VERSION ""

NS_ :

BS_:

BU_: DSAU vHS_M SHVU_RR DPSS AMP ICC RLPSM APSM RWPC RRHV RRPSM CGW_CCU APSS ATS RLHV FPM RDC PSM ASAU

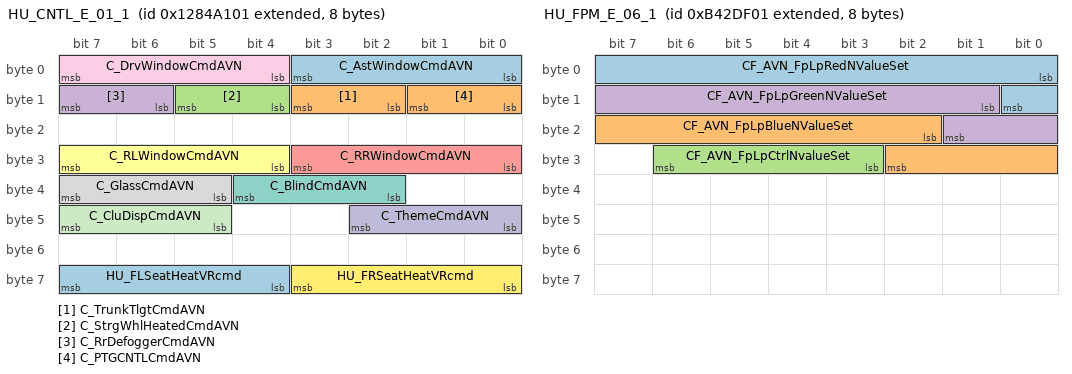
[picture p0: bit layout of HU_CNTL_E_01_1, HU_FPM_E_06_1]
BO_ 2458165505 HU_CNTL_E_01_1: 8 CGW_CCU
 SG_ C_AstWindowCmdAVN : 0|4@1+ (1,0) [0|0] ""  Vector__XXX
 SG_ C_TrunkTlgtCmdAVN : 10|2@1+ (1,0) [0|0] ""  Vector__XXX
 SG_ C_StrgWhlHeatedCmdAVN : 12|2@1+ (1,0) [0|0] ""  Vector__XXX
 SG_ C_RrDefoggerCmdAVN : 14|2@1+ (1,0) [0|0] ""  Vector__XXX
 SG_ C_RRWindowCmdAVN : 24|4@1+ (1,0) [0|0] ""  RDC
 SG_ C_RLWindowCmdAVN : 28|4@1+ (1,0) [0|0] ""  RDC
 SG_ C_BlindCmdAVN : 34|3@1+ (1,0) [0|0] ""  Vector__XXX
 SG_ C_GlassCmdAVN : 37|3@1+ (1,0) [0|0] ""  Vector__XXX
 SG_ C_DrvWindowCmdAVN : 4|4@1+ (1,0) [0|0] ""  Vector__XXX
 SG_ C_ThemeCmdAVN : 40|3@1+ (1,0) [0|0] ""  Vector__XXX
 SG_ C_CluDispCmdAVN : 45|3@1+ (1,0) [0|0] ""  Vector__XXX
 SG_ HU_FRSeatHeatVRcmd : 56|4@1+ (1,0) [0|0] ""  SHVU_RR,DPSS,ATS
 SG_ HU_FLSeatHeatVRcmd : 60|4@1+ (1,0) [0|0] ""  DPSS,ATS
 SG_ C_PTGCNTLCmdAVN : 8|2@1+ (1,0) [0|0] ""  Vector__XXX

BO_ 2336415489 HU_FPM_E_06_1: 8 CGW_CCU
 SG_ CF_AVN_FpLpRedNValueSet : 0|9@1+ (1,0) [0|0] ""  FPM
 SG_ CF_AVN_FpLpBlueNValueSet : 18|9@1+ (1,0) [0|0] ""  FPM
 SG_ CF_AVN_FpLpCtrlNvalueSet : 27|4@1+ (1,0) [0|0] ""  FPM
 SG_ CF_AVN_FpLpGreenNValueSet : 9|9@1+ (1,0) [0|0] ""  FPM

BO_ 2315420417 HU_FPM_E_03_1: 8 CGW_CCU
 SG_ AVN_Encrypted_Result3 : 0|64@1+ (1,0) [0|0] ""  FPM

BO_ 858 SBCM_AST_02_200ms: 8 CGW_CCU
 SG_ SBCM_AST_Crc2Val : 0|8@1+ (1,0) [0|0] ""  Vector__XXX
 SG_ AST_CrashUnlockCmd : 10|1@1+ (1,0) [0|0] ""  Vector__XXX
 SG_ SBCM_AST_AlvCnt2Val : 12|4@1+ (1,0) [0|0] ""  Vector__XXX
 SG_ DoorLock_CtrlDrLkSwSta_SBCM : 16|2@1+ (1,0) [0|0] ""  Vector__XXX
 SG_ DoorLock_CtrlDrUnLkSwSta_SBCM : 18|2@1+ (1,0) [0|0] ""  Vector__XXX
 SG_ Warn_AsstDrSwSta_SBCM : 20|2@1+ (1,0) [0|0] ""  RWPC,APSM,AMP,ATS
 SG_ DoorLock_AsstDrUnLkSta_SBCM : 22|2@1+ (1,0) [0|0] ""  ATS
 SG_ AST_SEAWarn_RH : 24|2@1+ (1,0) [0|0] ""  AMP
 SG_ AST_SEAWarn_LH : 26|2@1+ (1,0) [0|0] ""  AMP
 SG_ AST_SEWWarn_LH : 28|2@1+ (1,0) [0|0] ""  AMP
 SG_ AST_SEWWarn_RH : 30|2@1+ (1,0) [0|0] ""  AMP
 SG_ AST_MRActivationAlarm : 32|2@1+ (1,0) [0|0] ""  Vector__XXX
 SG_ AST_ReleaseWarn : 34|2@1+ (1,0) [0|0] ""  Vector__XXX
 SG_ USM_AstGhostDoorSta : 36|2@1+ (1,0) [0|0] ""  Vector__XXX
 SG_ AST_SWFailAlarm : 38|2@1+ (1,0) [0|0] ""  Vector__XXX
 SG_ DoorLock_PDSLkSwSta_AST : 40|2@1+ (1,0) [0|0] ""  AMP
 SG_ PDS_TypeOption_AST : 42|2@1+ (1,0) [0|0] ""  Vector__XXX
 SG_ ASTDoorPushAlarm : 8|2@1+ (1,0) [0|0] ""  Vector__XXX

BO_ 383 FPM_05_00ms: 8 FPM
 SG_ FPM_Encrypted_Result4 : 0|64@1+ (1,0) [0|0] ""  CGW_CCU

BO_ 862 SBCM_RL_01_200ms: 8 CGW_CCU
 SG_ SBCM_RL_Crc1Val : 0|8@1+ (1,0) [0|0] ""  Vector__XXX
 SG_ RL_CrashUnlockCmd : 10|1@1+ (1,0) [0|0] ""  Vector__XXX
 SG_ SBCM_RL_AlvCnt1Val : 12|4@1+ (1,0) [0|0] ""  Vector__XXX
 SG_ Warn_RrLftDrSwSta_SBCM : 16|2@1+ (1,0) [0|0] ""  RWPC,RLPSM,AMP,ATS
 SG_ DoorLock_RrLftDrUnLkSta_SBCM : 18|2@1+ (1,0) [0|0] ""  ATS
 SG_ RL_SEAActivated : 20|2@1+ (1,0) [0|0] ""  Vector__XXX
 SG_ RL_SEAWarn : 22|2@1+ (1,0) [0|0] ""  AMP
 SG_ RL_SEWWarn : 24|2@1+ (1,0) [0|0] ""  AMP
 SG_ RL_ReleaseWarn : 26|2@1+ (1,0) [0|0] ""  Vector__XXX
 SG_ RL_SWFailAlarm : 28|2@1+ (1,0) [0|0] ""  Vector__XXX
 SG_ RL_ChildLock_ActnFlSta : 30|2@1+ (1,0) [0|0] ""  Vector__XXX
 SG_ RL_MRActivationAlarm : 32|2@1+ (1,0) [0|0] ""  Vector__XXX
 SG_ RL_ChildLock_Status : 34|2@1+ (1,0) [0|0] ""  Vector__XXX
 SG_ USM_RLGhostDoorSta : 36|2@1+ (1,0) [0|0] ""  Vector__XXX
 SG_ DoorLock_PDSLkSwSta_RL : 40|2@1+ (1,0) [0|0] ""  AMP
 SG_ PDS_TypeOption_RL : 42|2@1+ (1,0) [0|0] ""  Vector__XXX
 SG_ SBCM_RrLtClsSwSta : 44|2@1+ (1,0) [0|0] ""  Vector__XXX
 SG_ RLDoorPushAlarm : 8|2@1+ (1,0) [0|0] ""  Vector__XXX

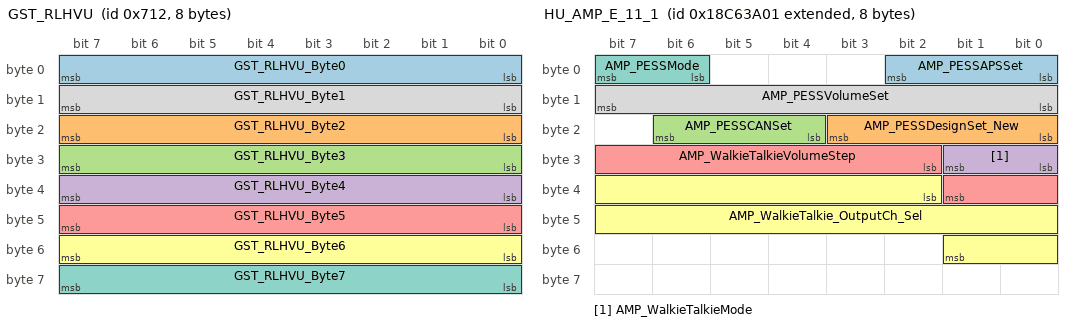
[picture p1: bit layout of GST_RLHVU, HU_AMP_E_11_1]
BO_ 1810 GST_RLHVU: 8 CGW_CCU
 SG_ GST_RLHVU_Byte0 : 0|8@1+ (1,0) [0|0] ""  RLHV,vHS_M
 SG_ GST_RLHVU_Byte2 : 16|8@1+ (1,0) [0|0] ""  RLHV,vHS_M
 SG_ GST_RLHVU_Byte3 : 24|8@1+ (1,0) [0|0] ""  RLHV,vHS_M
 SG_ GST_RLHVU_Byte4 : 32|8@1+ (1,0) [0|0] ""  RLHV,vHS_M
 SG_ GST_RLHVU_Byte5 : 40|8@1+ (1,0) [0|0] ""  RLHV,vHS_M
 SG_ GST_RLHVU_Byte6 : 48|8@1+ (1,0) [0|0] ""  RLHV,vHS_M
 SG_ GST_RLHVU_Byte7 : 56|8@1+ (1,0) [0|0] ""  RLHV,vHS_M
 SG_ GST_RLHVU_Byte1 : 8|8@1+ (1,0) [0|0] ""  RLHV,vHS_M

BO_ 2563127809 HU_AMP_E_11_1: 8 CGW_CCU
 SG_ AMP_PESSAPSSet : 0|3@1+ (1,0) [0|0] ""  Vector__XXX
 SG_ AMP_PESSDesignSet_New : 16|4@1+ (1,0) [0|0] ""  Vector__XXX
 SG_ AMP_PESSCANSet : 20|3@1+ (1,0) [0|0] ""  Vector__XXX
 SG_ AMP_WalkieTalkieMode : 24|2@1+ (1,0) [0|0] ""  AMP
 SG_ AMP_WalkieTalkieVolumeStep : 26|8@1+ (1,0) [0|0] ""  AMP
 SG_ AMP_WalkieTalkie_OutputCh_Sel : 34|16@1+ (1,0) [0|0] ""  AMP
 SG_ AMP_PESSMode : 6|2@1+ (1,0) [0|0] ""  Vector__XXX
 SG_ AMP_PESSVolumeSet : 8|8@1+ (1,0) [0|0] ""  Vector__XXX

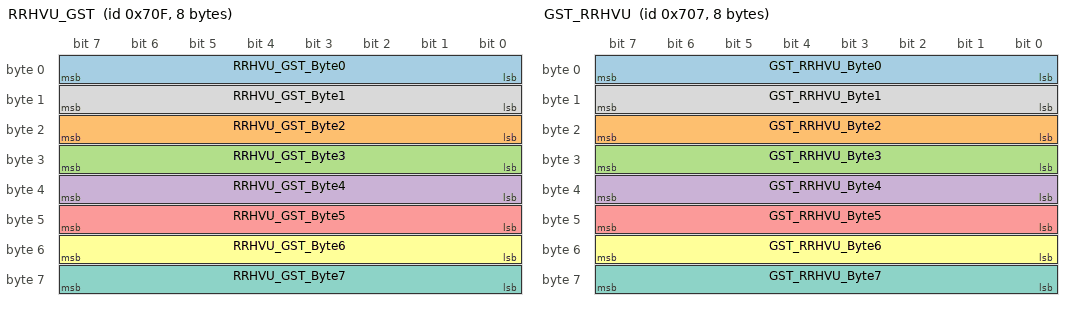
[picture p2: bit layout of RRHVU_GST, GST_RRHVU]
BO_ 1807 RRHVU_GST: 8 vHS_M
 SG_ RRHVU_GST_Byte0 : 0|8@1+ (1,0) [0|0] ""  CGW_CCU
 SG_ RRHVU_GST_Byte2 : 16|8@1+ (1,0) [0|0] ""  CGW_CCU
 SG_ RRHVU_GST_Byte3 : 24|8@1+ (1,0) [0|0] ""  CGW_CCU
 SG_ RRHVU_GST_Byte4 : 32|8@1+ (1,0) [0|0] ""  CGW_CCU
 SG_ RRHVU_GST_Byte5 : 40|8@1+ (1,0) [0|0] ""  CGW_CCU
 SG_ RRHVU_GST_Byte6 : 48|8@1+ (1,0) [0|0] ""  CGW_CCU
 SG_ RRHVU_GST_Byte7 : 56|8@1+ (1,0) [0|0] ""  CGW_CCU
 SG_ RRHVU_GST_Byte1 : 8|8@1+ (1,0) [0|0] ""  CGW_CCU

BO_ 1799 GST_RRHVU: 8 CGW_CCU
 SG_ GST_RRHVU_Byte0 : 0|8@1+ (1,0) [0|0] ""  RRHV,SHVU_RR,vHS_M
 SG_ GST_RRHVU_Byte2 : 16|8@1+ (1,0) [0|0] ""  RRHV,SHVU_RR,vHS_M
 SG_ GST_RRHVU_Byte3 : 24|8@1+ (1,0) [0|0] ""  RRHV,SHVU_RR,vHS_M
 SG_ GST_RRHVU_Byte4 : 32|8@1+ (1,0) [0|0] ""  RRHV,SHVU_RR,vHS_M
 SG_ GST_RRHVU_Byte5 : 40|8@1+ (1,0) [0|0] ""  RRHV,SHVU_RR,vHS_M
 SG_ GST_RRHVU_Byte6 : 48|8@1+ (1,0) [0|0] ""  RRHV,SHVU_RR,vHS_M
 SG_ GST_RRHVU_Byte7 : 56|8@1+ (1,0) [0|0] ""  RRHV,SHVU_RR,vHS_M
 SG_ GST_RRHVU_Byte1 : 8|8@1+ (1,0) [0|0] ""  RRHV,SHVU_RR,vHS_M

BO_ 367 FPM_04_00ms: 8 FPM
 SG_ FPM2IAU_ISKLearnFdbck : 0|4@1+ (1,0) [0|0] ""  CGW_CCU

BO_ 415 FPM_07_200ms: 8 FPM
 SG_ FPM_FPFuntionEnableRValue : 0|2@1+ (1,0) [0|0] ""  CGW_CCU
 SG_ FPM_User2_SecondFPRValue : 10|2@1+ (1,0) [0|0] ""  CGW_CCU
 SG_ FPM_User2_ThirdFPRValue : 12|2@1+ (1,0) [0|0] ""  CGW_CCU
 SG_ FPM_FPEnrollState : 16|4@1+ (1,0) [0|0] ""  CGW_CCU
 SG_ FPM_User1_FirstFPRValue : 2|2@1+ (1,0) [0|0] ""  CGW_CCU
 SG_ FPM_FPDeleteState : 20|2@1+ (1,0) [0|0] ""  CGW_CCU
 SG_ FPM_EnrollProgress : 24|8@1+ (1,0) [0|0] ""  CGW_CCU
 SG_ FPM_ISKLearnState : 33|3@1+ (1,0) [0|0] ""  CGW_CCU
 SG_ FPM_ReadyToSendData : 36|2@1+ (1,0) [0|0] ""  CGW_CCU
 SG_ FPM_Option : 38|2@1+ (1,0) [0|0] ""  CGW_CCU
 SG_ FPM_User1_SecondFPRValue : 4|2@1+ (1,0) [0|0] ""  CGW_CCU
 SG_ FPMwIAULearnState : 40|3@1+ (1,0) [0|0] ""  CGW_CCU
 SG_ FPM_DISPWrng : 43|5@1+ (1,0) [0|0] ""  CGW_CCU
 SG_ FPM2IAU_RdyToSendAuthData : 48|2@1+ (1,0) [0|0] ""  CGW_CCU
 SG_ FPM_FPStartUseRvalue : 50|2@1+ (1,0) [0|0] ""  CGW_CCU
 SG_ FPM_FPStartUseState : 52|2@1+ (1,0) [0|0] ""  CGW_CCU
 SG_ FPM_User1_ThirdFPRValue : 6|2@1+ (1,0) [0|0] ""  CGW_CCU
 SG_ FPM_User2_FirstFPRValue : 8|2@1+ (1,0) [0|0] ""  CGW_CCU

BO_ 2319620609 HUD_01_100ms_1: 8 CGW_CCU
 SG_ HUD_PbackSta : 29|3@1+ (1,0) [0|0] ""  PSM

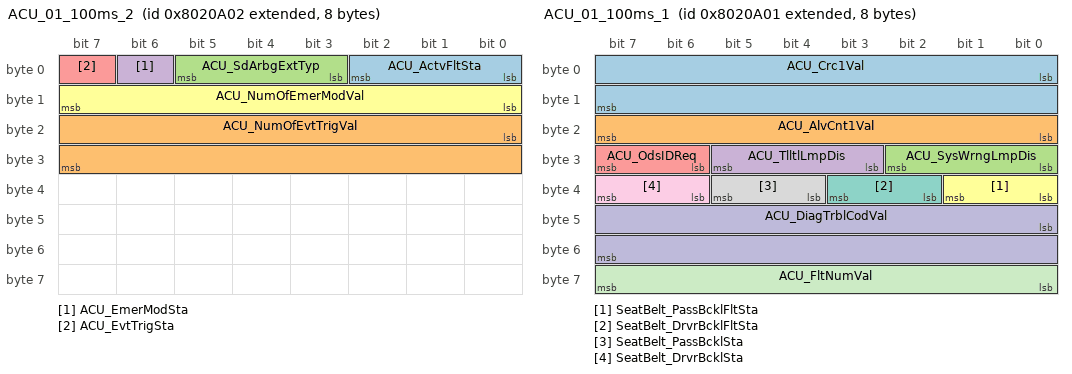
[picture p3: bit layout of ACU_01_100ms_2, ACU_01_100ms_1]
BO_ 2281835010 ACU_01_100ms_2: 8 CGW_CCU
 SG_ ACU_ActvFltSta : 0|3@1+ (1,0) [0|0] ""  Vector__XXX
 SG_ ACU_NumOfEvtTrigVal : 16|16@1+ (1,0) [0|0] ""  Vector__XXX
 SG_ ACU_SdArbgExtTyp : 3|3@1+ (1,0) [0|0] ""  Vector__XXX
 SG_ ACU_EmerModSta : 6|1@1+ (1,0) [0|0] ""  Vector__XXX
 SG_ ACU_EvtTrigSta : 7|1@1+ (1,0) [0|0] ""  Vector__XXX
 SG_ ACU_NumOfEmerModVal : 8|8@1+ (1,0) [0|0] ""  Vector__XXX

BO_ 2281835009 ACU_01_100ms_1: 8 CGW_CCU
 SG_ ACU_Crc1Val : 0|16@1+ (1,0) [0|0] ""  Vector__XXX
 SG_ ACU_AlvCnt1Val : 16|8@1+ (1,0) [0|0] ""  Vector__XXX
 SG_ ACU_SysWrngLmpDis : 24|3@1+ (1,0) [0|0] ""  Vector__XXX
 SG_ ACU_TlltlLmpDis : 27|3@1+ (1,0) [0|0] ""  Vector__XXX
 SG_ ACU_OdsIDReq : 30|2@1+ (1,0) [0|0] ""  Vector__XXX
 SG_ SeatBelt_PassBcklFltSta : 32|2@1+ (1,0) [0|0] ""  Vector__XXX
 SG_ SeatBelt_DrvrBcklFltSta : 34|2@1+ (1,0) [0|0] ""  Vector__XXX
 SG_ SeatBelt_PassBcklSta : 36|2@1+ (1,0) [0|0] ""  APSM,ATS
 SG_ SeatBelt_DrvrBcklSta : 38|2@1+ (1,0) [0|0] ""  PSM
 SG_ ACU_DiagTrblCodVal : 40|16@1+ (1,0) [0|0] ""  Vector__XXX
 SG_ ACU_FltNumVal : 56|8@1+ (1,0) [0|0] ""  Vector__XXX

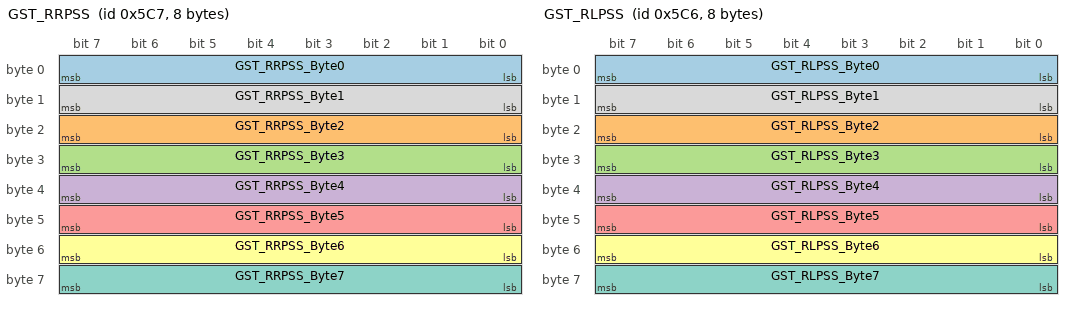
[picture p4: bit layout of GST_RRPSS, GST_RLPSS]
BO_ 1479 GST_RRPSS: 8 CGW_CCU
 SG_ GST_RRPSS_Byte0 : 0|8@1+ (1,0) [0|0] ""  RLPSM,vHS_M
 SG_ GST_RRPSS_Byte2 : 16|8@1+ (1,0) [0|0] ""  RLPSM,vHS_M
 SG_ GST_RRPSS_Byte3 : 24|8@1+ (1,0) [0|0] ""  RLPSM,vHS_M
 SG_ GST_RRPSS_Byte4 : 32|8@1+ (1,0) [0|0] ""  RLPSM,vHS_M
 SG_ GST_RRPSS_Byte5 : 40|8@1+ (1,0) [0|0] ""  RLPSM,vHS_M
 SG_ GST_RRPSS_Byte6 : 48|8@1+ (1,0) [0|0] ""  RLPSM,vHS_M
 SG_ GST_RRPSS_Byte7 : 56|8@1+ (1,0) [0|0] ""  RLPSM,vHS_M
 SG_ GST_RRPSS_Byte1 : 8|8@1+ (1,0) [0|0] ""  RLPSM,vHS_M

BO_ 1478 GST_RLPSS: 8 CGW_CCU
 SG_ GST_RLPSS_Byte0 : 0|8@1+ (1,0) [0|0] ""  RLPSM,vHS_M
 SG_ GST_RLPSS_Byte2 : 16|8@1+ (1,0) [0|0] ""  RLPSM,vHS_M
 SG_ GST_RLPSS_Byte3 : 24|8@1+ (1,0) [0|0] ""  RLPSM,vHS_M
 SG_ GST_RLPSS_Byte4 : 32|8@1+ (1,0) [0|0] ""  RLPSM,vHS_M
 SG_ GST_RLPSS_Byte5 : 40|8@1+ (1,0) [0|0] ""  RLPSM,vHS_M
 SG_ GST_RLPSS_Byte6 : 48|8@1+ (1,0) [0|0] ""  RLPSM,vHS_M
 SG_ GST_RLPSS_Byte7 : 56|8@1+ (1,0) [0|0] ""  RLPSM,vHS_M
 SG_ GST_RLPSS_Byte1 : 8|8@1+ (1,0) [0|0] ""  RLPSM,vHS_M

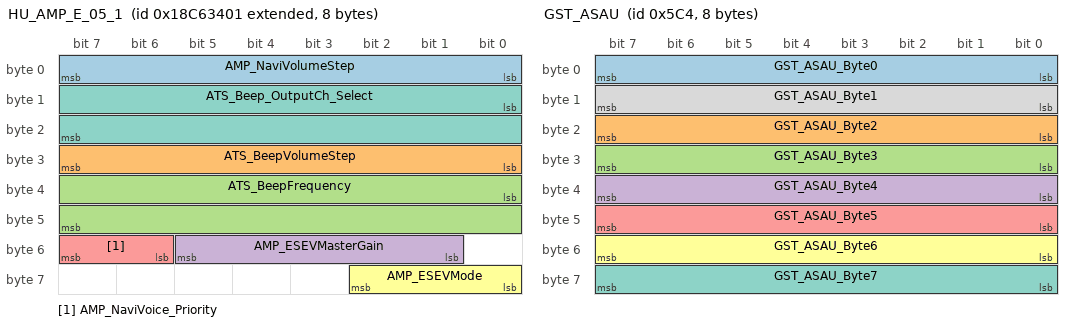
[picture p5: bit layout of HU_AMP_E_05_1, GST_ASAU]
BO_ 2563126273 HU_AMP_E_05_1: 8 CGW_CCU
 SG_ AMP_NaviVolumeStep : 0|8@1+ (1,0) [0|0] ""  AMP
 SG_ ATS_BeepVolumeStep : 24|8@1+ (1,0) [0|0] ""  AMP
 SG_ ATS_BeepFrequency : 32|16@1+ (1,0) [0|0] "Hz"  AMP
 SG_ AMP_ESEVMasterGain : 49|5@1+ (0.5,-8) [0|0] ""  AMP
 SG_ AMP_NaviVoice_Priority : 54|2@1+ (1,0) [0|0] ""  AMP
 SG_ AMP_ESEVMode : 56|3@1+ (1,0) [0|0] ""  AMP
 SG_ ATS_Beep_OutputCh_Select : 8|16@1+ (1,0) [0|0] ""  AMP

BO_ 1476 GST_ASAU: 8 CGW_CCU
 SG_ GST_ASAU_Byte0 : 0|8@1+ (1,0) [0|0] ""  vHS_M,ASAU
 SG_ GST_ASAU_Byte2 : 16|8@1+ (1,0) [0|0] ""  vHS_M,ASAU
 SG_ GST_ASAU_Byte3 : 24|8@1+ (1,0) [0|0] ""  vHS_M,ASAU
 SG_ GST_ASAU_Byte4 : 32|8@1+ (1,0) [0|0] ""  vHS_M,ASAU
 SG_ GST_ASAU_Byte5 : 40|8@1+ (1,0) [0|0] ""  vHS_M,ASAU
 SG_ GST_ASAU_Byte6 : 48|8@1+ (1,0) [0|0] ""  vHS_M,ASAU
 SG_ GST_ASAU_Byte7 : 56|8@1+ (1,0) [0|0] ""  vHS_M,ASAU
 SG_ GST_ASAU_Byte1 : 8|8@1+ (1,0) [0|0] ""  vHS_M,ASAU

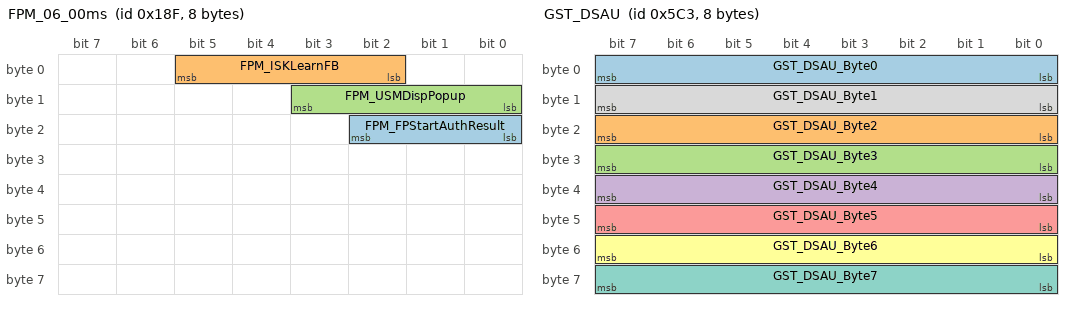
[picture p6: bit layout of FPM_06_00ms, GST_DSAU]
BO_ 399 FPM_06_00ms: 8 FPM
 SG_ FPM_FPStartAuthResult : 16|3@1+ (1,0) [0|0] ""  CGW_CCU
 SG_ FPM_ISKLearnFB : 2|4@1+ (1,0) [0|0] ""  CGW_CCU
 SG_ FPM_USMDispPopup : 8|4@1+ (1,0) [0|0] ""  CGW_CCU

BO_ 1475 GST_DSAU: 8 CGW_CCU
 SG_ GST_DSAU_Byte0 : 0|8@1+ (1,0) [0|0] ""  vHS_M,DSAU
 SG_ GST_DSAU_Byte2 : 16|8@1+ (1,0) [0|0] ""  vHS_M,DSAU
 SG_ GST_DSAU_Byte3 : 24|8@1+ (1,0) [0|0] ""  vHS_M,DSAU
 SG_ GST_DSAU_Byte4 : 32|8@1+ (1,0) [0|0] ""  vHS_M,DSAU
 SG_ GST_DSAU_Byte5 : 40|8@1+ (1,0) [0|0] ""  vHS_M,DSAU
 SG_ GST_DSAU_Byte6 : 48|8@1+ (1,0) [0|0] ""  vHS_M,DSAU
 SG_ GST_DSAU_Byte7 : 56|8@1+ (1,0) [0|0] ""  vHS_M,DSAU
 SG_ GST_DSAU_Byte1 : 8|8@1+ (1,0) [0|0] ""  vHS_M,DSAU

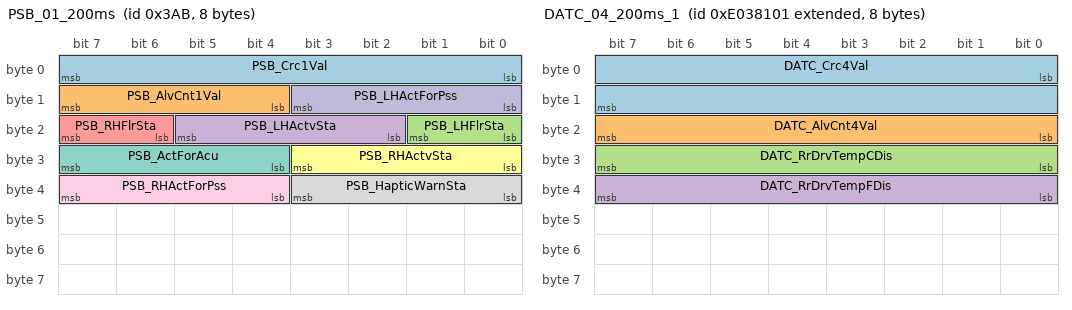
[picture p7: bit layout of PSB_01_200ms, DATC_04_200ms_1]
BO_ 939 PSB_01_200ms: 8 CGW_CCU
 SG_ PSB_Crc1Val : 0|8@1+ (1,0) [0|0] ""  Vector__XXX
 SG_ PSB_AlvCnt1Val : 12|4@1+ (1,0) [0|0] ""  Vector__XXX
 SG_ PSB_LHFlrSta : 16|2@1+ (1,0) [0|0] ""  Vector__XXX
 SG_ PSB_LHActvSta : 18|4@1+ (1,0) [0|0] ""  Vector__XXX
 SG_ PSB_RHFlrSta : 22|2@1+ (1,0) [0|0] ""  Vector__XXX
 SG_ PSB_RHActvSta : 24|4@1+ (1,0) [0|0] ""  Vector__XXX
 SG_ PSB_ActForAcu : 28|4@1+ (1,0) [0|0] ""  Vector__XXX
 SG_ PSB_HapticWarnSta : 32|4@1+ (1,0) [0|0] ""  Vector__XXX
 SG_ PSB_RHActForPss : 36|4@1+ (1,0) [0|0] ""  APSM,RLPSM,RRPSM
 SG_ PSB_LHActForPss : 8|4@1+ (1,0) [0|0] ""  RLPSM,RRPSM

BO_ 2382594305 DATC_04_200ms_1: 8 CGW_CCU
 SG_ DATC_Crc4Val : 0|16@1+ (1,0) [0|0] ""  Vector__XXX
 SG_ DATC_AlvCnt4Val : 16|8@1+ (1,0) [0|0] ""  Vector__XXX
 SG_ DATC_RrDrvTempCDis : 24|8@1+ (0.5,14) [0|0] "℃"  ATS
 SG_ DATC_RrDrvTempFDis : 32|8@1+ (1,56) [0|0] "℉"  ATS

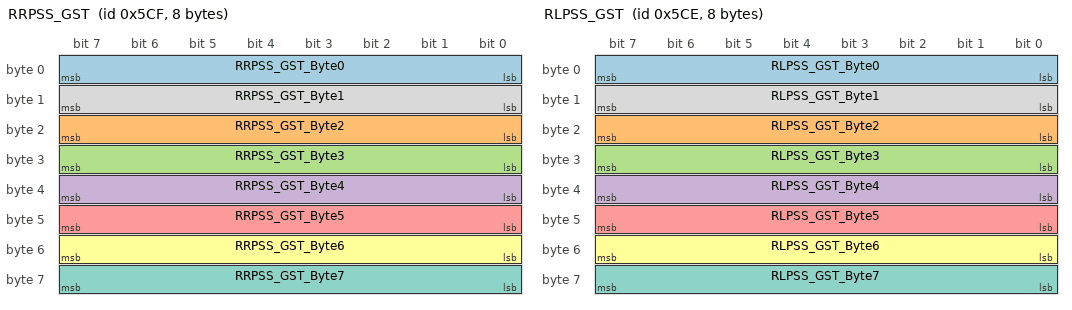
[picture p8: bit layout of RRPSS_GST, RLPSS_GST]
BO_ 1487 RRPSS_GST: 8 vHS_M
 SG_ RRPSS_GST_Byte0 : 0|8@1+ (1,0) [0|0] ""  CGW_CCU
 SG_ RRPSS_GST_Byte2 : 16|8@1+ (1,0) [0|0] ""  CGW_CCU
 SG_ RRPSS_GST_Byte3 : 24|8@1+ (1,0) [0|0] ""  CGW_CCU
 SG_ RRPSS_GST_Byte4 : 32|8@1+ (1,0) [0|0] ""  CGW_CCU
 SG_ RRPSS_GST_Byte5 : 40|8@1+ (1,0) [0|0] ""  CGW_CCU
 SG_ RRPSS_GST_Byte6 : 48|8@1+ (1,0) [0|0] ""  CGW_CCU
 SG_ RRPSS_GST_Byte7 : 56|8@1+ (1,0) [0|0] ""  CGW_CCU
 SG_ RRPSS_GST_Byte1 : 8|8@1+ (1,0) [0|0] ""  CGW_CCU

BO_ 1486 RLPSS_GST: 8 RLPSM
 SG_ RLPSS_GST_Byte0 : 0|8@1+ (1,0) [0|0] ""  CGW_CCU
 SG_ RLPSS_GST_Byte2 : 16|8@1+ (1,0) [0|0] ""  CGW_CCU
 SG_ RLPSS_GST_Byte3 : 24|8@1+ (1,0) [0|0] ""  CGW_CCU
 SG_ RLPSS_GST_Byte4 : 32|8@1+ (1,0) [0|0] ""  CGW_CCU
 SG_ RLPSS_GST_Byte5 : 40|8@1+ (1,0) [0|0] ""  CGW_CCU
 SG_ RLPSS_GST_Byte6 : 48|8@1+ (1,0) [0|0] ""  CGW_CCU
 SG_ RLPSS_GST_Byte7 : 56|8@1+ (1,0) [0|0] ""  CGW_CCU
 SG_ RLPSS_GST_Byte1 : 8|8@1+ (1,0) [0|0] ""  CGW_CCU

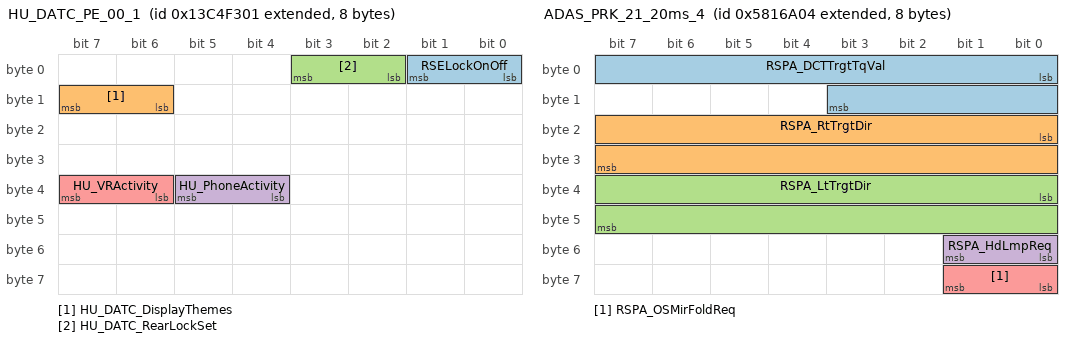
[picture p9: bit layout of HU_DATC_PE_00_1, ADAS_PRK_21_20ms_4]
BO_ 2479158017 HU_DATC_PE_00_1: 8 CGW_CCU
 SG_ RSELockOnOff : 0|2@1+ (1,0) [0|0] ""  ATS
 SG_ HU_DATC_DisplayThemes : 14|2@1+ (1,0) [0|0] ""  Vector__XXX
 SG_ HU_DATC_RearLockSet : 2|2@1+ (1,0) [0|0] ""  Vector__XXX
 SG_ HU_PhoneActivity : 36|2@1+ (1,0) [0|0] ""  Vector__XXX
 SG_ HU_VRActivity : 38|2@1+ (1,0) [0|0] ""  Vector__XXX

BO_ 2239851012 ADAS_PRK_21_20ms_4: 8 CGW_CCU
 SG_ RSPA_DCTTrgtTqVal : 0|12@1- (1,0) [0|0] "Nm"  Vector__XXX
 SG_ RSPA_RtTrgtDir : 16|16@1- (0.001,0) [0|0] "rad"  Vector__XXX
 SG_ RSPA_LtTrgtDir : 32|16@1- (0.001,0) [0|0] "rad"  Vector__XXX
 SG_ RSPA_HdLmpReq : 48|2@1+ (1,0) [0|0] ""  Vector__XXX
 SG_ RSPA_OSMirFoldReq : 56|2@1+ (1,0) [0|0] ""  Vector__XXX

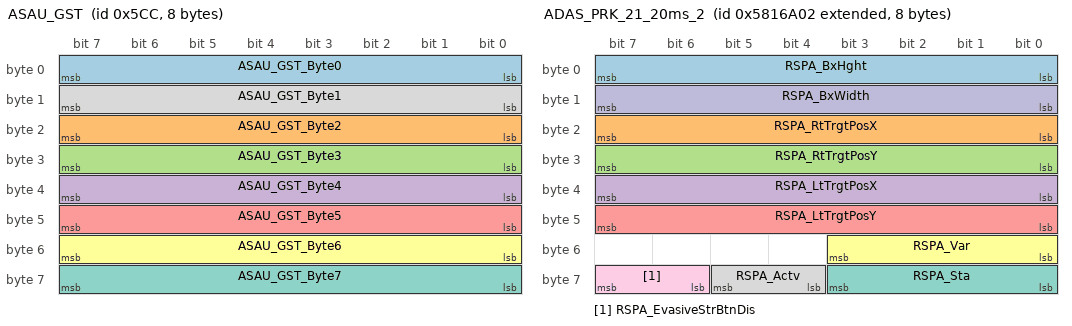
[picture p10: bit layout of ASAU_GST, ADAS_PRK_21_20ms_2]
BO_ 1484 ASAU_GST: 8 ASAU
 SG_ ASAU_GST_Byte0 : 0|8@1+ (1,0) [0|0] ""  CGW_CCU
 SG_ ASAU_GST_Byte2 : 16|8@1+ (1,0) [0|0] ""  CGW_CCU
 SG_ ASAU_GST_Byte3 : 24|8@1+ (1,0) [0|0] ""  CGW_CCU
 SG_ ASAU_GST_Byte4 : 32|8@1+ (1,0) [0|0] ""  CGW_CCU
 SG_ ASAU_GST_Byte5 : 40|8@1+ (1,0) [0|0] ""  CGW_CCU
 SG_ ASAU_GST_Byte6 : 48|8@1+ (1,0) [0|0] ""  CGW_CCU
 SG_ ASAU_GST_Byte7 : 56|8@1+ (1,0) [0|0] ""  CGW_CCU
 SG_ ASAU_GST_Byte1 : 8|8@1+ (1,0) [0|0] ""  CGW_CCU

BO_ 2239851010 ADAS_PRK_21_20ms_2: 8 CGW_CCU
 SG_ RSPA_BxHght : 0|8@1+ (10,3500) [0|0] ""  Vector__XXX
 SG_ RSPA_RtTrgtPosX : 16|8@1- (0.05,0) [0|0] "m"  Vector__XXX
 SG_ RSPA_RtTrgtPosY : 24|8@1- (0.05,0) [0|0] "m"  Vector__XXX
 SG_ RSPA_LtTrgtPosX : 32|8@1- (0.05,0) [0|0] "m"  Vector__XXX
 SG_ RSPA_LtTrgtPosY : 40|8@1- (0.05,0) [0|0] "m"  Vector__XXX
 SG_ RSPA_Var : 48|4@1+ (1,0) [0|0] ""  Vector__XXX
 SG_ RSPA_Sta : 56|4@1+ (1,0) [0|0] ""  Vector__XXX
 SG_ RSPA_Actv : 60|2@1+ (1,0) [0|0] ""  Vector__XXX
 SG_ RSPA_EvasiveStrBtnDis : 62|2@1+ (1,0) [0|0] ""  Vector__XXX
 SG_ RSPA_BxWidth : 8|8@1+ (5,1000) [0|0] ""  Vector__XXX

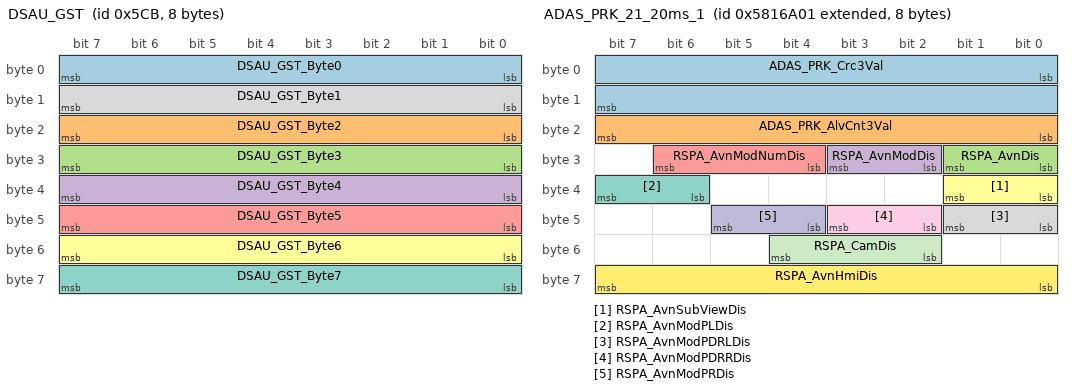
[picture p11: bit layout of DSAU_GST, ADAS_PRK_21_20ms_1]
BO_ 1483 DSAU_GST: 8 vHS_M
 SG_ DSAU_GST_Byte0 : 0|8@1+ (1,0) [0|0] ""  CGW_CCU
 SG_ DSAU_GST_Byte2 : 16|8@1+ (1,0) [0|0] ""  CGW_CCU
 SG_ DSAU_GST_Byte3 : 24|8@1+ (1,0) [0|0] ""  CGW_CCU
 SG_ DSAU_GST_Byte4 : 32|8@1+ (1,0) [0|0] ""  CGW_CCU
 SG_ DSAU_GST_Byte5 : 40|8@1+ (1,0) [0|0] ""  CGW_CCU
 SG_ DSAU_GST_Byte6 : 48|8@1+ (1,0) [0|0] ""  CGW_CCU
 SG_ DSAU_GST_Byte7 : 56|8@1+ (1,0) [0|0] ""  CGW_CCU
 SG_ DSAU_GST_Byte1 : 8|8@1+ (1,0) [0|0] ""  CGW_CCU

BO_ 2298626305 HU_APSU_PE_02_1: 8 CGW_CCU
 SG_ C_AstBolsterInfSw_HU : 0|2@1+ (1,0) [0|0] ""  APSS,ASAU
 SG_ C_RLHrestUpSw_HU : 14|2@1+ (1,0) [0|0] ""  RLPSM
 SG_ C_RLHrestDnSw_HU : 16|2@1+ (1,0) [0|0] ""  RLPSM
 SG_ C_RLHrestFwdSw_HU : 18|2@1+ (1,0) [0|0] ""  RLPSM
 SG_ C_AstBolsterDefSw_HU : 2|2@1+ (1,0) [0|0] ""  APSS,ASAU
 SG_ C_RLHrestBwdSw_HU : 20|2@1+ (1,0) [0|0] ""  RLPSM
 SG_ C_RLLumbarUpSw_HU : 22|2@1+ (1,0) [0|0] ""  RLPSM
 SG_ C_RLLumbarMidSw_HU : 24|2@1+ (1,0) [0|0] ""  RLPSM
 SG_ C_RLLumbarLowSw_HU : 26|2@1+ (1,0) [0|0] ""  RLPSM
 SG_ C_RLLumbarDefSw_HU : 28|2@1+ (1,0) [0|0] ""  RLPSM
 SG_ C_RLBolsterInfSw_HU : 30|2@1+ (1,0) [0|0] ""  RLPSM
 SG_ C_RLBolsterDefSw_HU : 32|2@1+ (1,0) [0|0] ""  RLPSM
 SG_ C_AstHrestUpSw_HU : 36|2@1+ (1,0) [0|0] ""  APSM,APSS
 SG_ C_AstHrestDnSw_HU : 38|2@1+ (1,0) [0|0] ""  APSM,APSS
 SG_ C_AstFootrestFldSw_HU : 4|2@1+ (1,0) [0|0] ""  APSM,APSS
 SG_ C_AstHrestFwdSw_HU : 46|2@1+ (1,0) [0|0] ""  APSM,APSS
 SG_ C_AstHrestBwdSw_HU : 54|2@1+ (1,0) [0|0] ""  APSM,APSS
 SG_ C_AstFootrestUnFldSw_HU : 6|2@1+ (1,0) [0|0] ""  APSM,APSS

BO_ 2239851011 ADAS_PRK_21_20ms_3: 8 CGW_CCU
 SG_ RSPA_TrgtGearSta : 0|3@1+ (1,0) [0|0] ""  Vector__XXX
 SG_ RSPA_IdOutWarnReq : 10|2@1+ (1,0) [0|0] ""  PSM
 SG_ RSPA_IndBlnkReq : 12|3@1+ (1,0) [0|0] ""  Vector__XXX
 SG_ RSPA_SysOff : 15|1@1+ (1,0) [0|0] ""  Vector__XXX
 SG_ RSPA_DccCmd : 16|2@1+ (1,0) [0|0] ""  Vector__XXX
 SG_ RSPA_StopReq : 18|2@1+ (1,0) [0|0] ""  Vector__XXX
 SG_ RSPA_SelDevInfo : 20|2@1+ (1,0) [0|0] ""  Vector__XXX
 SG_ RSPA_SelFuncInfo : 22|2@1+ (1,0) [0|0] ""  Vector__XXX
 SG_ RSPA_TrgtVehSpdVal : 24|10@1+ (0.01,0) [0|0] "km/h"  Vector__XXX
 SG_ RSPA_EpbReq : 3|2@1+ (1,0) [0|0] ""  Vector__XXX
 SG_ RSPA_AddtnlAccelActv : 34|2@1+ (1,0) [0|0] ""  Vector__XXX
 SG_ RSPA_Opt : 36|2@1+ (1,0) [0|0] ""  Vector__XXX
 SG_ RSPA_RmtPrlExitDis : 38|2@1+ (1,0) [0|0] ""  Vector__XXX
 SG_ RSPA_TrgtTqVal : 40|12@1- (1,0) [0|0] "Nm"  Vector__XXX
 SG_ RSPA_ExtLampReq : 5|3@1+ (1,0) [0|0] ""  Vector__XXX
 SG_ RSPA_UppLtTypDis : 52|3@1+ (1,0) [0|0] ""  Vector__XXX
 SG_ RSPA_LwrLtTypDis : 55|3@1+ (1,0) [0|0] ""  Vector__XXX
 SG_ RSPA_UppRtTypDis : 58|3@1+ (1,0) [0|0] ""  Vector__XXX
 SG_ RSPA_LwrRtTypDis : 61|3@1+ (1,0) [0|0] ""  Vector__XXX
 SG_ RSPA_CrankingReq : 8|2@1+ (1,0) [0|0] ""  Vector__XXX

BO_ 2239851009 ADAS_PRK_21_20ms_1: 8 CGW_CCU
 SG_ ADAS_PRK_Crc3Val : 0|16@1+ (1,0) [0|0] ""  Vector__XXX
 SG_ ADAS_PRK_AlvCnt3Val : 16|8@1+ (1,0) [0|0] ""  Vector__XXX
 SG_ RSPA_AvnDis : 24|2@1+ (1,0) [0|0] ""  Vector__XXX
 SG_ RSPA_AvnModDis : 26|2@1+ (1,0) [0|0] ""  Vector__XXX
 SG_ RSPA_AvnModNumDis : 28|3@1+ (1,0) [0|0] ""  Vector__XXX
 SG_ RSPA_AvnSubViewDis : 32|2@1+ (1,0) [0|0] ""  Vector__XXX
 SG_ RSPA_AvnModPLDis : 38|2@1+ (1,0) [0|0] ""  Vector__XXX
 SG_ RSPA_AvnModPDRLDis : 40|2@1+ (1,0) [0|0] ""  Vector__XXX
 SG_ RSPA_AvnModPDRRDis : 42|2@1+ (1,0) [0|0] ""  Vector__XXX
 SG_ RSPA_AvnModPRDis : 44|2@1+ (1,0) [0|0] ""  Vector__XXX
 SG_ RSPA_CamDis : 50|3@1+ (1,0) [0|0] ""  Vector__XXX
 SG_ RSPA_AvnHmiDis : 56|8@1+ (1,0) [0|0] ""  Vector__XXX

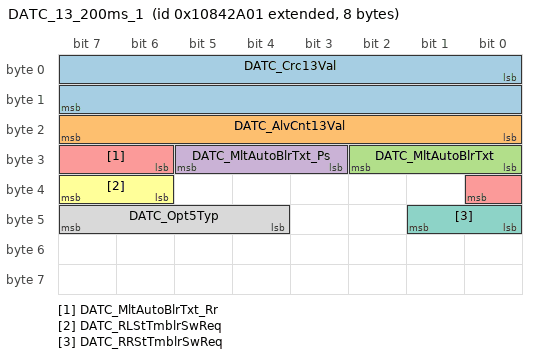
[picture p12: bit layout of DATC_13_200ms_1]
BO_ 2424580609 DATC_13_200ms_1: 8 CGW_CCU
 SG_ DATC_Crc13Val : 0|16@1+ (1,0) [0|0] ""  Vector__XXX
 SG_ DATC_AlvCnt13Val : 16|8@1+ (1,0) [0|0] ""  Vector__XXX
 SG_ DATC_MltAutoBlrTxt : 24|3@1+ (1,0) [0|0] ""  ATS
 SG_ DATC_MltAutoBlrTxt_Ps : 27|3@1+ (1,0) [0|0] ""  ATS
 SG_ DATC_MltAutoBlrTxt_Rr : 30|3@1+ (1,0) [0|0] ""  ATS
 SG_ DATC_RLStTmblrSwReq : 38|2@1+ (1,0) [0|0] ""  RLPSM,RRPSM,RLHV,RRHV
 SG_ DATC_RRStTmblrSwReq : 40|2@1+ (1,0) [0|0] ""  RLPSM,RRPSM,RLHV,RRHV
 SG_ DATC_Opt5Typ : 44|4@1+ (1,0) [0|0] ""  ATS

BO_TX_BU_ 1487 : vHS_M,RLPSM;
BO_TX_BU_ 1486 : RLPSM,vHS_M;
BO_TX_BU_ 1484 : ASAU,vHS_M;
BO_TX_BU_ 1483 : vHS_M,DSAU;
BO_TX_BU_ 1807 : vHS_M,RRHV,SHVU_RR;
CM_ BO_ 2281835009 "[P] Periodic";
CM_ SG_ 2281835009 ACU_Crc1Val "ACU_CyclicRedundancyCheck1Value";
CM_ SG_ 2281835009 ACU_AlvCnt1Val "ACU_AliveCounter1Value";
CM_ SG_ 2281835009 ACU_SysWrngLmpDis "ACU_SystemWarningLampDisplay ##2G##ACU - ACU14 - CF_SWL_Ind";
CM_ SG_ 2281835009 ACU_TlltlLmpDis "PAB ON OFF Lamp indication bit. 00X : PAB OFF LAMP, 0YO : PAB ON LAMP";
CM_ SG_ 2281835009 ACU_OdsIDReq "ACU_OdsIDRequest ##2G##ACU - ACU11 - CF_Ods_IDRcv";
CM_ SG_ 2281835009 SeatBelt_PassBcklFltSta "SeatBelt_PassengerBuckleFaultStatus ##2G##ACU - ACU11 - CF_PasBkl_FltStat";
CM_ SG_ 2281835009 SeatBelt_DrvrBcklFltSta "SeatBelt_DriverBuckleFaultStatus ##2G##ACU - ACU11 - CF_DriBkl_FltStat";
CM_ SG_ 2281835009 SeatBelt_PassBcklSta "SeatBelt_PassengerBuckleStatus ##2G##ACU - ACU11 - CF_PasBkl_Stat";
CM_ SG_ 2281835009 SeatBelt_DrvrBcklSta "SeatBelt_DriverBuckleStatus ##2G##ACU - ACU11 - CF_DriBkl_Stat";
CM_ SG_ 2281835009 ACU_DiagTrblCodVal "ACU_DiagnosticTroubleCodeValue ##2G##ACU - ACU11 - CF_Acu_Dtc";
CM_ SG_ 2281835009 ACU_FltNumVal "ACU_FaultNumberValue ##2G##ACU - ACU11 - CF_Acu_NumOfFlt";
CM_ BO_ 2281835010 "[P] Periodic";
CM_ SG_ 2281835010 ACU_ActvFltSta "ACU_ActiveFaultStatus ##2G##ACU - ACU11 - CF_Acu_FltStat";
CM_ SG_ 2281835010 ACU_NumOfEvtTrigVal "EDR trigger counter";
CM_ SG_ 2281835010 ACU_SdArbgExtTyp "ACU_SideAirbagExistanceType ##2G##ACU - ACU11 - CF_Acu_ExtOfSab";
CM_ SG_ 2281835010 ACU_EvtTrigSta "EDR triggered information bit";
CM_ SG_ 2281835010 ACU_NumOfEmerModVal "Emergency mode counter";
CM_ BO_ 2239851009 "[P] Periodic";
CM_ SG_ 2239851009 ADAS_PRK_Crc3Val "ADAS_PRK_CyclicRedundancyCheck3Value";
CM_ SG_ 2239851009 ADAS_PRK_AlvCnt3Val "ADAS_PRK_AliveCounter3Value";
CM_ SG_ 2239851009 RSPA_AvnDis "RSPA_AvnDisplay";
CM_ SG_ 2239851009 RSPA_AvnModDis "RSPA_AvnModeDisplay";
CM_ SG_ 2239851009 RSPA_AvnModNumDis "RSPA_AvnModeNumberDisplay";
CM_ SG_ 2239851009 RSPA_AvnSubViewDis "RSPA_AvnSubViewDisplay";
CM_ SG_ 2239851009 RSPA_AvnModPLDis "RSPA_AvnModeParallelLeftDisplay";
CM_ SG_ 2239851009 RSPA_AvnModPDRLDis "RSPA_AvnModPerpenDicularRearLeftDisplay";
CM_ SG_ 2239851009 RSPA_AvnModPDRRDis "RSPA_AvnModePerpenDicularRearRightDisplay";
CM_ SG_ 2239851009 RSPA_AvnModPRDis "RSPA_AvnModeParallelRightDisplay";
CM_ SG_ 2239851009 RSPA_CamDis "RSPA_CameraDisplay";
CM_ SG_ 2239851009 RSPA_AvnHmiDis "RSPA_AvnHmiDisplay";
CM_ BO_ 2239851010 "[P] Periodic";
CM_ SG_ 2239851010 RSPA_BxHght "RSPA_BoxHeight";
CM_ SG_ 2239851010 RSPA_RtTrgtPosX "RSPA_RightTargetPosX";
CM_ SG_ 2239851010 RSPA_RtTrgtPosY "RSPA_RightTargetPosY";
CM_ SG_ 2239851010 RSPA_LtTrgtPosX "RSPA_LeftTargetPosX";
CM_ SG_ 2239851010 RSPA_LtTrgtPosY "RSPA_LeftTargetPosY";
CM_ SG_ 2239851010 RSPA_Var "RSPA_Variation";
CM_ SG_ 2239851010 RSPA_Sta "RSPA_Status";
CM_ SG_ 2239851010 RSPA_Actv "RSPA_Actvation";
CM_ SG_ 2239851010 RSPA_EvasiveStrBtnDis "RSPA_EvasiveSteeringButtonDisplay";
CM_ SG_ 2239851010 RSPA_BxWidth "RSPA_BoxWidth";
CM_ BO_ 2239851011 "[P] Periodic";
CM_ SG_ 2239851011 RSPA_TrgtGearSta "RSPA_TargetGearStatus";
CM_ SG_ 2239851011 RSPA_IdOutWarnReq "RSPA_IdOutWarningRequest";
CM_ SG_ 2239851011 RSPA_IndBlnkReq "RSPA_IndicatorBlinkingRequest";
CM_ SG_ 2239851011 RSPA_SysOff "RSPA System status flag";
CM_ SG_ 2239851011 RSPA_DccCmd "RSPA_DccelerationCommand";
CM_ SG_ 2239851011 RSPA_StopReq "RSPA_StopRequest";
CM_ SG_ 2239851011 RSPA_SelDevInfo "Selected Remote Device Information";
CM_ SG_ 2239851011 RSPA_SelFuncInfo "Selected RSPA Function Information";
CM_ SG_ 2239851011 RSPA_TrgtVehSpdVal "RSPA_TargetVehicleSpeedValue";
CM_ SG_ 2239851011 RSPA_EpbReq "RSPA_EPBRequest";
CM_ SG_ 2239851011 RSPA_AddtnlAccelActv "RSPA_AdditionalAccelarationActivation";
CM_ SG_ 2239851011 RSPA_Opt "RSPA_Option";
CM_ SG_ 2239851011 RSPA_RmtPrlExitDis "RSPA_RemoteParallelExitDisplay";
CM_ SG_ 2239851011 RSPA_TrgtTqVal "RSPA_TargetTorqueValue";
CM_ SG_ 2239851011 RSPA_ExtLampReq "RSPA_ExternalLampRequest";
CM_ SG_ 2239851011 RSPA_UppLtTypDis "RSPA_UpperLeftTypeDisplay";
CM_ SG_ 2239851011 RSPA_LwrLtTypDis "RSPA_LowerLeftTypeDisplay";
CM_ SG_ 2239851011 RSPA_UppRtTypDis "RSPA_UpperRightTypeDisplay";
CM_ SG_ 2239851011 RSPA_LwrRtTypDis "RSPA_LowerRightTypeDisplay";
CM_ SG_ 2239851011 RSPA_CrankingReq "RSPA_CrankingRequest";
CM_ BO_ 2239851012 "[P] Periodic";
CM_ SG_ 2239851012 RSPA_DCTTrgtTqVal "RSPA_DCTTargetTorqueValue";
CM_ SG_ 2239851012 RSPA_RtTrgtDir "RSPA_RightTargetDirection";
CM_ SG_ 2239851012 RSPA_LtTrgtDir "RSPA_LeftTargetDirection";
CM_ SG_ 2239851012 RSPA_HdLmpReq "RSPA Head Lamp Request";
CM_ SG_ 2239851012 RSPA_OSMirFoldReq "RSPA_OSMirrorFoldRequest";
CM_ BO_ 1484 "[TP] Transport Protocol";
CM_ SG_ 1484 ASAU_GST_Byte0 "Diag Response from ASAU";
CM_ SG_ 1484 ASAU_GST_Byte2 "Diag Response from ASAU";
CM_ SG_ 1484 ASAU_GST_Byte3 "Diag Response from ASAU";
CM_ SG_ 1484 ASAU_GST_Byte4 "Diag Response from ASAU";
CM_ SG_ 1484 ASAU_GST_Byte5 "Diag Response from ASAU";
CM_ SG_ 1484 ASAU_GST_Byte6 "Diag Response from ASAU";
CM_ SG_ 1484 ASAU_GST_Byte7 "Diag Response from ASAU";
CM_ SG_ 1484 ASAU_GST_Byte1 "Diag Response from ASAU";
CM_ BO_ 2382594305 "[PE] Periodic and On Event";
CM_ SG_ 2382594305 DATC_Crc4Val "DATC_CyclicRedundancyCheck4Value";
CM_ SG_ 2382594305 DATC_AlvCnt4Val "DATC_AliveCounter4Value";
CM_ SG_ 2382594305 DATC_RrDrvTempCDis "DATC_RearDriverTemperatureCelciusDisplay";
CM_ SG_ 2382594305 DATC_RrDrvTempFDis "DATC_RearDriverTemperatureFahrenheitDisplay";
CM_ BO_ 2424580609 "[PE] Periodic and On Event";
CM_ SG_ 2424580609 DATC_Crc13Val "DATC_CyclicRedundancyCheck13Value";
CM_ SG_ 2424580609 DATC_AlvCnt13Val "DATC_AliveCounter13Value";
CM_ SG_ 2424580609 DATC_MltAutoBlrTxt "This signal is to display text of Multi Auto Blower step";
CM_ SG_ 2424580609 DATC_MltAutoBlrTxt_Ps "This signal is to display text of Multi Auto Blower step";
CM_ SG_ 2424580609 DATC_MltAutoBlrTxt_Rr "This signal is to display text of Multi Auto Blower step";
CM_ SG_ 2424580609 DATC_RLStTmblrSwReq "DATC_RearLeftSeatTumblerSwitchRequest";
CM_ SG_ 2424580609 DATC_RRStTmblrSwReq "DATC_RearRightSeatTumblerSwitchRequest";
CM_ SG_ 2424580609 DATC_Opt5Typ "HTR CONTROL OPTION";
CM_ BO_ 1483 "[TP] Transport Protocol";
CM_ SG_ 1483 DSAU_GST_Byte0 "Diag Response from DSAU";
CM_ SG_ 1483 DSAU_GST_Byte2 "Diag Response from DSAU";
CM_ SG_ 1483 DSAU_GST_Byte3 "Diag Response from DSAU";
CM_ SG_ 1483 DSAU_GST_Byte4 "Diag Response from DSAU";
CM_ SG_ 1483 DSAU_GST_Byte5 "Diag Response from DSAU";
CM_ SG_ 1483 DSAU_GST_Byte6 "Diag Response from DSAU";
CM_ SG_ 1483 DSAU_GST_Byte7 "Diag Response from DSAU";
CM_ SG_ 1483 DSAU_GST_Byte1 "Diag Response from DSAU";
CM_ BO_ 367 "[EC] On Event and On Change";
CM_ BO_ 383 "[EC] On Event and On Change";
CM_ BO_ 399 "[EC] On Event and On Change";
CM_ BO_ 415 "[PE] Periodic and On Event";
CM_ BO_ 1476 "[TP] Transport Protocol";
CM_ SG_ 1476 GST_ASAU_Byte0 "Diag Request for ASAU";
CM_ SG_ 1476 GST_ASAU_Byte2 "Diag Request for ASAU";
CM_ SG_ 1476 GST_ASAU_Byte3 "Diag Request for ASAU";
CM_ SG_ 1476 GST_ASAU_Byte4 "Diag Request for ASAU";
CM_ SG_ 1476 GST_ASAU_Byte5 "Diag Request for ASAU";
CM_ SG_ 1476 GST_ASAU_Byte6 "Diag Request for ASAU";
CM_ SG_ 1476 GST_ASAU_Byte7 "Diag Request for ASAU";
CM_ SG_ 1476 GST_ASAU_Byte1 "Diag Request for ASAU";
CM_ BO_ 1475 "[TP] Transport Protocol";
CM_ SG_ 1475 GST_DSAU_Byte0 "Diag Request for DSAU";
CM_ SG_ 1475 GST_DSAU_Byte2 "Diag Request for DSAU";
CM_ SG_ 1475 GST_DSAU_Byte3 "Diag Request for DSAU";
CM_ SG_ 1475 GST_DSAU_Byte4 "Diag Request for DSAU";
CM_ SG_ 1475 GST_DSAU_Byte5 "Diag Request for DSAU";
CM_ SG_ 1475 GST_DSAU_Byte6 "Diag Request for DSAU";
CM_ SG_ 1475 GST_DSAU_Byte7 "Diag Request for DSAU";
CM_ SG_ 1475 GST_DSAU_Byte1 "Diag Request for DSAU";
CM_ BO_ 1810 "[TP] Transport Protocol";
CM_ BO_ 1478 "[TP] Transport Protocol";
CM_ SG_ 1478 GST_RLPSS_Byte0 "Diag Request for RLPSS";
CM_ SG_ 1478 GST_RLPSS_Byte2 "Diag Request for RLPSS";
CM_ SG_ 1478 GST_RLPSS_Byte3 "Diag Request for RLPSS";
CM_ SG_ 1478 GST_RLPSS_Byte4 "Diag Request for RLPSS";
CM_ SG_ 1478 GST_RLPSS_Byte5 "Diag Request for RLPSS";
CM_ SG_ 1478 GST_RLPSS_Byte6 "Diag Request for RLPSS";
CM_ SG_ 1478 GST_RLPSS_Byte7 "Diag Request for RLPSS";
CM_ SG_ 1478 GST_RLPSS_Byte1 "Diag Request for RLPSS";
CM_ BO_ 1799 "[TP] Transport Protocol";
CM_ BO_ 1479 "[TP] Transport Protocol";
CM_ SG_ 1479 GST_RRPSS_Byte0 "Diag Request for RRPSS";
CM_ SG_ 1479 GST_RRPSS_Byte2 "Diag Request for RRPSS";
CM_ SG_ 1479 GST_RRPSS_Byte3 "Diag Request for RRPSS";
CM_ SG_ 1479 GST_RRPSS_Byte4 "Diag Request for RRPSS";
CM_ SG_ 1479 GST_RRPSS_Byte5 "Diag Request for RRPSS";
CM_ SG_ 1479 GST_RRPSS_Byte6 "Diag Request for RRPSS";
CM_ SG_ 1479 GST_RRPSS_Byte7 "Diag Request for RRPSS";
CM_ SG_ 1479 GST_RRPSS_Byte1 "Diag Request for RRPSS";
CM_ BO_ 2319620609 "[PE] Periodic and On Event";
CM_ SG_ 2319620609 HUD_PbackSta "HUD_PbackStatus";
CM_ BO_ 2563126273 "[EC] On Event and On Change";
CM_ SG_ 2563126273 AMP_NaviVolumeStep "Command for Navigation Prompt Volume Setting
-range : 0 ~ max
-max : value of AMP_MaxNaviVolumeState(0x082)
-This Signal's Feedback is AMP_NaviVolumeState(0x082)@AMP";
CM_ SG_ 2563126273 AMP_ESEVMasterGain "Commend ESEV(Engine Sound by Engine Vibration) Master Gain for Engineering mode.";
CM_ SG_ 2563126273 AMP_NaviVoice_Priority "Information for Current Navi Voice priority Status";
CM_ SG_ 2563126273 AMP_ESEVMode "ASD Set Mode Value";
CM_ BO_ 2563127809 "[EC] On Event and On Change";
CM_ SG_ 2563127809 AMP_PESSAPSSet "Command for Personal Engine Sound System (Engine Sound Equalizer) Accelator Pedal Sensitivity Setting";
CM_ SG_ 2563127809 AMP_PESSDesignSet_New "Command for Personal Engine Sound System (Engine Sound Equalizer) Preset Select_New Definition";
CM_ SG_ 2563127809 AMP_PESSCANSet "Command for Personal Engine Sound System (Engine Sound Equalizer) Gain control linked by CAN Signal";
CM_ SG_ 2563127809 AMP_WalkieTalkieMode "Send Signal 'Walkie Talkie On/Off' from HU to AMP";
CM_ SG_ 2563127809 AMP_WalkieTalkieVolumeStep "Command for WalkieTalkie Mode Volume Setting";
CM_ SG_ 2563127809 AMP_PESSMode "Command for Personal Engine Sound System (Engine Sound Equalizer) ON/OFF";
CM_ SG_ 2563127809 AMP_PESSVolumeSet "Command for Personal Engine Sound System (Engine Sound Equalizer) Volume Set
(NVH Sound research lab tuning value)";
CM_ BO_ 2298626305 "[PE] Periodic and On Event";
CM_ SG_ 2298626305 C_AstBolsterInfSw_HU "Assistant seat moving switch: Bolster Inflate";
CM_ SG_ 2298626305 C_RLHrestUpSw_HU "2nd Left side seat Moving control : Headrest Up";
CM_ SG_ 2298626305 C_RLHrestDnSw_HU "2nd Left side seat Moving control : Headrest Down";
CM_ SG_ 2298626305 C_RLHrestFwdSw_HU "2nd Left side seat Moving control : Headrest Forward";
CM_ SG_ 2298626305 C_AstBolsterDefSw_HU "Assistant seat moving switch: Bolster Deflate";
CM_ SG_ 2298626305 C_RLHrestBwdSw_HU "2nd Left side seat Moving control : Headrest Backward";
CM_ SG_ 2298626305 C_RLLumbarUpSw_HU "2nd Left side seat Moving control : Lumbar Up";
CM_ SG_ 2298626305 C_RLLumbarMidSw_HU "2nd Left side seat Moving control : Lumbar Mid";
CM_ SG_ 2298626305 C_RLLumbarLowSw_HU "2nd Left side seat Moving control : Lumbar Low";
CM_ SG_ 2298626305 C_RLLumbarDefSw_HU "2nd Left side seat Moving control : Lumbar Deflate";
CM_ SG_ 2298626305 C_RLBolsterInfSw_HU "2nd Left side seat Moving control : Bolster Inflate";
CM_ SG_ 2298626305 C_RLBolsterDefSw_HU "2nd Left side seat Moving control : Bolster Deflate";
CM_ SG_ 2298626305 C_AstHrestUpSw_HU "Assistant seat moving switch : Headrest Up";
CM_ SG_ 2298626305 C_AstHrestDnSw_HU "Assistant seat Moving control : Headrest Down";
CM_ SG_ 2298626305 C_AstFootrestFldSw_HU "Assistant seat moving switch: Footrest Fold";
CM_ SG_ 2298626305 C_AstHrestFwdSw_HU "Assistant seat Moving control : Headrest Forward";
CM_ SG_ 2298626305 C_AstHrestBwdSw_HU "Assistant seat moving switch : Headrest Backward";
CM_ SG_ 2298626305 C_AstFootrestUnFldSw_HU "Assistant seat moving switch: Footrest Unfold";
CM_ BO_ 2458165505 "[EC] On Event and On Change";
CM_ SG_ 2458165505 C_AstWindowCmdAVN "This signal indicates AST Window Open/Close Command";
CM_ SG_ 2458165505 C_TrunkTlgtCmdAVN "This signal indicates Trunk Open Button Command";
CM_ SG_ 2458165505 C_StrgWhlHeatedCmdAVN "This signal indicates Steering Wheel Heated Voice Recognition Control Command";
CM_ SG_ 2458165505 C_RrDefoggerCmdAVN "This signal indicates Rear Defogger Button Command";
CM_ SG_ 2458165505 C_RRWindowCmdAVN "This signal indicates RR Window Open/Close Command";
CM_ SG_ 2458165505 C_RLWindowCmdAVN "This signal indicates RL Window Open/Close Command";
CM_ SG_ 2458165505 C_BlindCmdAVN "This signal indicates Sunroof Blind Open/Close Command";
CM_ SG_ 2458165505 C_GlassCmdAVN "This signal indicates Sunroof Glass Open/Close Command";
CM_ SG_ 2458165505 C_DrvWindowCmdAVN "This signal indicates DRV Window Open/Close Command";
CM_ SG_ 2458165505 C_ThemeCmdAVN "Theme SYNC for HU and CLU (For integrated screen)";
CM_ SG_ 2458165505 C_CluDispCmdAVN "This signal indicates cluster display changing Command";
CM_ SG_ 2458165505 HU_FRSeatHeatVRcmd "This signal indicated seat heat&vent VR control command (For passenger seat)";
CM_ SG_ 2458165505 HU_FLSeatHeatVRcmd "This signal indicated seat heat&vent VR control command (For driver seat)";
CM_ SG_ 2458165505 C_PTGCNTLCmdAVN "This signal indicates PowerTailgate Open/Close  Command";
CM_ BO_ 2479158017 "[PE] Periodic and On Event";
CM_ SG_ 2479158017 RSELockOnOff "Command for RSE Lock Requst from Head Unit";
CM_ SG_ 2479158017 HU_DATC_DisplayThemes "HU Display Theme (Black/White)";
CM_ SG_ 2479158017 HU_DATC_RearLockSet "This signal is rear DATC(MTC) lock siganl when no RRC option";
CM_ SG_ 2479158017 HU_PhoneActivity "Information for Acitivity of Phone Call (For All area)";
CM_ SG_ 2479158017 HU_VRActivity "Information for Acitivity of VR (For All area)";
CM_ BO_ 2315420417 "[EC] On Event and On Change";
CM_ BO_ 2336415489 "[EC] On Event and On Change";
CM_ BO_ 939 "[P] Periodic";
CM_ SG_ 939 PSB_Crc1Val "PSB_CyclicRedundancyCheck1Value";
CM_ SG_ 939 PSB_AlvCnt1Val "PSB_AliveCounter1Value";
CM_ SG_ 939 PSB_LHFlrSta "PSB_LeftHandedFailureStatus";
CM_ SG_ 939 PSB_LHActvSta "PSB_LeftHandedActiveStatus";
CM_ SG_ 939 PSB_RHFlrSta "PSB_RightHandedFailureStatus";
CM_ SG_ 939 PSB_RHActvSta "PSB_RightHandedActiveStatus";
CM_ SG_ 939 PSB_ActForAcu "PSB_ActiveForAcu";
CM_ SG_ 939 PSB_HapticWarnSta "PSB_Haptic_Warning_Status";
CM_ SG_ 939 PSB_RHActForPss "PSB_RightHandedActiveStatus_forPss";
CM_ SG_ 939 PSB_LHActForPss "PSB_LeftHandedActiveStatus_forPss";
CM_ BO_ 1486 "[TP] Transport Protocol";
CM_ SG_ 1486 RLPSS_GST_Byte0 "Diag Response from RLPSS";
CM_ SG_ 1486 RLPSS_GST_Byte2 "Diag Response from RLPSS";
CM_ SG_ 1486 RLPSS_GST_Byte3 "Diag Response from RLPSS";
CM_ SG_ 1486 RLPSS_GST_Byte4 "Diag Response from RLPSS";
CM_ SG_ 1486 RLPSS_GST_Byte5 "Diag Response from RLPSS";
CM_ SG_ 1486 RLPSS_GST_Byte6 "Diag Response from RLPSS";
CM_ SG_ 1486 RLPSS_GST_Byte7 "Diag Response from RLPSS";
CM_ SG_ 1486 RLPSS_GST_Byte1 "Diag Response from RLPSS";
CM_ BO_ 1807 "[TP] Transport Protocol";
CM_ BO_ 1487 "[TP] Transport Protocol";
CM_ SG_ 1487 RRPSS_GST_Byte0 "Diag Response from RRPSS";
CM_ SG_ 1487 RRPSS_GST_Byte2 "Diag Response from RRPSS";
CM_ SG_ 1487 RRPSS_GST_Byte3 "Diag Response from RRPSS";
CM_ SG_ 1487 RRPSS_GST_Byte4 "Diag Response from RRPSS";
CM_ SG_ 1487 RRPSS_GST_Byte5 "Diag Response from RRPSS";
CM_ SG_ 1487 RRPSS_GST_Byte6 "Diag Response from RRPSS";
CM_ SG_ 1487 RRPSS_GST_Byte7 "Diag Response from RRPSS";
CM_ SG_ 1487 RRPSS_GST_Byte1 "Diag Response from RRPSS";
CM_ BO_ 858 "[PE] Periodic and On Event";
CM_ SG_ 858 SBCM_AST_Crc2Val "SBCM_AST_CyclicRedundancyCheck2Value";
CM_ SG_ 858 AST_CrashUnlockCmd "AssistCrashUnlockCommand";
CM_ SG_ 858 SBCM_AST_AlvCnt2Val "SBCM_AST_AliveCounter2Value";
CM_ SG_ 858 DoorLock_CtrlDrLkSwSta_SBCM "DoorLock_CentralDoorLockAssistSwitchStatus";
CM_ SG_ 858 DoorLock_CtrlDrUnLkSwSta_SBCM "DoorLock_CentralDoorUnLockAssistSwitchStatus";
CM_ SG_ 858 Warn_AsstDrSwSta_SBCM "Warn_AssistDoorSwitchStatus ##2G## -  - C_AstDrSw,CF_Gway_AstDrSw,Warn_AsstDrSwSta";
CM_ SG_ 858 DoorLock_AsstDrUnLkSta_SBCM "DoorLock_AssistDoorUnLockStatus ##2G## -  - C_AstUnlockState,DoorLock_AsstDrUnLkSta";
CM_ SG_ 858 AST_SEAWarn_RH "Assist SEA Warning (LHD)";
CM_ BO_ 862 "[PE] Periodic and On Event";
CM_ SG_ 862 SBCM_RL_Crc1Val "SBCM_RL_CyclicRedundancyCheck1Value";
CM_ SG_ 862 RL_CrashUnlockCmd "Rear Lefr Crash Unlock Command";
CM_ SG_ 862 SBCM_RL_AlvCnt1Val "SBCM_RL_AliveCounter1Value";
CM_ SG_ 862 Warn_RrLftDrSwSta_SBCM "Warn_RearLeftDoorSwitchStatus ##2G## -  - C_RLDrSw,CF_Gway_RLDrSw,Warn_RrLftDrSwSta";
CM_ SG_ 862 DoorLock_RrLftDrUnLkSta_SBCM "DoorLock_RearLeftDoorUnLockStatus ##2G## -  - C_RLUnlockState,DoorLock_RrLftDrUnLkSta";
CM_ SG_ 862 RL_SEAActivated "RearLeftSEAActivated";
CM_ SG_ 862 RL_SEAWarn "Rear Left SEA Warning";
BA_DEF_ BO_ "DiagState" ENUM "No","Yes" ;
BA_DEF_ BO_ "DiagResponse" ENUM "No","Yes" ;
BA_DEF_ BO_ "DiagRequest" ENUM "No","Yes" ;
BA_DEF_ BO_ "TpMessage" ENUM "No","Yes" ;
BA_DEF_ BO_ "UsrMsgIDSforwardDeviation" INT 0 100 ;
BA_DEF_ BO_ "UsrMsgIDSbackwardDeviation" INT 50 1000 ;
BA_DEF_ BO_ "GenMsgCycleTime" INT 0 2000 ;
BA_DEF_ BO_ "GenMsgStartDelayTime" INT 0 2000 ;
BA_DEF_ BO_ "GenMsgSendType" ENUM "Cyclic","NoMsgSendType" ;
BA_DEF_ BO_ "GenMsgCycleTimeFast" INT 0 500 ;
BA_DEF_ BO_ "GenMsgDelayTime" INT 0 20 ;
BA_DEF_ BO_ "GenMsgILSupport" ENUM "No","Yes" ;
BA_DEF_ BO_ "GenMsgNrOfRepetition" INT 0 3 ;
BA_DEF_ BO_ "NmMessage" ENUM "No","Yes" ;
BA_DEF_ BO_ "NWM-Botschaft" ENUM "No","Yes" ;
BA_DEF_ BO_ "TpTxIndex" INT 0 255 ;
BA_DEF_ BO_ "VFrameFormat" ENUM "StandardCAN","ExtendedCAN","reserved","reserved","reserved","reserved","reserved","reserved","reserved","reserved","reserved","reserved","reserved","reserved","StandardCAN_FD","ExtendedCAN_FD" ;
BA_DEF_ SG_ "UserSigValidity" ENUM "B+","ACC","IG","IG1","IG2","IG3","IG1 or IG2","IG1 or IG3","Undef" ;
BA_DEF_ SG_ "TimeoutValue" STRING ;
BA_DEF_ SG_ "UsrSigPurpose" ENUM "Undef","FN","DIAG","DIAG(Req)","DIAG(Res)","DIAG(Phy)","DEV","CCP(Req)","CCP(Res)","NM","TP" ;
BA_DEF_ SG_ "GenSigStartValue" INT 0 1215752192 ;
BA_DEF_ SG_ "NetworkRequest" ENUM "Yes","No" ;
BA_DEF_ SG_ "NetworkRequestHoldingTime" INT 0 65535 ;
BA_DEF_ SG_ "Description" STRING ;
BA_DEF_ SG_ "Version" STRING ;
BA_DEF_ SG_ "GenSigEnvVarType" ENUM "Int","Float","Undef" ;
BA_DEF_ SG_ "GenSigSendType" ENUM "Cyclic","OnWrite","OnWriteWithRepetition","OnChange","OnChangeWithRepetition","IfActive","IfActiveWithRepetition","NoSigSendType","OnChangeAndIfActive","OnChangeAndIfActiveWithRepetition" ;
BA_DEF_ SG_ "GwSigLatencyTime" INT 0 65536 ;
BA_DEF_ SG_ "GwSigMissingSourceType" ENUM "Undef","OldValue","DefaultValue","InitialValue" ;
BA_DEF_ SG_ "NWM-WakeupAllowed" ENUM "<n.a.>" ;
BA_DEF_ SG_ "RoutingFactor" INT 1 1215752192 ;
BA_DEF_REL_ BU_SG_REL_ "GenSigTimeoutTime" INT 0 7000 ;
BA_DEF_DEF_ "DiagState" "No" ;
BA_DEF_DEF_ "DiagResponse" "No" ;
BA_DEF_DEF_ "DiagRequest" "No" ;
BA_DEF_DEF_ "TpMessage" "No" ;
BA_DEF_DEF_ "UsrMsgIDSforwardDeviation" 10 ;
BA_DEF_DEF_ "UsrMsgIDSbackwardDeviation" 100 ;
BA_DEF_DEF_ "GenMsgCycleTime" 200 ;
BA_DEF_DEF_ "GenMsgStartDelayTime" 0 ;
BA_DEF_DEF_ "GenMsgSendType" "NoMsgSendType" ;
BA_DEF_DEF_ "GenMsgCycleTimeFast" 40 ;
BA_DEF_DEF_ "GenMsgDelayTime" 20 ;
BA_DEF_DEF_ "GenMsgILSupport" "Yes" ;
BA_DEF_DEF_ "GenMsgNrOfRepetition" 3 ;
BA_DEF_DEF_ "NmMessage" "No" ;
BA_DEF_DEF_ "NWM-Botschaft" "No" ;
BA_DEF_DEF_ "TpTxIndex" 0 ;
BA_DEF_DEF_ "VFrameFormat" "StandardCAN" ;
BA_DEF_DEF_ "UserSigValidity" "IG" ;
BA_DEF_DEF_ "TimeoutValue" "" ;
BA_DEF_DEF_ "UsrSigPurpose" "FN" ;
BA_DEF_DEF_ "GenSigStartValue" 0 ;
BA_DEF_DEF_ "NetworkRequest" "No" ;
BA_DEF_DEF_ "NetworkRequestHoldingTime" 0 ;
BA_DEF_DEF_ "Description" "" ;
BA_DEF_DEF_ "Version" "" ;
BA_DEF_DEF_ "GenSigEnvVarType" "Undef" ;
BA_DEF_DEF_ "GenSigSendType" "NoSigSendType" ;
BA_DEF_DEF_ "GwSigLatencyTime" 40 ;
BA_DEF_DEF_ "GwSigMissingSourceType" "Undef" ;
BA_DEF_DEF_ "NWM-WakeupAllowed" "<n.a.>" ;
BA_DEF_DEF_ "RoutingFactor" 1 ;
BA_DEF_DEF_REL_ "GenSigTimeoutTime" 500 ;
BA_ "GenMsgSendType" BO_ 2281835009 0;
BA_ "GenMsgCycleTime" BO_ 2281835009 100;
BA_ "GenMsgCycleTimeFast" BO_ 2281835009 0;
BA_ "GenMsgNrOfRepetition" BO_ 2281835009 0;
BA_ "VFrameFormat" BO_ 2281835009 1;
BA_ "Description" SG_ 2281835009 ACU_Crc1Val "The data area for CRC calculation is based on the data length (DLC) of the message DB.

The CRC shall be calculated over the entire data block (excluding the CRC bytes) including the user data, alive counter and Data ID

 

- CRC Polynomial (0x1021) , Initial Value : 0xFFFF, XOR value : 0x0000, Data ID : Message ID + 0xF800 

- The initial value is for CRC calculation and the message should be sent with the calculated result value. 

- The mathematical expression to 16 bit CRC polynomial is given here. G(x) = x16 + x12 + x5 + 1";
BA_ "GenSigStartValue" SG_ 2281835009 ACU_Crc1Val 65535;
BA_ "UserSigValidity" SG_ 2281835009 ACU_Crc1Val 3;
BA_ "Version" SG_ 2281835009 ACU_Crc1Val "18.11.08";
BA_ "Description" SG_ 2281835009 ACU_AlvCnt1Val "For the first transmission request for a data element the counter shall be initialized with 0 and shall be incremented by 1 for every subsequent send request. 

When the counter reaches the maximum value(0xFF), then it shall restart with 0 for the next send request";
BA_ "UserSigValidity" SG_ 2281835009 ACU_AlvCnt1Val 3;
BA_ "Version" SG_ 2281835009 ACU_AlvCnt1Val "18.11.08";
BA_ "Description" SG_ 2281835009 ACU_SysWrngLmpDis "This signal means information regarding ACU diagnostic information result & discrimination.



1) Default value : 0x1

2) Default value Transmit condition

    - When the input condition is not determined.

    - When the input condition is not supported.";
BA_ "GenSigStartValue" SG_ 2281835009 ACU_SysWrngLmpDis 1;
BA_ "UserSigValidity" SG_ 2281835009 ACU_SysWrngLmpDis 3;
BA_ "Version" SG_ 2281835009 ACU_SysWrngLmpDis "18.11.05";
BA_ "Description" SG_ 2281835009 ACU_TlltlLmpDis "This signal means information regarding Occupant status.

0) 00Xb : X position means PAB OFF Lamp indication. When this bit set as 1 PAB OFF lamp turns ON. 

    0Y0b : Y position means PAB ON Lamp indication. When this bit set as 1 PAB ON lamp turns ON.



1) Default value : 0x2 (PAB ON Lamp on, PAB OFF Lamp off,)

2) Default value Transmit condition

    - When the input condition is not determined.

    - When the input condition is not supported.";
BA_ "GenSigStartValue" SG_ 2281835009 ACU_TlltlLmpDis 3;
BA_ "UserSigValidity" SG_ 2281835009 ACU_TlltlLmpDis 3;
BA_ "Version" SG_ 2281835009 ACU_TlltlLmpDis "20.03.02";
BA_ "Description" SG_ 2281835009 ACU_OdsIDReq "It s a Request to send ODS Identifier. If the Bit is equal to `0` the ODS-B module will transmit the ODS identifier message. ACU sets “ODS ID Received” to ‘1’ after getting the valid ODS ID two times.



1) Default value : 0x0

2) Default value Transmit condition

    - When the input condition is not determined.

    - When the input condition is not supported.";
BA_ "UserSigValidity" SG_ 2281835009 ACU_OdsIDReq 3;
BA_ "Version" SG_ 2281835009 ACU_OdsIDReq "17.12.00";
BA_ "Description" SG_ 2281835009 SeatBelt_PassBcklFltSta "Information of Passenger Seat Belt Buckle switch Fault condition.



1) Default value : 0x0

2) Default value Transmit condition

    - When the input condition is not supported.

※This signal is valid (updated) only that buckle is connected to ACU directly, 

otherwise transmitted as default value.";
BA_ "UserSigValidity" SG_ 2281835009 SeatBelt_PassBcklFltSta 3;
BA_ "Version" SG_ 2281835009 SeatBelt_PassBcklFltSta "19.01.08";
BA_ "Description" SG_ 2281835009 SeatBelt_DrvrBcklFltSta "Information of Driver Seat Belt Buckle switch Fault condition.



1) Default value : 0x0

2) Default value Transmit condition

    - When the input condition is not supported.

※This signal is valid (updated) only that buckle is connected to ACU directly, 

otherwise transmitted as default value.";
BA_ "UserSigValidity" SG_ 2281835009 SeatBelt_DrvrBcklFltSta 3;
BA_ "Version" SG_ 2281835009 SeatBelt_DrvrBcklFltSta "19.01.08";
BA_ "Description" SG_ 2281835009 SeatBelt_PassBcklSta "Information of Passenger Seat Belt Buckle switch Status, whether its Latched or Not .



1) Default value : 0x1

2) Default value Transmit condition

    - When the input condition is not determined.

    - When the input condition is not supported.

※This signal is valid (updated) only that buckle is connected to ACU directly, 

otherwise transmitted as default value.";
BA_ "GenSigStartValue" SG_ 2281835009 SeatBelt_PassBcklSta 1;
BA_ "UserSigValidity" SG_ 2281835009 SeatBelt_PassBcklSta 3;
BA_REL_ "GenSigTimeoutTime" BU_SG_REL_ APSM SG_ 2281835009 SeatBelt_PassBcklSta 1500;
BA_REL_ "GenSigTimeoutTime" BU_SG_REL_ ATS SG_ 2281835009 SeatBelt_PassBcklSta 1500;
BA_ "Version" SG_ 2281835009 SeatBelt_PassBcklSta "19.01.08";
BA_ "Description" SG_ 2281835009 SeatBelt_DrvrBcklSta "Information of Driver Seat Belt Buckle switch Status, whether its Latched or Not.



1) Default value : 0x1

2) Default value Transmit condition

    - When the input condition is not determined.

    - When the input condition is not supported.

※This signal is valid (updated) only that buckle is connected to ACU directly, 

otherwise transmitted as default value.";
BA_ "GenSigStartValue" SG_ 2281835009 SeatBelt_DrvrBcklSta 1;
BA_ "UserSigValidity" SG_ 2281835009 SeatBelt_DrvrBcklSta 3;
BA_REL_ "GenSigTimeoutTime" BU_SG_REL_ PSM SG_ 2281835009 SeatBelt_DrvrBcklSta 1500;
BA_ "Version" SG_ 2281835009 SeatBelt_DrvrBcklSta "19.01.08";
BA_ "Description" SG_ 2281835009 ACU_DiagTrblCodVal "This signal means information regarding a diagnostic trouble code number.



1) Default value : 0x0

2) Default value Transmit condition

    - When Fault does not exist.";
BA_ "UserSigValidity" SG_ 2281835009 ACU_DiagTrblCodVal 3;
BA_ "Version" SG_ 2281835009 ACU_DiagTrblCodVal "17.12.00";
BA_ "Description" SG_ 2281835009 ACU_FltNumVal "This signal means information regarding number of fault in ACU memory, including active and historic faults.



1) Default value : 0x0

2) Default value Transmit condition

    - When Fault does not exist.";
BA_ "UserSigValidity" SG_ 2281835009 ACU_FltNumVal 3;
BA_ "Version" SG_ 2281835009 ACU_FltNumVal "17.12.00";
BA_ "GenMsgSendType" BO_ 2281835010 0;
BA_ "GenMsgCycleTime" BO_ 2281835010 100;
BA_ "GenMsgCycleTimeFast" BO_ 2281835010 0;
BA_ "GenMsgNrOfRepetition" BO_ 2281835010 0;
BA_ "VFrameFormat" BO_ 2281835010 1;
BA_ "Description" SG_ 2281835010 ACU_ActvFltSta "This signal means information regarding fault status, whether it is an active fault or not.



1) Default value : 0x2

2) Default value Transmit condition

    - When the input condition is not supported.";
BA_ "GenSigStartValue" SG_ 2281835010 ACU_ActvFltSta 2;
BA_ "UserSigValidity" SG_ 2281835010 ACU_ActvFltSta 3;
BA_ "Version" SG_ 2281835010 ACU_ActvFltSta "17.12.00";
BA_ "Description" SG_ 2281835010 ACU_NumOfEvtTrigVal "This signal is incremented by one each time when ACU meet EDR trigger condition

The last value is kept in the next cycle.



1) Value in EOL : always 0x0";
BA_ "UserSigValidity" SG_ 2281835010 ACU_NumOfEvtTrigVal 3;
BA_ "Version" SG_ 2281835010 ACU_NumOfEvtTrigVal "18.04.00";
BA_ "Description" SG_ 2281835010 ACU_SdArbgExtTyp "This signal does not specify the types or variations of the side restraints such as the front side airbag only or both the front and the rear side airbag. If any side restraint is equipped, the signal responds as 'exists'.

※Initial value shall be actual value.";
BA_ "UserSigValidity" SG_ 2281835010 ACU_SdArbgExtTyp 3;
BA_ "Version" SG_ 2281835010 ACU_SdArbgExtTyp "19.07.06";
BA_ "Description" SG_ 2281835010 ACU_EmerModSta "This signal is set when  ACU detect Emergency mode status 

 (e.g : During driving, IGN1+ is disconnected)  

1)Value in EOL :  always 0x0 

2)Emergency mode details in ES95910-02";
BA_ "UserSigValidity" SG_ 2281835010 ACU_EmerModSta 3;
BA_ "Version" SG_ 2281835010 ACU_EmerModSta "18.04.00";
BA_ "Description" SG_ 2281835010 ACU_EvtTrigSta "This signal is set when  ACU meet EDR trigger condition.

Event trigger condition is same as EDR Regulation definition(49 CFR PART 563)

This signal is set to '1'  then kept for the current IGN cycle as '1'



1)Value in EOL :  always 0x0";
BA_ "UserSigValidity" SG_ 2281835010 ACU_EvtTrigSta 3;
BA_ "Version" SG_ 2281835010 ACU_EvtTrigSta "18.04.00";
BA_ "Description" SG_ 2281835010 ACU_NumOfEmerModVal "This signal is incremented by one each time when ACU enters into emergency mode.

The last value is kept in the next cycle.



1) Value in EOL : always 0x0

2)Emergency mode details in ES95910-02";
BA_ "UserSigValidity" SG_ 2281835010 ACU_NumOfEmerModVal 3;
BA_ "Version" SG_ 2281835010 ACU_NumOfEmerModVal "18.04.00";
BA_ "GenMsgSendType" BO_ 2239851009 0;
BA_ "GenMsgCycleTime" BO_ 2239851009 100;
BA_ "GenMsgCycleTimeFast" BO_ 2239851009 0;
BA_ "GenMsgNrOfRepetition" BO_ 2239851009 0;
BA_ "VFrameFormat" BO_ 2239851009 1;
BA_ "Description" SG_ 2239851009 ADAS_PRK_Crc3Val "The data area for CRC calculation is based on the data length (DLC) of the message DB.

The CRC shall be calculated over the entire data block (excluding the CRC bytes) including the user data, alive counter and Data ID

 

- CRC Polynomial (0x1021) , Initial Value : 0xFFFF, XOR value : 0x0000, Data ID : Message ID + 0xF800 

- The initial value is for CRC calculation and the message should be sent with the calculated result value. 

- The mathematical expression to 16 bit CRC polynomial is given here. G(x) = x16 + x12 + x5 + 1";
BA_ "GenSigStartValue" SG_ 2239851009 ADAS_PRK_Crc3Val 65535;
BA_ "UserSigValidity" SG_ 2239851009 ADAS_PRK_Crc3Val 3;
BA_ "RoutingFactor" SG_ 2239851009 ADAS_PRK_Crc3Val 5;
BA_ "Version" SG_ 2239851009 ADAS_PRK_Crc3Val "18.11.08";
BA_ "Description" SG_ 2239851009 ADAS_PRK_AlvCnt3Val "For the first transmission request for a data element the counter shall be initialized with 0 and shall be incremented by 1 for every subsequent send request. 

When the counter reaches the maximum value(0xFF), then it shall restart with 0 for the next send request";
BA_ "UserSigValidity" SG_ 2239851009 ADAS_PRK_AlvCnt3Val 3;
BA_ "RoutingFactor" SG_ 2239851009 ADAS_PRK_AlvCnt3Val 5;
BA_ "Version" SG_ 2239851009 ADAS_PRK_AlvCnt3Val "18.11.08";
BA_ "Description" SG_ 2239851009 RSPA_AvnDis "AVN 화면 출력 요청 (RSPA 용)

'-CGW routing 필요 (CCAN to MMCAN)";
BA_ "UserSigValidity" SG_ 2239851009 RSPA_AvnDis 3;
BA_ "RoutingFactor" SG_ 2239851009 RSPA_AvnDis 5;
BA_ "Version" SG_ 2239851009 RSPA_AvnDis "17.11.00";
BA_ "Description" SG_ 2239851009 RSPA_AvnModDis "AVN상의 모드선택 메뉴 표출을 위한 주차/출차 구분 정보

'-CGW routing 필요 (CCAN to MMCAN)";
BA_ "UserSigValidity" SG_ 2239851009 RSPA_AvnModDis 3;
BA_ "RoutingFactor" SG_ 2239851009 RSPA_AvnModDis 5;
BA_ "Version" SG_ 2239851009 RSPA_AvnModDis "17.11.00";
BA_ "Description" SG_ 2239851009 RSPA_AvnModNumDis "AVN에서 표출해야할 모드 선택 메뉴의 개수 설정 정보

'-CGW routing 필요 (CCAN to MMCAN)";
BA_ "UserSigValidity" SG_ 2239851009 RSPA_AvnModNumDis 3;
BA_ "RoutingFactor" SG_ 2239851009 RSPA_AvnModNumDis 5;
BA_ "Version" SG_ 2239851009 RSPA_AvnModNumDis "17.11.00";
BA_ "Description" SG_ 2239851009 RSPA_AvnSubViewDis "AVN에서 표출해야할 Topview영역 대체이미지 출력요청

'-CGW routing 필요 (CCAN to MMCAN)";
BA_ "UserSigValidity" SG_ 2239851009 RSPA_AvnSubViewDis 3;
BA_ "RoutingFactor" SG_ 2239851009 RSPA_AvnSubViewDis 5;
BA_ "Version" SG_ 2239851009 RSPA_AvnSubViewDis "17.11.00";
BA_ "Description" SG_ 2239851009 RSPA_AvnModPLDis "AVN에서 표출하는 평행후방좌측 (주차/출차) 모드선택 메뉴의 제어가능여부 표시 정보

'-CGW routing 필요 (CCAN to MMCAN)";
BA_ "UserSigValidity" SG_ 2239851009 RSPA_AvnModPLDis 3;
BA_ "RoutingFactor" SG_ 2239851009 RSPA_AvnModPLDis 5;
BA_ "Version" SG_ 2239851009 RSPA_AvnModPLDis "17.11.00";
BA_ "Description" SG_ 2239851009 RSPA_AvnModPDRLDis "AVN에서 표출하는 직각후방좌측 (주차/출차) 모드선택 메뉴의 제어가능여부 표시 정보

'-CGW routing 필요 (CCAN to MMCAN)";
BA_ "UserSigValidity" SG_ 2239851009 RSPA_AvnModPDRLDis 3;
BA_ "RoutingFactor" SG_ 2239851009 RSPA_AvnModPDRLDis 5;
BA_ "Version" SG_ 2239851009 RSPA_AvnModPDRLDis "17.11.00";
BA_ "Description" SG_ 2239851009 RSPA_AvnModPDRRDis "AVN에서 표출하는 직각후방우측 (주차/출차) 모드선택 메뉴의 제어가능여부 표시 정보

'-CGW routing 필요 (CCAN to MMCAN)";
BA_ "UserSigValidity" SG_ 2239851009 RSPA_AvnModPDRRDis 3;
BA_ "RoutingFactor" SG_ 2239851009 RSPA_AvnModPDRRDis 5;
BA_ "Version" SG_ 2239851009 RSPA_AvnModPDRRDis "17.11.00";
BA_ "Description" SG_ 2239851009 RSPA_AvnModPRDis "AVN에서 표출하는 평행후방우측 (주차/출차) 모드선택 메뉴의 제어가능여부 표시 정보

'-CGW routing 필요 (CCAN to MMCAN)";
BA_ "UserSigValidity" SG_ 2239851009 RSPA_AvnModPRDis 3;
BA_ "RoutingFactor" SG_ 2239851009 RSPA_AvnModPRDis 5;
BA_ "Version" SG_ 2239851009 RSPA_AvnModPRDis "17.11.00";
BA_ "Description" SG_ 2239851009 RSPA_CamDis "RSPA 작동 시 AVM/RVM에 AVN에 출력할 영상 뷰 모드 요청";
BA_ "UserSigValidity" SG_ 2239851009 RSPA_CamDis 3;
BA_ "RoutingFactor" SG_ 2239851009 RSPA_CamDis 5;
BA_ "Version" SG_ 2239851009 RSPA_CamDis "17.11.00";
BA_ "Description" SG_ 2239851009 RSPA_AvnHmiDis "AVN에서 표출하는 RSPA HMI 표시 정보

'-CGW routing 필요 (CCAN to MMCAN)";
BA_ "UserSigValidity" SG_ 2239851009 RSPA_AvnHmiDis 3;
BA_ "RoutingFactor" SG_ 2239851009 RSPA_AvnHmiDis 5;
BA_ "Version" SG_ 2239851009 RSPA_AvnHmiDis "19.11.11";
BA_ "GenMsgSendType" BO_ 2239851010 0;
BA_ "GenMsgCycleTime" BO_ 2239851010 100;
BA_ "GenMsgCycleTimeFast" BO_ 2239851010 0;
BA_ "GenMsgNrOfRepetition" BO_ 2239851010 0;
BA_ "VFrameFormat" BO_ 2239851010 1;
BA_ "Description" SG_ 2239851010 RSPA_BxHght "AVM 표시 목표주차공간 높이";
BA_ "UserSigValidity" SG_ 2239851010 RSPA_BxHght 3;
BA_ "RoutingFactor" SG_ 2239851010 RSPA_BxHght 5;
BA_ "Version" SG_ 2239851010 RSPA_BxHght "17.11.00";
BA_ "Description" SG_ 2239851010 RSPA_RtTrgtPosX "AVM 표시 오른쪽 주차공간 위치 X 좌표";
BA_ "UserSigValidity" SG_ 2239851010 RSPA_RtTrgtPosX 3;
BA_ "RoutingFactor" SG_ 2239851010 RSPA_RtTrgtPosX 5;
BA_ "Version" SG_ 2239851010 RSPA_RtTrgtPosX "20.08.02";
BA_ "Description" SG_ 2239851010 RSPA_RtTrgtPosY "AVM 표시 오른쪽 주차공간 위치 Y 좌표";
BA_ "UserSigValidity" SG_ 2239851010 RSPA_RtTrgtPosY 3;
BA_ "RoutingFactor" SG_ 2239851010 RSPA_RtTrgtPosY 5;
BA_ "Version" SG_ 2239851010 RSPA_RtTrgtPosY "20.08.02";
BA_ "Description" SG_ 2239851010 RSPA_LtTrgtPosX "AVM 표시 왼쪽 주차공간 위치 X 좌표";
BA_ "UserSigValidity" SG_ 2239851010 RSPA_LtTrgtPosX 3;
BA_ "RoutingFactor" SG_ 2239851010 RSPA_LtTrgtPosX 5;
BA_ "Version" SG_ 2239851010 RSPA_LtTrgtPosX "20.08.02";
BA_ "Description" SG_ 2239851010 RSPA_LtTrgtPosY "AVM 표시 왼쪽 주차공간 위치 Y 좌표";
BA_ "UserSigValidity" SG_ 2239851010 RSPA_LtTrgtPosY 3;
BA_ "RoutingFactor" SG_ 2239851010 RSPA_LtTrgtPosY 5;
BA_ "Version" SG_ 2239851010 RSPA_LtTrgtPosY "20.08.02";
BA_ "Description" SG_ 2239851010 RSPA_Var "RSPA variation";
BA_ "UserSigValidity" SG_ 2239851010 RSPA_Var 3;
BA_ "RoutingFactor" SG_ 2239851010 RSPA_Var 5;
BA_ "Version" SG_ 2239851010 RSPA_Var "21.01.08";
BA_ "Description" SG_ 2239851010 RSPA_Sta "현재 RSPA의 상태";
BA_ "GenSigStartValue" SG_ 2239851010 RSPA_Sta 1;
BA_ "UserSigValidity" SG_ 2239851010 RSPA_Sta 3;
BA_ "RoutingFactor" SG_ 2239851010 RSPA_Sta 5;
BA_ "Version" SG_ 2239851010 RSPA_Sta "19.03.11";
BA_ "Description" SG_ 2239851010 RSPA_Actv "RSPA's activation information";
BA_ "UserSigValidity" SG_ 2239851010 RSPA_Actv 3;
BA_ "RoutingFactor" SG_ 2239851010 RSPA_Actv 5;
BA_ "Version" SG_ 2239851010 RSPA_Actv "17.11.00";
BA_ "Description" SG_ 2239851010 RSPA_EvasiveStrBtnDis "Display evasive steering on/off button (RSPA II)";
BA_ "UserSigValidity" SG_ 2239851010 RSPA_EvasiveStrBtnDis 3;
BA_ "RoutingFactor" SG_ 2239851010 RSPA_EvasiveStrBtnDis 5;
BA_ "Version" SG_ 2239851010 RSPA_EvasiveStrBtnDis "19.08.08";
BA_ "Description" SG_ 2239851010 RSPA_BxWidth "AVM 표시 목표주차공간 너비";
BA_ "UserSigValidity" SG_ 2239851010 RSPA_BxWidth 3;
BA_ "RoutingFactor" SG_ 2239851010 RSPA_BxWidth 5;
BA_ "Version" SG_ 2239851010 RSPA_BxWidth "17.11.00";
BA_ "GenMsgSendType" BO_ 2239851011 0;
BA_ "GenMsgCycleTime" BO_ 2239851011 100;
BA_ "GenMsgCycleTimeFast" BO_ 2239851011 0;
BA_ "GenMsgNrOfRepetition" BO_ 2239851011 0;
BA_ "VFrameFormat" BO_ 2239851011 1;
BA_ "Description" SG_ 2239851011 RSPA_TrgtGearSta "목표 변속단 

(목표 변속단 100ms 유지후 Idle 값 송출, 목표값 rising 이후 500ms 대기)";
BA_ "UserSigValidity" SG_ 2239851011 RSPA_TrgtGearSta 3;
BA_ "RoutingFactor" SG_ 2239851011 RSPA_TrgtGearSta 5;
BA_ "Version" SG_ 2239851011 RSPA_TrgtGearSta "17.11.00";
BA_ "Description" SG_ 2239851011 RSPA_IdOutWarnReq "ID out 패턴 변경 요청 (RSPA 용)";
BA_ "UserSigValidity" SG_ 2239851011 RSPA_IdOutWarnReq 3;
BA_REL_ "GenSigTimeoutTime" BU_SG_REL_ PSM SG_ 2239851011 RSPA_IdOutWarnReq 1500;
BA_ "RoutingFactor" SG_ 2239851011 RSPA_IdOutWarnReq 5;
BA_ "Version" SG_ 2239851011 RSPA_IdOutWarnReq "17.11.00";
BA_ "Description" SG_ 2239851011 RSPA_IndBlnkReq "FOB blinking request during RSPA mode";
BA_ "UserSigValidity" SG_ 2239851011 RSPA_IndBlnkReq 3;
BA_ "RoutingFactor" SG_ 2239851011 RSPA_IndBlnkReq 5;
BA_ "Version" SG_ 2239851011 RSPA_IndBlnkReq "17.11.00";
BA_ "Description" SG_ 2239851011 RSPA_SysOff "System off status for Smartphone display before RSPA control";
BA_ "UserSigValidity" SG_ 2239851011 RSPA_SysOff 3;
BA_ "RoutingFactor" SG_ 2239851011 RSPA_SysOff 5;
BA_ "Version" SG_ 2239851011 RSPA_SysOff "18.12.07";
BA_ "Description" SG_ 2239851011 RSPA_DccCmd "목표 감속도, 차량 정차 시에만(when RSPA_VS=0) 감속도 제어목적";
BA_ "UserSigValidity" SG_ 2239851011 RSPA_DccCmd 3;
BA_ "RoutingFactor" SG_ 2239851011 RSPA_DccCmd 5;
BA_ "Version" SG_ 2239851011 RSPA_DccCmd "17.11.00";
BA_ "Description" SG_ 2239851011 RSPA_StopReq "A control request flag for vehicle stop. RSPA expects vehicle to be controlled to a complete stop and hold its state.";
BA_ "UserSigValidity" SG_ 2239851011 RSPA_StopReq 3;
BA_ "RoutingFactor" SG_ 2239851011 RSPA_StopReq 5;
BA_ "Version" SG_ 2239851011 RSPA_StopReq "17.11.00";
BA_ "Description" SG_ 2239851011 RSPA_SelDevInfo "Device information for Remote Control in operation of RSPA";
BA_ "UserSigValidity" SG_ 2239851011 RSPA_SelDevInfo 3;
BA_ "RoutingFactor" SG_ 2239851011 RSPA_SelDevInfo 5;
BA_ "Version" SG_ 2239851011 RSPA_SelDevInfo "18.12.07";
BA_ "Description" SG_ 2239851011 RSPA_SelFuncInfo "Function information in operation of RSPA for SmartPhone control";
BA_ "UserSigValidity" SG_ 2239851011 RSPA_SelFuncInfo 3;
BA_ "RoutingFactor" SG_ 2239851011 RSPA_SelFuncInfo 5;
BA_ "Version" SG_ 2239851011 RSPA_SelFuncInfo "18.12.07";
BA_ "Description" SG_ 2239851011 RSPA_TrgtVehSpdVal "차속 요청값, 차속 프로파일 전송 (0 … 10.23)";
BA_ "UserSigValidity" SG_ 2239851011 RSPA_TrgtVehSpdVal 3;
BA_ "RoutingFactor" SG_ 2239851011 RSPA_TrgtVehSpdVal 5;
BA_ "Version" SG_ 2239851011 RSPA_TrgtVehSpdVal "18.07.01";
BA_ "Description" SG_ 2239851011 RSPA_EpbReq "EPB 체결/해제 요청 (AHB 우회)";
BA_ "UserSigValidity" SG_ 2239851011 RSPA_EpbReq 3;
BA_ "RoutingFactor" SG_ 2239851011 RSPA_EpbReq 5;
BA_ "Version" SG_ 2239851011 RSPA_EpbReq "19.03.11";
BA_ "Description" SG_ 2239851011 RSPA_AddtnlAccelActv "RSPA additional acceleration control ON";
BA_ "UserSigValidity" SG_ 2239851011 RSPA_AddtnlAccelActv 3;
BA_ "RoutingFactor" SG_ 2239851011 RSPA_AddtnlAccelActv 5;
BA_ "Version" SG_ 2239851011 RSPA_AddtnlAccelActv "17.11.00";
BA_ "Description" SG_ 2239851011 RSPA_Opt "RSPA Option applied information";
BA_ "UserSigValidity" SG_ 2239851011 RSPA_Opt 3;
BA_ "RoutingFactor" SG_ 2239851011 RSPA_Opt 5;
BA_ "Version" SG_ 2239851011 RSPA_Opt "17.12.03";
BA_ "Description" SG_ 2239851011 RSPA_RmtPrlExitDis "Display remote parallel exit (RSPA II)";
BA_ "UserSigValidity" SG_ 2239851011 RSPA_RmtPrlExitDis 3;
BA_ "RoutingFactor" SG_ 2239851011 RSPA_RmtPrlExitDis 5;
BA_ "Version" SG_ 2239851011 RSPA_RmtPrlExitDis "19.08.08";
BA_ "Description" SG_ 2239851011 RSPA_TrgtTqVal "RSPA request EMS/HCU/VCU/FCU torque value (Nm)

Init value : 00h

If MSB is 1, this signal is - value.

else, this signal is +value.

0~10bit is used for absolute value.";
BA_ "UserSigValidity" SG_ 2239851011 RSPA_TrgtTqVal 3;
BA_ "RoutingFactor" SG_ 2239851011 RSPA_TrgtTqVal 5;
BA_ "Version" SG_ 2239851011 RSPA_TrgtTqVal "19.06.00";
BA_ "Description" SG_ 2239851011 RSPA_ExtLampReq "전조등, 방향지시등 동작 요청 (RSPA 용)

Type1:비상등 1회 Normal Blinking

Type2:비상등 2회 Normal Blinking

Type3:비상등 3회 Normal Blinking

Type4:비상등 지속적으로 Normal Blinking";
BA_ "UserSigValidity" SG_ 2239851011 RSPA_ExtLampReq 3;
BA_ "RoutingFactor" SG_ 2239851011 RSPA_ExtLampReq 5;
BA_ "Version" SG_ 2239851011 RSPA_ExtLampReq "17.11.00";
BA_ "Description" SG_ 2239851011 RSPA_UppLtTypDis "Parking type displayed on upper-left of AVN (RSPA II)";
BA_ "UserSigValidity" SG_ 2239851011 RSPA_UppLtTypDis 3;
BA_ "RoutingFactor" SG_ 2239851011 RSPA_UppLtTypDis 5;
BA_ "Version" SG_ 2239851011 RSPA_UppLtTypDis "20.03.04";
BA_ "Description" SG_ 2239851011 RSPA_LwrLtTypDis "Parking type displayed on lower-left of AVN (RSPA II)";
BA_ "UserSigValidity" SG_ 2239851011 RSPA_LwrLtTypDis 3;
BA_ "RoutingFactor" SG_ 2239851011 RSPA_LwrLtTypDis 5;
BA_ "Version" SG_ 2239851011 RSPA_LwrLtTypDis "20.03.04";
BA_ "Description" SG_ 2239851011 RSPA_UppRtTypDis "Parking type displayed on upper-right of AVN (RSPA II)";
BA_ "UserSigValidity" SG_ 2239851011 RSPA_UppRtTypDis 3;
BA_ "RoutingFactor" SG_ 2239851011 RSPA_UppRtTypDis 5;
BA_ "Version" SG_ 2239851011 RSPA_UppRtTypDis "19.08.08";
BA_ "Description" SG_ 2239851011 RSPA_LwrRtTypDis "Parking type displayed on lower-right of AVN (RSPA II)";
BA_ "UserSigValidity" SG_ 2239851011 RSPA_LwrRtTypDis 3;
BA_ "RoutingFactor" SG_ 2239851011 RSPA_LwrRtTypDis 5;
BA_ "Version" SG_ 2239851011 RSPA_LwrRtTypDis "19.08.08";
BA_ "Description" SG_ 2239851011 RSPA_CrankingReq "시동모드 천이 요청 (RSPA 용)";
BA_ "UserSigValidity" SG_ 2239851011 RSPA_CrankingReq 3;
BA_ "RoutingFactor" SG_ 2239851011 RSPA_CrankingReq 5;
BA_ "Version" SG_ 2239851011 RSPA_CrankingReq "17.11.00";
BA_ "GenMsgSendType" BO_ 2239851012 0;
BA_ "GenMsgCycleTime" BO_ 2239851012 100;
BA_ "GenMsgCycleTimeFast" BO_ 2239851012 0;
BA_ "GenMsgNrOfRepetition" BO_ 2239851012 0;
BA_ "VFrameFormat" BO_ 2239851012 1;
BA_ "Description" SG_ 2239851012 RSPA_DCTTrgtTqVal "RSPA request DCT torque value (Nm)

Init value : 00h

If MSB is 1, this signal is - value.

else, this signal is +value.

0~10bit is used for absolute value.";
BA_ "UserSigValidity" SG_ 2239851012 RSPA_DCTTrgtTqVal 3;
BA_ "RoutingFactor" SG_ 2239851012 RSPA_DCTTrgtTqVal 5;
BA_ "Version" SG_ 2239851012 RSPA_DCTTrgtTqVal "19.06.00";
BA_ "Description" SG_ 2239851012 RSPA_RtTrgtDir "SVM 표시 오른쪽 주차 공간 방향";
BA_ "UserSigValidity" SG_ 2239851012 RSPA_RtTrgtDir 3;
BA_ "RoutingFactor" SG_ 2239851012 RSPA_RtTrgtDir 5;
BA_ "Version" SG_ 2239851012 RSPA_RtTrgtDir "20.08.02";
BA_ "Description" SG_ 2239851012 RSPA_LtTrgtDir "SVM 표시 왼쪽 주차 공간 방향";
BA_ "UserSigValidity" SG_ 2239851012 RSPA_LtTrgtDir 3;
BA_ "RoutingFactor" SG_ 2239851012 RSPA_LtTrgtDir 5;
BA_ "Version" SG_ 2239851012 RSPA_LtTrgtDir "20.08.02";
BA_ "Description" SG_ 2239851012 RSPA_HdLmpReq "Head lamp request of RSPA";
BA_ "UserSigValidity" SG_ 2239851012 RSPA_HdLmpReq 3;
BA_ "RoutingFactor" SG_ 2239851012 RSPA_HdLmpReq 5;
BA_ "Version" SG_ 2239851012 RSPA_HdLmpReq "20.10.00";
BA_ "Description" SG_ 2239851012 RSPA_OSMirFoldReq "OS Mirror folding/unfolding request of RSPA";
BA_ "UserSigValidity" SG_ 2239851012 RSPA_OSMirFoldReq 3;
BA_ "RoutingFactor" SG_ 2239851012 RSPA_OSMirFoldReq 5;
BA_ "Version" SG_ 2239851012 RSPA_OSMirFoldReq "19.08.08";
BA_ "GenMsgCycleTime" BO_ 1484 0;
BA_ "GenMsgCycleTimeFast" BO_ 1484 0;
BA_ "GenMsgNrOfRepetition" BO_ 1484 0;
BA_ "DiagResponse" BO_ 1484 1;
BA_ "GenMsgILSupport" BO_ 1484 0;
BA_ "TpMessage" BO_ 1484 1;
BA_ "TpTxIndex" BO_ 1484 216;
BA_ "Description" SG_ 1484 ASAU_GST_Byte0 "TP Index : 216";
BA_ "UsrSigPurpose" SG_ 1484 ASAU_GST_Byte0 4;
BA_ "UserSigValidity" SG_ 1484 ASAU_GST_Byte0 0;
BA_REL_ "GenSigTimeoutTime" BU_SG_REL_ CGW_CCU SG_ 1484 ASAU_GST_Byte0 0;
BA_ "NetworkRequest" SG_ 1484 ASAU_GST_Byte0 0;
BA_ "NetworkRequestHoldingTime" SG_ 1484 ASAU_GST_Byte0 5000;
BA_ "Version" SG_ 1484 ASAU_GST_Byte0 "21.02.04";
BA_ "Description" SG_ 1484 ASAU_GST_Byte2 "TP Index : 216";
BA_ "UsrSigPurpose" SG_ 1484 ASAU_GST_Byte2 4;
BA_ "UserSigValidity" SG_ 1484 ASAU_GST_Byte2 0;
BA_REL_ "GenSigTimeoutTime" BU_SG_REL_ CGW_CCU SG_ 1484 ASAU_GST_Byte2 0;
BA_ "NetworkRequest" SG_ 1484 ASAU_GST_Byte2 0;
BA_ "NetworkRequestHoldingTime" SG_ 1484 ASAU_GST_Byte2 5000;
BA_ "Version" SG_ 1484 ASAU_GST_Byte2 "21.02.04";
BA_ "Description" SG_ 1484 ASAU_GST_Byte3 "TP Index : 216";
BA_ "UsrSigPurpose" SG_ 1484 ASAU_GST_Byte3 4;
BA_ "UserSigValidity" SG_ 1484 ASAU_GST_Byte3 0;
BA_REL_ "GenSigTimeoutTime" BU_SG_REL_ CGW_CCU SG_ 1484 ASAU_GST_Byte3 0;
BA_ "NetworkRequest" SG_ 1484 ASAU_GST_Byte3 0;
BA_ "NetworkRequestHoldingTime" SG_ 1484 ASAU_GST_Byte3 5000;
BA_ "Version" SG_ 1484 ASAU_GST_Byte3 "21.02.04";
BA_ "Description" SG_ 1484 ASAU_GST_Byte4 "TP Index : 216";
BA_ "UsrSigPurpose" SG_ 1484 ASAU_GST_Byte4 4;
BA_ "UserSigValidity" SG_ 1484 ASAU_GST_Byte4 0;
BA_REL_ "GenSigTimeoutTime" BU_SG_REL_ CGW_CCU SG_ 1484 ASAU_GST_Byte4 0;
BA_ "NetworkRequest" SG_ 1484 ASAU_GST_Byte4 0;
BA_ "NetworkRequestHoldingTime" SG_ 1484 ASAU_GST_Byte4 5000;
BA_ "Version" SG_ 1484 ASAU_GST_Byte4 "21.02.04";
BA_ "Description" SG_ 1484 ASAU_GST_Byte5 "TP Index : 216";
BA_ "UsrSigPurpose" SG_ 1484 ASAU_GST_Byte5 4;
BA_ "UserSigValidity" SG_ 1484 ASAU_GST_Byte5 0;
BA_REL_ "GenSigTimeoutTime" BU_SG_REL_ CGW_CCU SG_ 1484 ASAU_GST_Byte5 0;
BA_ "NetworkRequest" SG_ 1484 ASAU_GST_Byte5 0;
BA_ "NetworkRequestHoldingTime" SG_ 1484 ASAU_GST_Byte5 5000;
BA_ "Version" SG_ 1484 ASAU_GST_Byte5 "21.02.04";
BA_ "Description" SG_ 1484 ASAU_GST_Byte6 "TP Index : 216";
BA_ "UsrSigPurpose" SG_ 1484 ASAU_GST_Byte6 4;
BA_ "UserSigValidity" SG_ 1484 ASAU_GST_Byte6 0;
BA_REL_ "GenSigTimeoutTime" BU_SG_REL_ CGW_CCU SG_ 1484 ASAU_GST_Byte6 0;
BA_ "NetworkRequest" SG_ 1484 ASAU_GST_Byte6 0;
BA_ "NetworkRequestHoldingTime" SG_ 1484 ASAU_GST_Byte6 5000;
BA_ "Version" SG_ 1484 ASAU_GST_Byte6 "21.02.04";
BA_ "Description" SG_ 1484 ASAU_GST_Byte7 "TP Index : 216";
BA_ "UsrSigPurpose" SG_ 1484 ASAU_GST_Byte7 4;
BA_ "UserSigValidity" SG_ 1484 ASAU_GST_Byte7 0;
BA_REL_ "GenSigTimeoutTime" BU_SG_REL_ CGW_CCU SG_ 1484 ASAU_GST_Byte7 0;
BA_ "NetworkRequest" SG_ 1484 ASAU_GST_Byte7 0;
BA_ "NetworkRequestHoldingTime" SG_ 1484 ASAU_GST_Byte7 5000;
BA_ "Version" SG_ 1484 ASAU_GST_Byte7 "21.02.04";
BA_ "Description" SG_ 1484 ASAU_GST_Byte1 "TP Index : 216";
BA_ "UsrSigPurpose" SG_ 1484 ASAU_GST_Byte1 4;
BA_ "UserSigValidity" SG_ 1484 ASAU_GST_Byte1 0;
BA_REL_ "GenSigTimeoutTime" BU_SG_REL_ CGW_CCU SG_ 1484 ASAU_GST_Byte1 0;
BA_ "NetworkRequest" SG_ 1484 ASAU_GST_Byte1 0;
BA_ "NetworkRequestHoldingTime" SG_ 1484 ASAU_GST_Byte1 5000;
BA_ "Version" SG_ 1484 ASAU_GST_Byte1 "21.02.04";
BA_ "GenMsgSendType" BO_ 2382594305 0;
BA_ "VFrameFormat" BO_ 2382594305 1;
BA_ "Description" SG_ 2382594305 DATC_Crc4Val "The data area for CRC calculation is based on the data length (DLC) of the message DB.

The CRC shall be calculated over the entire data block (excluding the CRC bytes) including the user data, alive counter and Data ID

 

- CRC Polynomial (0x1021) , Initial Value : 0xFFFF, XOR value : 0x0000, Data ID : Message ID + 0xF800 

- The initial value is for CRC calculation and the message should be sent with the calculated result value. 

- The mathematical expression to 16 bit CRC polynomial is given here. G(x) = x16 + x12 + x5 + 1";
BA_ "GenSigSendType" SG_ 2382594305 DATC_Crc4Val 4;
BA_ "GenSigStartValue" SG_ 2382594305 DATC_Crc4Val 65535;
BA_ "UserSigValidity" SG_ 2382594305 DATC_Crc4Val 3;
BA_ "Version" SG_ 2382594305 DATC_Crc4Val "18.11.08";
BA_ "Description" SG_ 2382594305 DATC_AlvCnt4Val "For the first transmission request for a data element the counter shall be initialized with 0 and shall be incremented by 1 for every subsequent send request. 

When the counter reaches the maximum value(0xFF), then it shall restart with 0 for the next send request";
BA_ "GenSigSendType" SG_ 2382594305 DATC_AlvCnt4Val 4;
BA_ "UserSigValidity" SG_ 2382594305 DATC_AlvCnt4Val 3;
BA_ "Version" SG_ 2382594305 DATC_AlvCnt4Val "18.11.08";
BA_ "Description" SG_ 2382594305 DATC_RrDrvTempCDis "if Rear passenger Push Rear TEMP(▲/ ▼) button 

Its temperature is increased/decreased by 0.5℃ from high(32℃) to low(17℃).";
BA_ "GenSigSendType" SG_ 2382594305 DATC_RrDrvTempCDis 4;
BA_ "UserSigValidity" SG_ 2382594305 DATC_RrDrvTempCDis 6;
BA_REL_ "GenSigTimeoutTime" BU_SG_REL_ ATS SG_ 2382594305 DATC_RrDrvTempCDis 1500;
BA_ "Version" SG_ 2382594305 DATC_RrDrvTempCDis "19.05.03";
BA_ "Description" SG_ 2382594305 DATC_RrDrvTempFDis "if Rear passenger Push Rear TEMP(▲/ ▼) button 

Its temperature is increased/decreased by 1℉ from high(90℉) to low(62℉).";
BA_ "GenSigSendType" SG_ 2382594305 DATC_RrDrvTempFDis 4;
BA_ "UserSigValidity" SG_ 2382594305 DATC_RrDrvTempFDis 6;
BA_REL_ "GenSigTimeoutTime" BU_SG_REL_ ATS SG_ 2382594305 DATC_RrDrvTempFDis 1500;
BA_ "Version" SG_ 2382594305 DATC_RrDrvTempFDis "19.05.03";
BA_ "GenMsgSendType" BO_ 2424580609 0;
BA_ "VFrameFormat" BO_ 2424580609 1;
BA_ "Description" SG_ 2424580609 DATC_Crc13Val "The data area for CRC calculation is based on the data length (DLC) of the message DB.

The CRC shall be calculated over the entire data block (excluding the CRC bytes) including the user data, alive counter and Data ID

 

- CRC Polynomial (0x1021) , Initial Value : 0xFFFF, XOR value : 0x0000, Data ID : Message ID + 0xF800 

- The initial value is for CRC calculation and the message should be sent with the calculated result value. 

- The mathematical expression to 16 bit CRC polynomial is given here. G(x) = x16 + x12 + x5 + 1";
BA_ "GenSigSendType" SG_ 2424580609 DATC_Crc13Val 4;
BA_ "GenSigStartValue" SG_ 2424580609 DATC_Crc13Val 65535;
BA_ "UserSigValidity" SG_ 2424580609 DATC_Crc13Val 3;
BA_ "Version" SG_ 2424580609 DATC_Crc13Val "18.11.08";
BA_ "Description" SG_ 2424580609 DATC_AlvCnt13Val "For the first transmission request for a data element the counter shall be initialized with 0 and shall be incremented by 1 for every subsequent send request. 

When the counter reaches the maximum value(0xFF), then it shall restart with 0 for the next send request";
BA_ "GenSigSendType" SG_ 2424580609 DATC_AlvCnt13Val 4;
BA_ "UserSigValidity" SG_ 2424580609 DATC_AlvCnt13Val 3;
BA_ "Version" SG_ 2424580609 DATC_AlvCnt13Val "18.11.08";
BA_ "GenSigSendType" SG_ 2424580609 DATC_MltAutoBlrTxt 4;
BA_ "UserSigValidity" SG_ 2424580609 DATC_MltAutoBlrTxt 7;
BA_REL_ "GenSigTimeoutTime" BU_SG_REL_ ATS SG_ 2424580609 DATC_MltAutoBlrTxt 1500;
BA_ "Version" SG_ 2424580609 DATC_MltAutoBlrTxt "20.02.04";
BA_ "GenSigSendType" SG_ 2424580609 DATC_MltAutoBlrTxt_Ps 4;
BA_ "UserSigValidity" SG_ 2424580609 DATC_MltAutoBlrTxt_Ps 7;
BA_REL_ "GenSigTimeoutTime" BU_SG_REL_ ATS SG_ 2424580609 DATC_MltAutoBlrTxt_Ps 1500;
BA_ "Version" SG_ 2424580609 DATC_MltAutoBlrTxt_Ps "20.02.04";
BA_ "GenSigSendType" SG_ 2424580609 DATC_MltAutoBlrTxt_Rr 4;
BA_ "UserSigValidity" SG_ 2424580609 DATC_MltAutoBlrTxt_Rr 7;
BA_REL_ "GenSigTimeoutTime" BU_SG_REL_ ATS SG_ 2424580609 DATC_MltAutoBlrTxt_Rr 1500;
BA_ "Version" SG_ 2424580609 DATC_MltAutoBlrTxt_Rr "20.02.04";
BA_ "Description" SG_ 2424580609 DATC_RLStTmblrSwReq "Rear Left Seat heater & cooler tumbler S/W";
BA_ "GenSigSendType" SG_ 2424580609 DATC_RLStTmblrSwReq 4;
BA_ "UserSigValidity" SG_ 2424580609 DATC_RLStTmblrSwReq 7;
BA_REL_ "GenSigTimeoutTime" BU_SG_REL_ RLPSM SG_ 2424580609 DATC_RLStTmblrSwReq 1500;
BA_REL_ "GenSigTimeoutTime" BU_SG_REL_ RRPSM SG_ 2424580609 DATC_RLStTmblrSwReq 1500;
BA_REL_ "GenSigTimeoutTime" BU_SG_REL_ RLHV SG_ 2424580609 DATC_RLStTmblrSwReq 1500;
BA_REL_ "GenSigTimeoutTime" BU_SG_REL_ RRHV SG_ 2424580609 DATC_RLStTmblrSwReq 1500;
BA_ "Version" SG_ 2424580609 DATC_RLStTmblrSwReq "20.07.10";
BA_ "Description" SG_ 2424580609 DATC_RRStTmblrSwReq "Rear Right Seat heater & cooler tumbler S/W";
BA_ "GenSigSendType" SG_ 2424580609 DATC_RRStTmblrSwReq 4;
BA_ "UserSigValidity" SG_ 2424580609 DATC_RRStTmblrSwReq 7;
BA_REL_ "GenSigTimeoutTime" BU_SG_REL_ RLPSM SG_ 2424580609 DATC_RRStTmblrSwReq 1500;
BA_REL_ "GenSigTimeoutTime" BU_SG_REL_ RRPSM SG_ 2424580609 DATC_RRStTmblrSwReq 1500;
BA_REL_ "GenSigTimeoutTime" BU_SG_REL_ RLHV SG_ 2424580609 DATC_RRStTmblrSwReq 1500;
BA_REL_ "GenSigTimeoutTime" BU_SG_REL_ RRHV SG_ 2424580609 DATC_RRStTmblrSwReq 1500;
BA_ "Version" SG_ 2424580609 DATC_RRStTmblrSwReq "20.07.10";
BA_ "Description" SG_ 2424580609 DATC_Opt5Typ "This signal indicates Option of HTR Control.

Bit0 : (After Blow) : 0 - After Blow Not Applied / 1 - After Blow Applied

Bit1 : (Fragrance) : 0 ? Fragrance System Not Applied / 1 ? Fragrance System Applied

Bit2 : (Rear Climate Auto Off) : 0 - Rear Climate Auto Off Not Applied / 1 - Rear Climate Auto Off Applied

Bit3 : Reserved";
BA_ "GenSigSendType" SG_ 2424580609 DATC_Opt5Typ 4;
BA_ "UserSigValidity" SG_ 2424580609 DATC_Opt5Typ 7;
BA_REL_ "GenSigTimeoutTime" BU_SG_REL_ ATS SG_ 2424580609 DATC_Opt5Typ 1500;
BA_ "Version" SG_ 2424580609 DATC_Opt5Typ "21.07.05";
BA_ "GenMsgCycleTime" BO_ 1483 0;
BA_ "GenMsgCycleTimeFast" BO_ 1483 0;
BA_ "GenMsgNrOfRepetition" BO_ 1483 0;
BA_ "DiagResponse" BO_ 1483 1;
BA_ "GenMsgILSupport" BO_ 1483 0;
BA_ "TpMessage" BO_ 1483 1;
BA_ "TpTxIndex" BO_ 1483 215;
BA_ "Description" SG_ 1483 DSAU_GST_Byte0 "TP Index : 215";
BA_ "UsrSigPurpose" SG_ 1483 DSAU_GST_Byte0 4;
BA_ "UserSigValidity" SG_ 1483 DSAU_GST_Byte0 0;
BA_REL_ "GenSigTimeoutTime" BU_SG_REL_ CGW_CCU SG_ 1483 DSAU_GST_Byte0 0;
BA_ "NetworkRequest" SG_ 1483 DSAU_GST_Byte0 0;
BA_ "NetworkRequestHoldingTime" SG_ 1483 DSAU_GST_Byte0 5000;
BA_ "Version" SG_ 1483 DSAU_GST_Byte0 "21.02.04";
BA_ "Description" SG_ 1483 DSAU_GST_Byte2 "TP Index : 215";
BA_ "UsrSigPurpose" SG_ 1483 DSAU_GST_Byte2 4;
BA_ "UserSigValidity" SG_ 1483 DSAU_GST_Byte2 0;
BA_REL_ "GenSigTimeoutTime" BU_SG_REL_ CGW_CCU SG_ 1483 DSAU_GST_Byte2 0;
BA_ "NetworkRequest" SG_ 1483 DSAU_GST_Byte2 0;
BA_ "NetworkRequestHoldingTime" SG_ 1483 DSAU_GST_Byte2 5000;
BA_ "Version" SG_ 1483 DSAU_GST_Byte2 "21.02.04";
BA_ "Description" SG_ 1483 DSAU_GST_Byte3 "TP Index : 215";
BA_ "UsrSigPurpose" SG_ 1483 DSAU_GST_Byte3 4;
BA_ "UserSigValidity" SG_ 1483 DSAU_GST_Byte3 0;
BA_REL_ "GenSigTimeoutTime" BU_SG_REL_ CGW_CCU SG_ 1483 DSAU_GST_Byte3 0;
BA_ "NetworkRequest" SG_ 1483 DSAU_GST_Byte3 0;
BA_ "NetworkRequestHoldingTime" SG_ 1483 DSAU_GST_Byte3 5000;
BA_ "Version" SG_ 1483 DSAU_GST_Byte3 "21.02.04";
BA_ "Description" SG_ 1483 DSAU_GST_Byte4 "TP Index : 215";
BA_ "UsrSigPurpose" SG_ 1483 DSAU_GST_Byte4 4;
BA_ "UserSigValidity" SG_ 1483 DSAU_GST_Byte4 0;
BA_REL_ "GenSigTimeoutTime" BU_SG_REL_ CGW_CCU SG_ 1483 DSAU_GST_Byte4 0;
BA_ "NetworkRequest" SG_ 1483 DSAU_GST_Byte4 0;
BA_ "NetworkRequestHoldingTime" SG_ 1483 DSAU_GST_Byte4 5000;
BA_ "Version" SG_ 1483 DSAU_GST_Byte4 "21.02.04";
BA_ "Description" SG_ 1483 DSAU_GST_Byte5 "TP Index : 215";
BA_ "UsrSigPurpose" SG_ 1483 DSAU_GST_Byte5 4;
BA_ "UserSigValidity" SG_ 1483 DSAU_GST_Byte5 0;
BA_REL_ "GenSigTimeoutTime" BU_SG_REL_ CGW_CCU SG_ 1483 DSAU_GST_Byte5 0;
BA_ "NetworkRequest" SG_ 1483 DSAU_GST_Byte5 0;
BA_ "NetworkRequestHoldingTime" SG_ 1483 DSAU_GST_Byte5 5000;
BA_ "Version" SG_ 1483 DSAU_GST_Byte5 "21.02.04";
BA_ "Description" SG_ 1483 DSAU_GST_Byte6 "TP Index : 215";
BA_ "UsrSigPurpose" SG_ 1483 DSAU_GST_Byte6 4;
BA_ "UserSigValidity" SG_ 1483 DSAU_GST_Byte6 0;
BA_REL_ "GenSigTimeoutTime" BU_SG_REL_ CGW_CCU SG_ 1483 DSAU_GST_Byte6 0;
BA_ "NetworkRequest" SG_ 1483 DSAU_GST_Byte6 0;
BA_ "NetworkRequestHoldingTime" SG_ 1483 DSAU_GST_Byte6 5000;
BA_ "Version" SG_ 1483 DSAU_GST_Byte6 "21.02.04";
BA_ "Description" SG_ 1483 DSAU_GST_Byte7 "TP Index : 215";
BA_ "UsrSigPurpose" SG_ 1483 DSAU_GST_Byte7 4;
BA_ "UserSigValidity" SG_ 1483 DSAU_GST_Byte7 0;
BA_REL_ "GenSigTimeoutTime" BU_SG_REL_ CGW_CCU SG_ 1483 DSAU_GST_Byte7 0;
BA_ "NetworkRequest" SG_ 1483 DSAU_GST_Byte7 0;
BA_ "NetworkRequestHoldingTime" SG_ 1483 DSAU_GST_Byte7 5000;
BA_ "Version" SG_ 1483 DSAU_GST_Byte7 "21.02.04";
BA_ "Description" SG_ 1483 DSAU_GST_Byte1 "TP Index : 215";
BA_ "UsrSigPurpose" SG_ 1483 DSAU_GST_Byte1 4;
BA_ "UserSigValidity" SG_ 1483 DSAU_GST_Byte1 0;
BA_REL_ "GenSigTimeoutTime" BU_SG_REL_ CGW_CCU SG_ 1483 DSAU_GST_Byte1 0;
BA_ "NetworkRequest" SG_ 1483 DSAU_GST_Byte1 0;
BA_ "NetworkRequestHoldingTime" SG_ 1483 DSAU_GST_Byte1 5000;
BA_ "Version" SG_ 1483 DSAU_GST_Byte1 "21.02.04";
BA_ "GenMsgCycleTime" BO_ 367 0;
BA_ "GenSigSendType" SG_ 367 FPM2IAU_ISKLearnFdbck 4;
BA_ "UserSigValidity" SG_ 367 FPM2IAU_ISKLearnFdbck 0;
BA_REL_ "GenSigTimeoutTime" BU_SG_REL_ CGW_CCU SG_ 367 FPM2IAU_ISKLearnFdbck 0;
BA_ "Version" SG_ 367 FPM2IAU_ISKLearnFdbck "20.04.06";
BA_ "GenMsgCycleTime" BO_ 383 0;
BA_ "Description" SG_ 383 FPM_Encrypted_Result4 "enrypted result of FPM";
BA_ "GenSigSendType" SG_ 383 FPM_Encrypted_Result4 4;
BA_ "UserSigValidity" SG_ 383 FPM_Encrypted_Result4 0;
BA_REL_ "GenSigTimeoutTime" BU_SG_REL_ CGW_CCU SG_ 383 FPM_Encrypted_Result4 0;
BA_ "Version" SG_ 383 FPM_Encrypted_Result4 "21.07.05";
BA_ "GenMsgCycleTime" BO_ 399 0;
BA_ "Description" SG_ 399 FPM_FPStartAuthResult "signal for fingerprint fail result of Engine start function.

AVN contorls Power on to authenticate PIN code according to this signal.";
BA_ "GenSigSendType" SG_ 399 FPM_FPStartAuthResult 4;
BA_ "UserSigValidity" SG_ 399 FPM_FPStartAuthResult 0;
BA_REL_ "GenSigTimeoutTime" BU_SG_REL_ CGW_CCU SG_ 399 FPM_FPStartAuthResult 0;
BA_ "Version" SG_ 399 FPM_FPStartAuthResult "20.08.07";
BA_ "Description" SG_ 399 FPM_ISKLearnFB "This signal is Learning Feedback";
BA_ "GenSigSendType" SG_ 399 FPM_ISKLearnFB 4;
BA_ "UserSigValidity" SG_ 399 FPM_ISKLearnFB 0;
BA_REL_ "GenSigTimeoutTime" BU_SG_REL_ CGW_CCU SG_ 399 FPM_ISKLearnFB 0;
BA_ "Version" SG_ 399 FPM_ISKLearnFB "20.03.02";
BA_ "Description" SG_ 399 FPM_USMDispPopup "signal for AVN USM popup.";
BA_ "GenSigSendType" SG_ 399 FPM_USMDispPopup 4;
BA_ "UserSigValidity" SG_ 399 FPM_USMDispPopup 0;
BA_REL_ "GenSigTimeoutTime" BU_SG_REL_ CGW_CCU SG_ 399 FPM_USMDispPopup 0;
BA_ "Version" SG_ 399 FPM_USMDispPopup "20.05.02";
BA_ "GenMsgSendType" BO_ 415 0;
BA_ "Description" SG_ 415 FPM_FPFuntionEnableRValue "USM menu for Fingerprint Function Enable/Disable check box

- Disable : Function disable

- Enable : Function enable";
BA_ "GenSigSendType" SG_ 415 FPM_FPFuntionEnableRValue 4;
BA_ "UserSigValidity" SG_ 415 FPM_FPFuntionEnableRValue 0;
BA_REL_ "GenSigTimeoutTime" BU_SG_REL_ CGW_CCU SG_ 415 FPM_FPFuntionEnableRValue 1500;
BA_ "Version" SG_ 415 FPM_FPFuntionEnableRValue "19.09.05";
BA_ "Description" SG_ 415 FPM_User2_SecondFPRValue "Rvalue for USM menu 'User2 - Second Fingerprint Enroll/Delete' Enable/Disable  

- Disable : Unenrolled state

- Enable : Enrolled state";
BA_ "GenSigSendType" SG_ 415 FPM_User2_SecondFPRValue 4;
BA_ "UserSigValidity" SG_ 415 FPM_User2_SecondFPRValue 0;
BA_REL_ "GenSigTimeoutTime" BU_SG_REL_ CGW_CCU SG_ 415 FPM_User2_SecondFPRValue 1500;
BA_ "Version" SG_ 415 FPM_User2_SecondFPRValue "19.09.05";
BA_ "Description" SG_ 415 FPM_User2_ThirdFPRValue "Rvalue for USM menu 'User2 - Third Fingerprint Enroll/Delete' Enable/Disable  

- Disable : Unenrolled state

- Enable : Enrolled state";
BA_ "GenSigSendType" SG_ 415 FPM_User2_ThirdFPRValue 4;
BA_ "UserSigValidity" SG_ 415 FPM_User2_ThirdFPRValue 0;
BA_REL_ "GenSigTimeoutTime" BU_SG_REL_ CGW_CCU SG_ 415 FPM_User2_ThirdFPRValue 1500;
BA_ "Version" SG_ 415 FPM_User2_ThirdFPRValue "19.09.05";
BA_ "Description" SG_ 415 FPM_FPEnrollState "Fingerprint Enrollment processing state. 

- Touch : Place a finger on the Start/Stop button sensor

- Lift : Lift a finger off

- AdjustPosition : For the best results, move the finger upward or downward slightly between attempts. 

- Try Touch Again : Place the fingerprint again

- Processing : Enrollment process is working

- Completed : Enrollment process success

- Failed : Enrollment process fail";
BA_ "GenSigSendType" SG_ 415 FPM_FPEnrollState 4;
BA_ "UserSigValidity" SG_ 415 FPM_FPEnrollState 0;
BA_REL_ "GenSigTimeoutTime" BU_SG_REL_ CGW_CCU SG_ 415 FPM_FPEnrollState 1500;
BA_ "Version" SG_ 415 FPM_FPEnrollState "19.12.07";
BA_ "Description" SG_ 415 FPM_User1_FirstFPRValue "Rvalue for USM menu 'User1 - First Fingerprint Enroll/Delete' Enable/Disable  

- Disable : Unenrolled state

- Enable : Enrolled state";
BA_ "GenSigSendType" SG_ 415 FPM_User1_FirstFPRValue 4;
BA_ "UserSigValidity" SG_ 415 FPM_User1_FirstFPRValue 0;
BA_REL_ "GenSigTimeoutTime" BU_SG_REL_ CGW_CCU SG_ 415 FPM_User1_FirstFPRValue 1500;
BA_ "Version" SG_ 415 FPM_User1_FirstFPRValue "19.09.05";
BA_ "Description" SG_ 415 FPM_FPDeleteState "Fingerprint Delete processing state";
BA_ "GenSigSendType" SG_ 415 FPM_FPDeleteState 4;
BA_ "UserSigValidity" SG_ 415 FPM_FPDeleteState 0;
BA_REL_ "GenSigTimeoutTime" BU_SG_REL_ CGW_CCU SG_ 415 FPM_FPDeleteState 1500;
BA_ "Version" SG_ 415 FPM_FPDeleteState "19.09.05";
BA_ "Description" SG_ 415 FPM_EnrollProgress "Fingerprint Enroll progress rate (0~100%)";
BA_ "GenSigSendType" SG_ 415 FPM_EnrollProgress 4;
BA_ "UserSigValidity" SG_ 415 FPM_EnrollProgress 0;
BA_REL_ "GenSigTimeoutTime" BU_SG_REL_ CGW_CCU SG_ 415 FPM_EnrollProgress 1500;
BA_ "Version" SG_ 415 FPM_EnrollProgress "21.07.05";
BA_ "Description" SG_ 415 FPM_ISKLearnState "FPM State for encryption key learning";
BA_ "GenSigSendType" SG_ 415 FPM_ISKLearnState 4;
BA_ "UserSigValidity" SG_ 415 FPM_ISKLearnState 0;
BA_REL_ "GenSigTimeoutTime" BU_SG_REL_ CGW_CCU SG_ 415 FPM_ISKLearnState 1500;
BA_ "Version" SG_ 415 FPM_ISKLearnState "19.09.05";
BA_ "Description" SG_ 415 FPM_ReadyToSendData "This signal is sent when FPM is ready to send encryption data";
BA_ "GenSigSendType" SG_ 415 FPM_ReadyToSendData 4;
BA_ "UserSigValidity" SG_ 415 FPM_ReadyToSendData 0;
BA_REL_ "GenSigTimeoutTime" BU_SG_REL_ CGW_CCU SG_ 415 FPM_ReadyToSendData 1500;
BA_ "Version" SG_ 415 FPM_ReadyToSendData "19.12.07";
BA_ "GenSigSendType" SG_ 415 FPM_Option 4;
BA_ "UserSigValidity" SG_ 415 FPM_Option 0;
BA_REL_ "GenSigTimeoutTime" BU_SG_REL_ CGW_CCU SG_ 415 FPM_Option 1500;
BA_ "Version" SG_ 415 FPM_Option "20.05.02";
BA_ "Description" SG_ 415 FPM_User1_SecondFPRValue "Rvalue for USM menu 'User1 - Second Fingerprint Enroll/Delete' Enable/Disable  

- Disable : Unenrolled state

- Enable : Enrolled state";
BA_ "GenSigSendType" SG_ 415 FPM_User1_SecondFPRValue 4;
BA_ "UserSigValidity" SG_ 415 FPM_User1_SecondFPRValue 0;
BA_REL_ "GenSigTimeoutTime" BU_SG_REL_ CGW_CCU SG_ 415 FPM_User1_SecondFPRValue 1500;
BA_ "Version" SG_ 415 FPM_User1_SecondFPRValue "19.09.05";
BA_ "Description" SG_ 415 FPMwIAULearnState "FPM ISK Learn state (with IAU)";
BA_ "GenSigSendType" SG_ 415 FPMwIAULearnState 4;
BA_ "UserSigValidity" SG_ 415 FPMwIAULearnState 0;
BA_REL_ "GenSigTimeoutTime" BU_SG_REL_ CGW_CCU SG_ 415 FPMwIAULearnState 1500;
BA_ "Version" SG_ 415 FPMwIAULearnState "20.05.02";
BA_ "Description" SG_ 415 FPM_DISPWrng "This signal is for CLU warning display popup. 

- FP is limited for a few min.

- FP success/fail for Engine start.";
BA_ "GenSigSendType" SG_ 415 FPM_DISPWrng 4;
BA_ "UserSigValidity" SG_ 415 FPM_DISPWrng 0;
BA_REL_ "GenSigTimeoutTime" BU_SG_REL_ CGW_CCU SG_ 415 FPM_DISPWrng 1500;
BA_ "Version" SG_ 415 FPM_DISPWrng "20.05.02";
BA_ "Description" SG_ 415 FPM2IAU_RdyToSendAuthData "This signal is sent when FPM is ready to send encryption data to IAU.";
BA_ "GenSigSendType" SG_ 415 FPM2IAU_RdyToSendAuthData 4;
BA_ "UserSigValidity" SG_ 415 FPM2IAU_RdyToSendAuthData 0;
BA_REL_ "GenSigTimeoutTime" BU_SG_REL_ CGW_CCU SG_ 415 FPM2IAU_RdyToSendAuthData 1500;
BA_ "Version" SG_ 415 FPM2IAU_RdyToSendAuthData "20.05.02";
BA_ "Description" SG_ 415 FPM_FPStartUseRvalue "The signal for fingerprint Engine start function of AVN USM menu. 

This is for both Profile 1, 2.";
BA_ "GenSigSendType" SG_ 415 FPM_FPStartUseRvalue 4;
BA_ "UserSigValidity" SG_ 415 FPM_FPStartUseRvalue 0;
BA_REL_ "GenSigTimeoutTime" BU_SG_REL_ CGW_CCU SG_ 415 FPM_FPStartUseRvalue 1500;
BA_ "Version" SG_ 415 FPM_FPStartUseRvalue "20.05.02";
BA_ "Description" SG_ 415 FPM_FPStartUseState "This signal is of FPM state for fingerprint Engine start.

IAU, IBU, and FRU controls according to this signal. 

 - 0x1 (FPstart_disable) : both user 1, 2  don't use FP engine start.

 - 0x2 (FPstart_enable) : any of user 1, 2 use FP engine start.";
BA_ "GenSigSendType" SG_ 415 FPM_FPStartUseState 4;
BA_ "UserSigValidity" SG_ 415 FPM_FPStartUseState 0;
BA_REL_ "GenSigTimeoutTime" BU_SG_REL_ CGW_CCU SG_ 415 FPM_FPStartUseState 1500;
BA_ "Version" SG_ 415 FPM_FPStartUseState "20.05.02";
BA_ "Description" SG_ 415 FPM_User1_ThirdFPRValue "Rvalue for USM menu 'User1 - Third Fingerprint Enroll/Delete' Enable/Disable  

- Disable : Unenrolled state

- Enable : Enrolled state";
BA_ "GenSigSendType" SG_ 415 FPM_User1_ThirdFPRValue 4;
BA_ "UserSigValidity" SG_ 415 FPM_User1_ThirdFPRValue 0;
BA_REL_ "GenSigTimeoutTime" BU_SG_REL_ CGW_CCU SG_ 415 FPM_User1_ThirdFPRValue 1500;
BA_ "Version" SG_ 415 FPM_User1_ThirdFPRValue "19.09.05";
BA_ "Description" SG_ 415 FPM_User2_FirstFPRValue "Rvalue for USM menu 'User2 - First Fingerprint Enroll/Delete' Enable/Disable  

- Disable : Unenrolled state

- Enable : Enrolled state";
BA_ "GenSigSendType" SG_ 415 FPM_User2_FirstFPRValue 4;
BA_ "UserSigValidity" SG_ 415 FPM_User2_FirstFPRValue 0;
BA_REL_ "GenSigTimeoutTime" BU_SG_REL_ CGW_CCU SG_ 415 FPM_User2_FirstFPRValue 1500;
BA_ "Version" SG_ 415 FPM_User2_FirstFPRValue "19.09.05";
BA_ "GenMsgCycleTime" BO_ 1476 0;
BA_ "GenMsgCycleTimeFast" BO_ 1476 0;
BA_ "GenMsgNrOfRepetition" BO_ 1476 0;
BA_ "DiagRequest" BO_ 1476 1;
BA_ "GenMsgILSupport" BO_ 1476 0;
BA_ "TpMessage" BO_ 1476 1;
BA_ "TpTxIndex" BO_ 1476 216;
BA_ "Description" SG_ 1476 GST_ASAU_Byte0 "TP Index : 216";
BA_ "UsrSigPurpose" SG_ 1476 GST_ASAU_Byte0 3;
BA_ "UserSigValidity" SG_ 1476 GST_ASAU_Byte0 0;
BA_REL_ "GenSigTimeoutTime" BU_SG_REL_ vHS_M SG_ 1476 GST_ASAU_Byte0 0;
BA_REL_ "GenSigTimeoutTime" BU_SG_REL_ ASAU SG_ 1476 GST_ASAU_Byte0 0;
BA_ "NetworkRequest" SG_ 1476 GST_ASAU_Byte0 0;
BA_ "NetworkRequestHoldingTime" SG_ 1476 GST_ASAU_Byte0 5000;
BA_ "Version" SG_ 1476 GST_ASAU_Byte0 "21.02.04";
BA_ "Description" SG_ 1476 GST_ASAU_Byte2 "TP Index : 216";
BA_ "UsrSigPurpose" SG_ 1476 GST_ASAU_Byte2 3;
BA_ "UserSigValidity" SG_ 1476 GST_ASAU_Byte2 0;
BA_REL_ "GenSigTimeoutTime" BU_SG_REL_ vHS_M SG_ 1476 GST_ASAU_Byte2 0;
BA_REL_ "GenSigTimeoutTime" BU_SG_REL_ ASAU SG_ 1476 GST_ASAU_Byte2 0;
BA_ "NetworkRequest" SG_ 1476 GST_ASAU_Byte2 0;
BA_ "NetworkRequestHoldingTime" SG_ 1476 GST_ASAU_Byte2 5000;
BA_ "Version" SG_ 1476 GST_ASAU_Byte2 "21.02.04";
BA_ "Description" SG_ 1476 GST_ASAU_Byte3 "TP Index : 216";
BA_ "UsrSigPurpose" SG_ 1476 GST_ASAU_Byte3 3;
BA_ "UserSigValidity" SG_ 1476 GST_ASAU_Byte3 0;
BA_REL_ "GenSigTimeoutTime" BU_SG_REL_ vHS_M SG_ 1476 GST_ASAU_Byte3 0;
BA_REL_ "GenSigTimeoutTime" BU_SG_REL_ ASAU SG_ 1476 GST_ASAU_Byte3 0;
BA_ "NetworkRequest" SG_ 1476 GST_ASAU_Byte3 0;
BA_ "NetworkRequestHoldingTime" SG_ 1476 GST_ASAU_Byte3 5000;
BA_ "Version" SG_ 1476 GST_ASAU_Byte3 "21.02.04";
BA_ "Description" SG_ 1476 GST_ASAU_Byte4 "TP Index : 216";
BA_ "UsrSigPurpose" SG_ 1476 GST_ASAU_Byte4 3;
BA_ "UserSigValidity" SG_ 1476 GST_ASAU_Byte4 0;
BA_REL_ "GenSigTimeoutTime" BU_SG_REL_ vHS_M SG_ 1476 GST_ASAU_Byte4 0;
BA_REL_ "GenSigTimeoutTime" BU_SG_REL_ ASAU SG_ 1476 GST_ASAU_Byte4 0;
BA_ "NetworkRequest" SG_ 1476 GST_ASAU_Byte4 0;
BA_ "NetworkRequestHoldingTime" SG_ 1476 GST_ASAU_Byte4 5000;
BA_ "Version" SG_ 1476 GST_ASAU_Byte4 "21.02.04";
BA_ "Description" SG_ 1476 GST_ASAU_Byte5 "TP Index : 216";
BA_ "UsrSigPurpose" SG_ 1476 GST_ASAU_Byte5 3;
BA_ "UserSigValidity" SG_ 1476 GST_ASAU_Byte5 0;
BA_REL_ "GenSigTimeoutTime" BU_SG_REL_ vHS_M SG_ 1476 GST_ASAU_Byte5 0;
BA_REL_ "GenSigTimeoutTime" BU_SG_REL_ ASAU SG_ 1476 GST_ASAU_Byte5 0;
BA_ "NetworkRequest" SG_ 1476 GST_ASAU_Byte5 0;
BA_ "NetworkRequestHoldingTime" SG_ 1476 GST_ASAU_Byte5 5000;
BA_ "Version" SG_ 1476 GST_ASAU_Byte5 "21.02.04";
BA_ "Description" SG_ 1476 GST_ASAU_Byte6 "TP Index : 216";
BA_ "UsrSigPurpose" SG_ 1476 GST_ASAU_Byte6 3;
BA_ "UserSigValidity" SG_ 1476 GST_ASAU_Byte6 0;
BA_REL_ "GenSigTimeoutTime" BU_SG_REL_ vHS_M SG_ 1476 GST_ASAU_Byte6 0;
BA_REL_ "GenSigTimeoutTime" BU_SG_REL_ ASAU SG_ 1476 GST_ASAU_Byte6 0;
BA_ "NetworkRequest" SG_ 1476 GST_ASAU_Byte6 0;
BA_ "NetworkRequestHoldingTime" SG_ 1476 GST_ASAU_Byte6 5000;
BA_ "Version" SG_ 1476 GST_ASAU_Byte6 "21.02.04";
BA_ "Description" SG_ 1476 GST_ASAU_Byte7 "TP Index : 216";
BA_ "UsrSigPurpose" SG_ 1476 GST_ASAU_Byte7 3;
BA_ "UserSigValidity" SG_ 1476 GST_ASAU_Byte7 0;
BA_REL_ "GenSigTimeoutTime" BU_SG_REL_ vHS_M SG_ 1476 GST_ASAU_Byte7 0;
BA_REL_ "GenSigTimeoutTime" BU_SG_REL_ ASAU SG_ 1476 GST_ASAU_Byte7 0;
BA_ "NetworkRequest" SG_ 1476 GST_ASAU_Byte7 0;
BA_ "NetworkRequestHoldingTime" SG_ 1476 GST_ASAU_Byte7 5000;
BA_ "Version" SG_ 1476 GST_ASAU_Byte7 "21.02.04";
BA_ "Description" SG_ 1476 GST_ASAU_Byte1 "TP Index : 216";
BA_ "UsrSigPurpose" SG_ 1476 GST_ASAU_Byte1 3;
BA_ "UserSigValidity" SG_ 1476 GST_ASAU_Byte1 0;
BA_REL_ "GenSigTimeoutTime" BU_SG_REL_ vHS_M SG_ 1476 GST_ASAU_Byte1 0;
BA_REL_ "GenSigTimeoutTime" BU_SG_REL_ ASAU SG_ 1476 GST_ASAU_Byte1 0;
BA_ "NetworkRequest" SG_ 1476 GST_ASAU_Byte1 0;
BA_ "NetworkRequestHoldingTime" SG_ 1476 GST_ASAU_Byte1 5000;
BA_ "Version" SG_ 1476 GST_ASAU_Byte1 "21.02.04";
BA_ "GenMsgCycleTime" BO_ 1475 0;
BA_ "GenMsgCycleTimeFast" BO_ 1475 0;
BA_ "GenMsgNrOfRepetition" BO_ 1475 0;
BA_ "DiagRequest" BO_ 1475 1;
BA_ "GenMsgILSupport" BO_ 1475 0;
BA_ "TpMessage" BO_ 1475 1;
BA_ "TpTxIndex" BO_ 1475 215;
BA_ "Description" SG_ 1475 GST_DSAU_Byte0 "TP Index : 215";
BA_ "UsrSigPurpose" SG_ 1475 GST_DSAU_Byte0 3;
BA_ "UserSigValidity" SG_ 1475 GST_DSAU_Byte0 0;
BA_REL_ "GenSigTimeoutTime" BU_SG_REL_ vHS_M SG_ 1475 GST_DSAU_Byte0 0;
BA_REL_ "GenSigTimeoutTime" BU_SG_REL_ DSAU SG_ 1475 GST_DSAU_Byte0 0;
BA_ "NetworkRequest" SG_ 1475 GST_DSAU_Byte0 0;
BA_ "NetworkRequestHoldingTime" SG_ 1475 GST_DSAU_Byte0 5000;
BA_ "Version" SG_ 1475 GST_DSAU_Byte0 "21.02.04";
BA_ "Description" SG_ 1475 GST_DSAU_Byte2 "TP Index : 215";
BA_ "UsrSigPurpose" SG_ 1475 GST_DSAU_Byte2 3;
BA_ "UserSigValidity" SG_ 1475 GST_DSAU_Byte2 0;
BA_REL_ "GenSigTimeoutTime" BU_SG_REL_ vHS_M SG_ 1475 GST_DSAU_Byte2 0;
BA_REL_ "GenSigTimeoutTime" BU_SG_REL_ DSAU SG_ 1475 GST_DSAU_Byte2 0;
BA_ "NetworkRequest" SG_ 1475 GST_DSAU_Byte2 0;
BA_ "NetworkRequestHoldingTime" SG_ 1475 GST_DSAU_Byte2 5000;
BA_ "Version" SG_ 1475 GST_DSAU_Byte2 "21.02.04";
BA_ "Description" SG_ 1475 GST_DSAU_Byte3 "TP Index : 215";
BA_ "UsrSigPurpose" SG_ 1475 GST_DSAU_Byte3 3;
BA_ "UserSigValidity" SG_ 1475 GST_DSAU_Byte3 0;
BA_REL_ "GenSigTimeoutTime" BU_SG_REL_ vHS_M SG_ 1475 GST_DSAU_Byte3 0;
BA_REL_ "GenSigTimeoutTime" BU_SG_REL_ DSAU SG_ 1475 GST_DSAU_Byte3 0;
BA_ "NetworkRequest" SG_ 1475 GST_DSAU_Byte3 0;
BA_ "NetworkRequestHoldingTime" SG_ 1475 GST_DSAU_Byte3 5000;
BA_ "Version" SG_ 1475 GST_DSAU_Byte3 "21.02.04";
BA_ "Description" SG_ 1475 GST_DSAU_Byte4 "TP Index : 215";
BA_ "UsrSigPurpose" SG_ 1475 GST_DSAU_Byte4 3;
BA_ "UserSigValidity" SG_ 1475 GST_DSAU_Byte4 0;
BA_REL_ "GenSigTimeoutTime" BU_SG_REL_ vHS_M SG_ 1475 GST_DSAU_Byte4 0;
BA_REL_ "GenSigTimeoutTime" BU_SG_REL_ DSAU SG_ 1475 GST_DSAU_Byte4 0;
BA_ "NetworkRequest" SG_ 1475 GST_DSAU_Byte4 0;
BA_ "NetworkRequestHoldingTime" SG_ 1475 GST_DSAU_Byte4 5000;
BA_ "Version" SG_ 1475 GST_DSAU_Byte4 "21.02.04";
BA_ "Description" SG_ 1475 GST_DSAU_Byte5 "TP Index : 215";
BA_ "UsrSigPurpose" SG_ 1475 GST_DSAU_Byte5 3;
BA_ "UserSigValidity" SG_ 1475 GST_DSAU_Byte5 0;
BA_REL_ "GenSigTimeoutTime" BU_SG_REL_ vHS_M SG_ 1475 GST_DSAU_Byte5 0;
BA_REL_ "GenSigTimeoutTime" BU_SG_REL_ DSAU SG_ 1475 GST_DSAU_Byte5 0;
BA_ "NetworkRequest" SG_ 1475 GST_DSAU_Byte5 0;
BA_ "NetworkRequestHoldingTime" SG_ 1475 GST_DSAU_Byte5 5000;
BA_ "Version" SG_ 1475 GST_DSAU_Byte5 "21.02.04";
BA_ "Description" SG_ 1475 GST_DSAU_Byte6 "TP Index : 215";
BA_ "UsrSigPurpose" SG_ 1475 GST_DSAU_Byte6 3;
BA_ "UserSigValidity" SG_ 1475 GST_DSAU_Byte6 0;
BA_REL_ "GenSigTimeoutTime" BU_SG_REL_ vHS_M SG_ 1475 GST_DSAU_Byte6 0;
BA_REL_ "GenSigTimeoutTime" BU_SG_REL_ DSAU SG_ 1475 GST_DSAU_Byte6 0;
BA_ "NetworkRequest" SG_ 1475 GST_DSAU_Byte6 0;
BA_ "NetworkRequestHoldingTime" SG_ 1475 GST_DSAU_Byte6 5000;
BA_ "Version" SG_ 1475 GST_DSAU_Byte6 "21.02.04";
BA_ "Description" SG_ 1475 GST_DSAU_Byte7 "TP Index : 215";
BA_ "UsrSigPurpose" SG_ 1475 GST_DSAU_Byte7 3;
BA_ "UserSigValidity" SG_ 1475 GST_DSAU_Byte7 0;
BA_REL_ "GenSigTimeoutTime" BU_SG_REL_ vHS_M SG_ 1475 GST_DSAU_Byte7 0;
BA_REL_ "GenSigTimeoutTime" BU_SG_REL_ DSAU SG_ 1475 GST_DSAU_Byte7 0;
BA_ "NetworkRequest" SG_ 1475 GST_DSAU_Byte7 0;
BA_ "NetworkRequestHoldingTime" SG_ 1475 GST_DSAU_Byte7 5000;
BA_ "Version" SG_ 1475 GST_DSAU_Byte7 "21.02.04";
BA_ "Description" SG_ 1475 GST_DSAU_Byte1 "TP Index : 215";
BA_ "UsrSigPurpose" SG_ 1475 GST_DSAU_Byte1 3;
BA_ "UserSigValidity" SG_ 1475 GST_DSAU_Byte1 0;
BA_REL_ "GenSigTimeoutTime" BU_SG_REL_ vHS_M SG_ 1475 GST_DSAU_Byte1 0;
BA_REL_ "GenSigTimeoutTime" BU_SG_REL_ DSAU SG_ 1475 GST_DSAU_Byte1 0;
BA_ "NetworkRequest" SG_ 1475 GST_DSAU_Byte1 0;
BA_ "NetworkRequestHoldingTime" SG_ 1475 GST_DSAU_Byte1 5000;
BA_ "Version" SG_ 1475 GST_DSAU_Byte1 "21.02.04";
BA_ "GenMsgCycleTime" BO_ 1810 0;
BA_ "GenMsgCycleTimeFast" BO_ 1810 0;
BA_ "GenMsgNrOfRepetition" BO_ 1810 0;
BA_ "DiagRequest" BO_ 1810 1;
BA_ "GenMsgILSupport" BO_ 1810 0;
BA_ "TpMessage" BO_ 1810 1;
BA_ "TpTxIndex" BO_ 1810 160;
BA_ "Description" SG_ 1810 GST_RLHVU_Byte0 "TP Index : 160";
BA_ "UsrSigPurpose" SG_ 1810 GST_RLHVU_Byte0 3;
BA_ "UserSigValidity" SG_ 1810 GST_RLHVU_Byte0 0;
BA_REL_ "GenSigTimeoutTime" BU_SG_REL_ RLHV SG_ 1810 GST_RLHVU_Byte0 0;
BA_REL_ "GenSigTimeoutTime" BU_SG_REL_ vHS_M SG_ 1810 GST_RLHVU_Byte0 0;
BA_ "NetworkRequest" SG_ 1810 GST_RLHVU_Byte0 0;
BA_ "NetworkRequestHoldingTime" SG_ 1810 GST_RLHVU_Byte0 5000;
BA_ "Version" SG_ 1810 GST_RLHVU_Byte0 "21.02.04";
BA_ "Description" SG_ 1810 GST_RLHVU_Byte2 "TP Index : 160";
BA_ "UsrSigPurpose" SG_ 1810 GST_RLHVU_Byte2 3;
BA_ "UserSigValidity" SG_ 1810 GST_RLHVU_Byte2 0;
BA_REL_ "GenSigTimeoutTime" BU_SG_REL_ RLHV SG_ 1810 GST_RLHVU_Byte2 0;
BA_REL_ "GenSigTimeoutTime" BU_SG_REL_ vHS_M SG_ 1810 GST_RLHVU_Byte2 0;
BA_ "NetworkRequest" SG_ 1810 GST_RLHVU_Byte2 0;
BA_ "NetworkRequestHoldingTime" SG_ 1810 GST_RLHVU_Byte2 5000;
BA_ "Version" SG_ 1810 GST_RLHVU_Byte2 "21.02.04";
BA_ "Description" SG_ 1810 GST_RLHVU_Byte3 "TP Index : 160";
BA_ "UsrSigPurpose" SG_ 1810 GST_RLHVU_Byte3 3;
BA_ "UserSigValidity" SG_ 1810 GST_RLHVU_Byte3 0;
BA_REL_ "GenSigTimeoutTime" BU_SG_REL_ RLHV SG_ 1810 GST_RLHVU_Byte3 0;
BA_REL_ "GenSigTimeoutTime" BU_SG_REL_ vHS_M SG_ 1810 GST_RLHVU_Byte3 0;
BA_ "NetworkRequest" SG_ 1810 GST_RLHVU_Byte3 0;
BA_ "NetworkRequestHoldingTime" SG_ 1810 GST_RLHVU_Byte3 5000;
BA_ "Version" SG_ 1810 GST_RLHVU_Byte3 "21.02.04";
BA_ "Description" SG_ 1810 GST_RLHVU_Byte4 "TP Index : 160";
BA_ "UsrSigPurpose" SG_ 1810 GST_RLHVU_Byte4 3;
BA_ "UserSigValidity" SG_ 1810 GST_RLHVU_Byte4 0;
BA_REL_ "GenSigTimeoutTime" BU_SG_REL_ RLHV SG_ 1810 GST_RLHVU_Byte4 0;
BA_REL_ "GenSigTimeoutTime" BU_SG_REL_ vHS_M SG_ 1810 GST_RLHVU_Byte4 0;
BA_ "NetworkRequest" SG_ 1810 GST_RLHVU_Byte4 0;
BA_ "NetworkRequestHoldingTime" SG_ 1810 GST_RLHVU_Byte4 5000;
BA_ "Version" SG_ 1810 GST_RLHVU_Byte4 "21.02.04";
BA_ "Description" SG_ 1810 GST_RLHVU_Byte5 "TP Index : 160";
BA_ "UsrSigPurpose" SG_ 1810 GST_RLHVU_Byte5 3;
BA_ "UserSigValidity" SG_ 1810 GST_RLHVU_Byte5 0;
BA_REL_ "GenSigTimeoutTime" BU_SG_REL_ RLHV SG_ 1810 GST_RLHVU_Byte5 0;
BA_REL_ "GenSigTimeoutTime" BU_SG_REL_ vHS_M SG_ 1810 GST_RLHVU_Byte5 0;
BA_ "NetworkRequest" SG_ 1810 GST_RLHVU_Byte5 0;
BA_ "NetworkRequestHoldingTime" SG_ 1810 GST_RLHVU_Byte5 5000;
BA_ "Version" SG_ 1810 GST_RLHVU_Byte5 "21.02.04";
BA_ "Description" SG_ 1810 GST_RLHVU_Byte6 "TP Index : 160";
BA_ "UsrSigPurpose" SG_ 1810 GST_RLHVU_Byte6 3;
BA_ "UserSigValidity" SG_ 1810 GST_RLHVU_Byte6 0;
BA_REL_ "GenSigTimeoutTime" BU_SG_REL_ RLHV SG_ 1810 GST_RLHVU_Byte6 0;
BA_REL_ "GenSigTimeoutTime" BU_SG_REL_ vHS_M SG_ 1810 GST_RLHVU_Byte6 0;
BA_ "NetworkRequest" SG_ 1810 GST_RLHVU_Byte6 0;
BA_ "NetworkRequestHoldingTime" SG_ 1810 GST_RLHVU_Byte6 5000;
BA_ "Version" SG_ 1810 GST_RLHVU_Byte6 "21.02.04";
BA_ "Description" SG_ 1810 GST_RLHVU_Byte7 "TP Index : 160";
BA_ "UsrSigPurpose" SG_ 1810 GST_RLHVU_Byte7 3;
BA_ "UserSigValidity" SG_ 1810 GST_RLHVU_Byte7 0;
BA_REL_ "GenSigTimeoutTime" BU_SG_REL_ RLHV SG_ 1810 GST_RLHVU_Byte7 0;
BA_REL_ "GenSigTimeoutTime" BU_SG_REL_ vHS_M SG_ 1810 GST_RLHVU_Byte7 0;
BA_ "NetworkRequest" SG_ 1810 GST_RLHVU_Byte7 0;
BA_ "NetworkRequestHoldingTime" SG_ 1810 GST_RLHVU_Byte7 5000;
BA_ "Version" SG_ 1810 GST_RLHVU_Byte7 "21.02.04";
BA_ "Description" SG_ 1810 GST_RLHVU_Byte1 "TP Index : 160";
BA_ "UsrSigPurpose" SG_ 1810 GST_RLHVU_Byte1 3;
BA_ "UserSigValidity" SG_ 1810 GST_RLHVU_Byte1 0;
BA_REL_ "GenSigTimeoutTime" BU_SG_REL_ RLHV SG_ 1810 GST_RLHVU_Byte1 0;
BA_REL_ "GenSigTimeoutTime" BU_SG_REL_ vHS_M SG_ 1810 GST_RLHVU_Byte1 0;
BA_ "NetworkRequest" SG_ 1810 GST_RLHVU_Byte1 0;
BA_ "NetworkRequestHoldingTime" SG_ 1810 GST_RLHVU_Byte1 5000;
BA_ "Version" SG_ 1810 GST_RLHVU_Byte1 "21.02.04";
BA_ "GenMsgCycleTime" BO_ 1478 0;
BA_ "GenMsgCycleTimeFast" BO_ 1478 0;
BA_ "GenMsgNrOfRepetition" BO_ 1478 0;
BA_ "DiagRequest" BO_ 1478 1;
BA_ "GenMsgILSupport" BO_ 1478 0;
BA_ "TpMessage" BO_ 1478 1;
BA_ "TpTxIndex" BO_ 1478 218;
BA_ "Description" SG_ 1478 GST_RLPSS_Byte0 "TP Index : 218";
BA_ "UsrSigPurpose" SG_ 1478 GST_RLPSS_Byte0 3;
BA_ "UserSigValidity" SG_ 1478 GST_RLPSS_Byte0 0;
BA_REL_ "GenSigTimeoutTime" BU_SG_REL_ RLPSM SG_ 1478 GST_RLPSS_Byte0 0;
BA_REL_ "GenSigTimeoutTime" BU_SG_REL_ vHS_M SG_ 1478 GST_RLPSS_Byte0 0;
BA_ "NetworkRequest" SG_ 1478 GST_RLPSS_Byte0 0;
BA_ "NetworkRequestHoldingTime" SG_ 1478 GST_RLPSS_Byte0 5000;
BA_ "Version" SG_ 1478 GST_RLPSS_Byte0 "21.02.04";
BA_ "Description" SG_ 1478 GST_RLPSS_Byte2 "TP Index : 218";
BA_ "UsrSigPurpose" SG_ 1478 GST_RLPSS_Byte2 3;
BA_ "UserSigValidity" SG_ 1478 GST_RLPSS_Byte2 0;
BA_REL_ "GenSigTimeoutTime" BU_SG_REL_ RLPSM SG_ 1478 GST_RLPSS_Byte2 0;
BA_REL_ "GenSigTimeoutTime" BU_SG_REL_ vHS_M SG_ 1478 GST_RLPSS_Byte2 0;
BA_ "NetworkRequest" SG_ 1478 GST_RLPSS_Byte2 0;
BA_ "NetworkRequestHoldingTime" SG_ 1478 GST_RLPSS_Byte2 5000;
BA_ "Version" SG_ 1478 GST_RLPSS_Byte2 "21.02.04";
BA_ "Description" SG_ 1478 GST_RLPSS_Byte3 "TP Index : 218";
BA_ "UsrSigPurpose" SG_ 1478 GST_RLPSS_Byte3 3;
BA_ "UserSigValidity" SG_ 1478 GST_RLPSS_Byte3 0;
BA_REL_ "GenSigTimeoutTime" BU_SG_REL_ RLPSM SG_ 1478 GST_RLPSS_Byte3 0;
BA_REL_ "GenSigTimeoutTime" BU_SG_REL_ vHS_M SG_ 1478 GST_RLPSS_Byte3 0;
BA_ "NetworkRequest" SG_ 1478 GST_RLPSS_Byte3 0;
BA_ "NetworkRequestHoldingTime" SG_ 1478 GST_RLPSS_Byte3 5000;
BA_ "Version" SG_ 1478 GST_RLPSS_Byte3 "21.02.04";
BA_ "Description" SG_ 1478 GST_RLPSS_Byte4 "TP Index : 218";
BA_ "UsrSigPurpose" SG_ 1478 GST_RLPSS_Byte4 3;
BA_ "UserSigValidity" SG_ 1478 GST_RLPSS_Byte4 0;
BA_REL_ "GenSigTimeoutTime" BU_SG_REL_ RLPSM SG_ 1478 GST_RLPSS_Byte4 0;
BA_REL_ "GenSigTimeoutTime" BU_SG_REL_ vHS_M SG_ 1478 GST_RLPSS_Byte4 0;
BA_ "NetworkRequest" SG_ 1478 GST_RLPSS_Byte4 0;
BA_ "NetworkRequestHoldingTime" SG_ 1478 GST_RLPSS_Byte4 5000;
BA_ "Version" SG_ 1478 GST_RLPSS_Byte4 "21.02.04";
BA_ "Description" SG_ 1478 GST_RLPSS_Byte5 "TP Index : 218";
BA_ "UsrSigPurpose" SG_ 1478 GST_RLPSS_Byte5 3;
BA_ "UserSigValidity" SG_ 1478 GST_RLPSS_Byte5 0;
BA_REL_ "GenSigTimeoutTime" BU_SG_REL_ RLPSM SG_ 1478 GST_RLPSS_Byte5 0;
BA_REL_ "GenSigTimeoutTime" BU_SG_REL_ vHS_M SG_ 1478 GST_RLPSS_Byte5 0;
BA_ "NetworkRequest" SG_ 1478 GST_RLPSS_Byte5 0;
BA_ "NetworkRequestHoldingTime" SG_ 1478 GST_RLPSS_Byte5 5000;
BA_ "Version" SG_ 1478 GST_RLPSS_Byte5 "21.02.04";
BA_ "Description" SG_ 1478 GST_RLPSS_Byte6 "TP Index : 218";
BA_ "UsrSigPurpose" SG_ 1478 GST_RLPSS_Byte6 3;
BA_ "UserSigValidity" SG_ 1478 GST_RLPSS_Byte6 0;
BA_REL_ "GenSigTimeoutTime" BU_SG_REL_ RLPSM SG_ 1478 GST_RLPSS_Byte6 0;
BA_REL_ "GenSigTimeoutTime" BU_SG_REL_ vHS_M SG_ 1478 GST_RLPSS_Byte6 0;
BA_ "NetworkRequest" SG_ 1478 GST_RLPSS_Byte6 0;
BA_ "NetworkRequestHoldingTime" SG_ 1478 GST_RLPSS_Byte6 5000;
BA_ "Version" SG_ 1478 GST_RLPSS_Byte6 "21.02.04";
BA_ "Description" SG_ 1478 GST_RLPSS_Byte7 "TP Index : 218";
BA_ "UsrSigPurpose" SG_ 1478 GST_RLPSS_Byte7 3;
BA_ "UserSigValidity" SG_ 1478 GST_RLPSS_Byte7 0;
BA_REL_ "GenSigTimeoutTime" BU_SG_REL_ RLPSM SG_ 1478 GST_RLPSS_Byte7 0;
BA_REL_ "GenSigTimeoutTime" BU_SG_REL_ vHS_M SG_ 1478 GST_RLPSS_Byte7 0;
BA_ "NetworkRequest" SG_ 1478 GST_RLPSS_Byte7 0;
BA_ "NetworkRequestHoldingTime" SG_ 1478 GST_RLPSS_Byte7 5000;
BA_ "Version" SG_ 1478 GST_RLPSS_Byte7 "21.02.04";
BA_ "Description" SG_ 1478 GST_RLPSS_Byte1 "TP Index : 218";
BA_ "UsrSigPurpose" SG_ 1478 GST_RLPSS_Byte1 3;
BA_ "UserSigValidity" SG_ 1478 GST_RLPSS_Byte1 0;
BA_REL_ "GenSigTimeoutTime" BU_SG_REL_ RLPSM SG_ 1478 GST_RLPSS_Byte1 0;
BA_REL_ "GenSigTimeoutTime" BU_SG_REL_ vHS_M SG_ 1478 GST_RLPSS_Byte1 0;
BA_ "NetworkRequest" SG_ 1478 GST_RLPSS_Byte1 0;
BA_ "NetworkRequestHoldingTime" SG_ 1478 GST_RLPSS_Byte1 5000;
BA_ "Version" SG_ 1478 GST_RLPSS_Byte1 "21.02.04";
BA_ "GenMsgCycleTime" BO_ 1799 0;
BA_ "GenMsgCycleTimeFast" BO_ 1799 0;
BA_ "GenMsgNrOfRepetition" BO_ 1799 0;
BA_ "DiagRequest" BO_ 1799 1;
BA_ "GenMsgILSupport" BO_ 1799 0;
BA_ "TpMessage" BO_ 1799 1;
BA_ "TpTxIndex" BO_ 1799 165;
BA_ "Description" SG_ 1799 GST_RRHVU_Byte0 "TP Index : 165";
BA_ "UsrSigPurpose" SG_ 1799 GST_RRHVU_Byte0 3;
BA_ "UserSigValidity" SG_ 1799 GST_RRHVU_Byte0 0;
BA_REL_ "GenSigTimeoutTime" BU_SG_REL_ RRHV SG_ 1799 GST_RRHVU_Byte0 0;
BA_REL_ "GenSigTimeoutTime" BU_SG_REL_ SHVU_RR SG_ 1799 GST_RRHVU_Byte0 0;
BA_REL_ "GenSigTimeoutTime" BU_SG_REL_ vHS_M SG_ 1799 GST_RRHVU_Byte0 0;
BA_ "NetworkRequest" SG_ 1799 GST_RRHVU_Byte0 0;
BA_ "NetworkRequestHoldingTime" SG_ 1799 GST_RRHVU_Byte0 5000;
BA_ "Version" SG_ 1799 GST_RRHVU_Byte0 "21.02.04";
BA_ "Description" SG_ 1799 GST_RRHVU_Byte2 "TP Index : 165";
BA_ "UsrSigPurpose" SG_ 1799 GST_RRHVU_Byte2 3;
BA_ "UserSigValidity" SG_ 1799 GST_RRHVU_Byte2 0;
BA_REL_ "GenSigTimeoutTime" BU_SG_REL_ RRHV SG_ 1799 GST_RRHVU_Byte2 0;
BA_REL_ "GenSigTimeoutTime" BU_SG_REL_ SHVU_RR SG_ 1799 GST_RRHVU_Byte2 0;
BA_REL_ "GenSigTimeoutTime" BU_SG_REL_ vHS_M SG_ 1799 GST_RRHVU_Byte2 0;
BA_ "NetworkRequest" SG_ 1799 GST_RRHVU_Byte2 0;
BA_ "NetworkRequestHoldingTime" SG_ 1799 GST_RRHVU_Byte2 5000;
BA_ "Version" SG_ 1799 GST_RRHVU_Byte2 "21.02.04";
BA_ "Description" SG_ 1799 GST_RRHVU_Byte3 "TP Index : 165";
BA_ "UsrSigPurpose" SG_ 1799 GST_RRHVU_Byte3 3;
BA_ "UserSigValidity" SG_ 1799 GST_RRHVU_Byte3 0;
BA_REL_ "GenSigTimeoutTime" BU_SG_REL_ RRHV SG_ 1799 GST_RRHVU_Byte3 0;
BA_REL_ "GenSigTimeoutTime" BU_SG_REL_ SHVU_RR SG_ 1799 GST_RRHVU_Byte3 0;
BA_REL_ "GenSigTimeoutTime" BU_SG_REL_ vHS_M SG_ 1799 GST_RRHVU_Byte3 0;
BA_ "NetworkRequest" SG_ 1799 GST_RRHVU_Byte3 0;
BA_ "NetworkRequestHoldingTime" SG_ 1799 GST_RRHVU_Byte3 5000;
BA_ "Version" SG_ 1799 GST_RRHVU_Byte3 "21.02.04";
BA_ "Description" SG_ 1799 GST_RRHVU_Byte4 "TP Index : 165";
BA_ "UsrSigPurpose" SG_ 1799 GST_RRHVU_Byte4 3;
BA_ "UserSigValidity" SG_ 1799 GST_RRHVU_Byte4 0;
BA_REL_ "GenSigTimeoutTime" BU_SG_REL_ RRHV SG_ 1799 GST_RRHVU_Byte4 0;
BA_REL_ "GenSigTimeoutTime" BU_SG_REL_ SHVU_RR SG_ 1799 GST_RRHVU_Byte4 0;
BA_REL_ "GenSigTimeoutTime" BU_SG_REL_ vHS_M SG_ 1799 GST_RRHVU_Byte4 0;
BA_ "NetworkRequest" SG_ 1799 GST_RRHVU_Byte4 0;
BA_ "NetworkRequestHoldingTime" SG_ 1799 GST_RRHVU_Byte4 5000;
BA_ "Version" SG_ 1799 GST_RRHVU_Byte4 "21.02.04";
BA_ "Description" SG_ 1799 GST_RRHVU_Byte5 "TP Index : 165";
BA_ "UsrSigPurpose" SG_ 1799 GST_RRHVU_Byte5 3;
BA_ "UserSigValidity" SG_ 1799 GST_RRHVU_Byte5 0;
BA_REL_ "GenSigTimeoutTime" BU_SG_REL_ RRHV SG_ 1799 GST_RRHVU_Byte5 0;
BA_REL_ "GenSigTimeoutTime" BU_SG_REL_ SHVU_RR SG_ 1799 GST_RRHVU_Byte5 0;
BA_REL_ "GenSigTimeoutTime" BU_SG_REL_ vHS_M SG_ 1799 GST_RRHVU_Byte5 0;
BA_ "NetworkRequest" SG_ 1799 GST_RRHVU_Byte5 0;
BA_ "NetworkRequestHoldingTime" SG_ 1799 GST_RRHVU_Byte5 5000;
BA_ "Version" SG_ 1799 GST_RRHVU_Byte5 "21.02.04";
BA_ "Description" SG_ 1799 GST_RRHVU_Byte6 "TP Index : 165";
BA_ "UsrSigPurpose" SG_ 1799 GST_RRHVU_Byte6 3;
BA_ "UserSigValidity" SG_ 1799 GST_RRHVU_Byte6 0;
BA_REL_ "GenSigTimeoutTime" BU_SG_REL_ RRHV SG_ 1799 GST_RRHVU_Byte6 0;
BA_REL_ "GenSigTimeoutTime" BU_SG_REL_ SHVU_RR SG_ 1799 GST_RRHVU_Byte6 0;
BA_REL_ "GenSigTimeoutTime" BU_SG_REL_ vHS_M SG_ 1799 GST_RRHVU_Byte6 0;
BA_ "NetworkRequest" SG_ 1799 GST_RRHVU_Byte6 0;
BA_ "NetworkRequestHoldingTime" SG_ 1799 GST_RRHVU_Byte6 5000;
BA_ "Version" SG_ 1799 GST_RRHVU_Byte6 "21.02.04";
BA_ "Description" SG_ 1799 GST_RRHVU_Byte7 "TP Index : 165";
BA_ "UsrSigPurpose" SG_ 1799 GST_RRHVU_Byte7 3;
BA_ "UserSigValidity" SG_ 1799 GST_RRHVU_Byte7 0;
BA_REL_ "GenSigTimeoutTime" BU_SG_REL_ RRHV SG_ 1799 GST_RRHVU_Byte7 0;
BA_REL_ "GenSigTimeoutTime" BU_SG_REL_ SHVU_RR SG_ 1799 GST_RRHVU_Byte7 0;
BA_REL_ "GenSigTimeoutTime" BU_SG_REL_ vHS_M SG_ 1799 GST_RRHVU_Byte7 0;
BA_ "NetworkRequest" SG_ 1799 GST_RRHVU_Byte7 0;
BA_ "NetworkRequestHoldingTime" SG_ 1799 GST_RRHVU_Byte7 5000;
BA_ "Version" SG_ 1799 GST_RRHVU_Byte7 "21.02.04";
BA_ "Description" SG_ 1799 GST_RRHVU_Byte1 "TP Index : 165";
BA_ "UsrSigPurpose" SG_ 1799 GST_RRHVU_Byte1 3;
BA_ "UserSigValidity" SG_ 1799 GST_RRHVU_Byte1 0;
BA_REL_ "GenSigTimeoutTime" BU_SG_REL_ RRHV SG_ 1799 GST_RRHVU_Byte1 0;
BA_REL_ "GenSigTimeoutTime" BU_SG_REL_ SHVU_RR SG_ 1799 GST_RRHVU_Byte1 0;
BA_REL_ "GenSigTimeoutTime" BU_SG_REL_ vHS_M SG_ 1799 GST_RRHVU_Byte1 0;
BA_ "NetworkRequest" SG_ 1799 GST_RRHVU_Byte1 0;
BA_ "NetworkRequestHoldingTime" SG_ 1799 GST_RRHVU_Byte1 5000;
BA_ "Version" SG_ 1799 GST_RRHVU_Byte1 "21.02.04";
BA_ "GenMsgCycleTime" BO_ 1479 0;
BA_ "GenMsgCycleTimeFast" BO_ 1479 0;
BA_ "GenMsgNrOfRepetition" BO_ 1479 0;
BA_ "DiagRequest" BO_ 1479 1;
BA_ "GenMsgILSupport" BO_ 1479 0;
BA_ "TpMessage" BO_ 1479 1;
BA_ "TpTxIndex" BO_ 1479 219;
BA_ "Description" SG_ 1479 GST_RRPSS_Byte0 "TP Index : 219";
BA_ "UsrSigPurpose" SG_ 1479 GST_RRPSS_Byte0 3;
BA_ "UserSigValidity" SG_ 1479 GST_RRPSS_Byte0 0;
BA_REL_ "GenSigTimeoutTime" BU_SG_REL_ RLPSM SG_ 1479 GST_RRPSS_Byte0 0;
BA_REL_ "GenSigTimeoutTime" BU_SG_REL_ vHS_M SG_ 1479 GST_RRPSS_Byte0 0;
BA_ "NetworkRequest" SG_ 1479 GST_RRPSS_Byte0 0;
BA_ "NetworkRequestHoldingTime" SG_ 1479 GST_RRPSS_Byte0 5000;
BA_ "Version" SG_ 1479 GST_RRPSS_Byte0 "21.02.04";
BA_ "Description" SG_ 1479 GST_RRPSS_Byte2 "TP Index : 219";
BA_ "UsrSigPurpose" SG_ 1479 GST_RRPSS_Byte2 3;
BA_ "UserSigValidity" SG_ 1479 GST_RRPSS_Byte2 0;
BA_REL_ "GenSigTimeoutTime" BU_SG_REL_ RLPSM SG_ 1479 GST_RRPSS_Byte2 0;
BA_REL_ "GenSigTimeoutTime" BU_SG_REL_ vHS_M SG_ 1479 GST_RRPSS_Byte2 0;
BA_ "NetworkRequest" SG_ 1479 GST_RRPSS_Byte2 0;
BA_ "NetworkRequestHoldingTime" SG_ 1479 GST_RRPSS_Byte2 5000;
BA_ "Version" SG_ 1479 GST_RRPSS_Byte2 "21.02.04";
BA_ "Description" SG_ 1479 GST_RRPSS_Byte3 "TP Index : 219";
BA_ "UsrSigPurpose" SG_ 1479 GST_RRPSS_Byte3 3;
BA_ "UserSigValidity" SG_ 1479 GST_RRPSS_Byte3 0;
BA_REL_ "GenSigTimeoutTime" BU_SG_REL_ RLPSM SG_ 1479 GST_RRPSS_Byte3 0;
BA_REL_ "GenSigTimeoutTime" BU_SG_REL_ vHS_M SG_ 1479 GST_RRPSS_Byte3 0;
BA_ "NetworkRequest" SG_ 1479 GST_RRPSS_Byte3 0;
BA_ "NetworkRequestHoldingTime" SG_ 1479 GST_RRPSS_Byte3 5000;
BA_ "Version" SG_ 1479 GST_RRPSS_Byte3 "21.02.04";
BA_ "Description" SG_ 1479 GST_RRPSS_Byte4 "TP Index : 219";
BA_ "UsrSigPurpose" SG_ 1479 GST_RRPSS_Byte4 3;
BA_ "UserSigValidity" SG_ 1479 GST_RRPSS_Byte4 0;
BA_REL_ "GenSigTimeoutTime" BU_SG_REL_ RLPSM SG_ 1479 GST_RRPSS_Byte4 0;
BA_REL_ "GenSigTimeoutTime" BU_SG_REL_ vHS_M SG_ 1479 GST_RRPSS_Byte4 0;
BA_ "NetworkRequest" SG_ 1479 GST_RRPSS_Byte4 0;
BA_ "NetworkRequestHoldingTime" SG_ 1479 GST_RRPSS_Byte4 5000;
BA_ "Version" SG_ 1479 GST_RRPSS_Byte4 "21.02.04";
BA_ "Description" SG_ 1479 GST_RRPSS_Byte5 "TP Index : 219";
BA_ "UsrSigPurpose" SG_ 1479 GST_RRPSS_Byte5 3;
BA_ "UserSigValidity" SG_ 1479 GST_RRPSS_Byte5 0;
BA_REL_ "GenSigTimeoutTime" BU_SG_REL_ RLPSM SG_ 1479 GST_RRPSS_Byte5 0;
BA_REL_ "GenSigTimeoutTime" BU_SG_REL_ vHS_M SG_ 1479 GST_RRPSS_Byte5 0;
BA_ "NetworkRequest" SG_ 1479 GST_RRPSS_Byte5 0;
BA_ "NetworkRequestHoldingTime" SG_ 1479 GST_RRPSS_Byte5 5000;
BA_ "Version" SG_ 1479 GST_RRPSS_Byte5 "21.02.04";
BA_ "Description" SG_ 1479 GST_RRPSS_Byte6 "TP Index : 219";
BA_ "UsrSigPurpose" SG_ 1479 GST_RRPSS_Byte6 3;
BA_ "UserSigValidity" SG_ 1479 GST_RRPSS_Byte6 0;
BA_REL_ "GenSigTimeoutTime" BU_SG_REL_ RLPSM SG_ 1479 GST_RRPSS_Byte6 0;
BA_REL_ "GenSigTimeoutTime" BU_SG_REL_ vHS_M SG_ 1479 GST_RRPSS_Byte6 0;
BA_ "NetworkRequest" SG_ 1479 GST_RRPSS_Byte6 0;
BA_ "NetworkRequestHoldingTime" SG_ 1479 GST_RRPSS_Byte6 5000;
BA_ "Version" SG_ 1479 GST_RRPSS_Byte6 "21.02.04";
BA_ "Description" SG_ 1479 GST_RRPSS_Byte7 "TP Index : 219";
BA_ "UsrSigPurpose" SG_ 1479 GST_RRPSS_Byte7 3;
BA_ "UserSigValidity" SG_ 1479 GST_RRPSS_Byte7 0;
BA_REL_ "GenSigTimeoutTime" BU_SG_REL_ RLPSM SG_ 1479 GST_RRPSS_Byte7 0;
BA_REL_ "GenSigTimeoutTime" BU_SG_REL_ vHS_M SG_ 1479 GST_RRPSS_Byte7 0;
BA_ "NetworkRequest" SG_ 1479 GST_RRPSS_Byte7 0;
BA_ "NetworkRequestHoldingTime" SG_ 1479 GST_RRPSS_Byte7 5000;
BA_ "Version" SG_ 1479 GST_RRPSS_Byte7 "21.02.04";
BA_ "Description" SG_ 1479 GST_RRPSS_Byte1 "TP Index : 219";
BA_ "UsrSigPurpose" SG_ 1479 GST_RRPSS_Byte1 3;
BA_ "UserSigValidity" SG_ 1479 GST_RRPSS_Byte1 0;
BA_REL_ "GenSigTimeoutTime" BU_SG_REL_ RLPSM SG_ 1479 GST_RRPSS_Byte1 0;
BA_REL_ "GenSigTimeoutTime" BU_SG_REL_ vHS_M SG_ 1479 GST_RRPSS_Byte1 0;
BA_ "NetworkRequest" SG_ 1479 GST_RRPSS_Byte1 0;
BA_ "NetworkRequestHoldingTime" SG_ 1479 GST_RRPSS_Byte1 5000;
BA_ "Version" SG_ 1479 GST_RRPSS_Byte1 "21.02.04";
BA_ "GenMsgSendType" BO_ 2319620609 0;
BA_ "GenMsgCycleTime" BO_ 2319620609 100;
BA_ "VFrameFormat" BO_ 2319620609 1;
BA_ "Description" SG_ 2319620609 HUD_PbackSta "Status signal for HUD interoperation with IMS

(The number of memory is expanded.)";
BA_ "GenSigSendType" SG_ 2319620609 HUD_PbackSta 4;
BA_ "UserSigValidity" SG_ 2319620609 HUD_PbackSta 3;
BA_REL_ "GenSigTimeoutTime" BU_SG_REL_ PSM SG_ 2319620609 HUD_PbackSta 1500;
BA_ "Version" SG_ 2319620609 HUD_PbackSta "19.07.02";
BA_ "GenMsgCycleTime" BO_ 2563126273 0;
BA_ "VFrameFormat" BO_ 2563126273 1;
BA_ "GenSigSendType" SG_ 2563126273 AMP_NaviVolumeStep 4;
BA_ "GenSigStartValue" SG_ 2563126273 AMP_NaviVolumeStep 255;
BA_ "UserSigValidity" SG_ 2563126273 AMP_NaviVolumeStep 1;
BA_REL_ "GenSigTimeoutTime" BU_SG_REL_ AMP SG_ 2563126273 AMP_NaviVolumeStep 0;
BA_ "NetworkRequest" SG_ 2563126273 AMP_NaviVolumeStep 0;
BA_ "Version" SG_ 2563126273 AMP_NaviVolumeStep "18.12.06";
BA_ "Description" SG_ 2563126273 ATS_BeepVolumeStep "Command for ATS Touch Beep Sound Volume Setting 

-range : 0 ~ max

-max : value of AMP_MaxBeep1VolumeState

-This Signal's Feedback is ATS_BeepVolumeState@AMP";
BA_ "GenSigSendType" SG_ 2563126273 ATS_BeepVolumeStep 4;
BA_ "GenSigStartValue" SG_ 2563126273 ATS_BeepVolumeStep 255;
BA_ "UserSigValidity" SG_ 2563126273 ATS_BeepVolumeStep 1;
BA_REL_ "GenSigTimeoutTime" BU_SG_REL_ AMP SG_ 2563126273 ATS_BeepVolumeStep 0;
BA_ "Version" SG_ 2563126273 ATS_BeepVolumeStep "20.03.03";
BA_ "Description" SG_ 2563126273 ATS_BeepFrequency "Command for Touch Beep Sound Frequency Setting of ATS

-range : 20Hz ~ 20000Hz";
BA_ "GenSigSendType" SG_ 2563126273 ATS_BeepFrequency 4;
BA_ "GenSigStartValue" SG_ 2563126273 ATS_BeepFrequency 65535;
BA_ "UserSigValidity" SG_ 2563126273 ATS_BeepFrequency 1;
BA_REL_ "GenSigTimeoutTime" BU_SG_REL_ AMP SG_ 2563126273 ATS_BeepFrequency 0;
BA_ "Version" SG_ 2563126273 ATS_BeepFrequency "20.03.03";
BA_ "GenSigSendType" SG_ 2563126273 AMP_ESEVMasterGain 4;
BA_ "GenSigStartValue" SG_ 2563126273 AMP_ESEVMasterGain 31;
BA_ "UserSigValidity" SG_ 2563126273 AMP_ESEVMasterGain 1;
BA_REL_ "GenSigTimeoutTime" BU_SG_REL_ AMP SG_ 2563126273 AMP_ESEVMasterGain 0;
BA_ "NetworkRequest" SG_ 2563126273 AMP_ESEVMasterGain 0;
BA_ "Version" SG_ 2563126273 AMP_ESEVMasterGain "20.03.06";
BA_ "Description" SG_ 2563126273 AMP_NaviVoice_Priority "Navi voice priority ON/OFF";
BA_ "GenSigSendType" SG_ 2563126273 AMP_NaviVoice_Priority 4;
BA_ "GenSigStartValue" SG_ 2563126273 AMP_NaviVoice_Priority 3;
BA_ "UserSigValidity" SG_ 2563126273 AMP_NaviVoice_Priority 1;
BA_REL_ "GenSigTimeoutTime" BU_SG_REL_ AMP SG_ 2563126273 AMP_NaviVoice_Priority 0;
BA_ "Version" SG_ 2563126273 AMP_NaviVoice_Priority "19.01.05";
BA_ "GenSigSendType" SG_ 2563126273 AMP_ESEVMode 4;
BA_ "GenSigStartValue" SG_ 2563126273 AMP_ESEVMode 7;
BA_ "UserSigValidity" SG_ 2563126273 AMP_ESEVMode 1;
BA_REL_ "GenSigTimeoutTime" BU_SG_REL_ AMP SG_ 2563126273 AMP_ESEVMode 0;
BA_ "NetworkRequest" SG_ 2563126273 AMP_ESEVMode 0;
BA_ "Version" SG_ 2563126273 AMP_ESEVMode "20.07.08";
BA_ "Description" SG_ 2563126273 ATS_Beep_OutputCh_Select "Command for Set ATS Beep Output Channel to identify which Speakers will output Sound

- per bit, 0 means 'Not Output Channel' and 1 means 'Output Channel'

bit0 : FL / bit1 : FR / bit2 : RL / bit3 : RR / bit4 : CTR / bit5 : Surround L /

bit6 : Surround R / bit7 : SWF / bit8 : Headrest L / bit9 : Headrest R / bit10 : Loof L /

bit11 : Loof CTR / bit12 : Loof R / bit13~bit15 : Reserved

- This Signal's Feedback is ATS_Beep_OutputCh_State@AMP";
BA_ "GenSigSendType" SG_ 2563126273 ATS_Beep_OutputCh_Select 4;
BA_ "GenSigStartValue" SG_ 2563126273 ATS_Beep_OutputCh_Select 65535;
BA_ "UserSigValidity" SG_ 2563126273 ATS_Beep_OutputCh_Select 1;
BA_REL_ "GenSigTimeoutTime" BU_SG_REL_ AMP SG_ 2563126273 ATS_Beep_OutputCh_Select 0;
BA_ "Version" SG_ 2563126273 ATS_Beep_OutputCh_Select "20.03.03";
BA_ "GenMsgCycleTime" BO_ 2563127809 0;
BA_ "VFrameFormat" BO_ 2563127809 1;
BA_ "GenSigSendType" SG_ 2563127809 AMP_PESSAPSSet 4;
BA_ "GenSigStartValue" SG_ 2563127809 AMP_PESSAPSSet 7;
BA_ "UserSigValidity" SG_ 2563127809 AMP_PESSAPSSet 1;
BA_ "NetworkRequest" SG_ 2563127809 AMP_PESSAPSSet 0;
BA_ "Version" SG_ 2563127809 AMP_PESSAPSSet "19.03.01";
BA_ "Description" SG_ 2563127809 AMP_PESSDesignSet_New "19.01.07_[Default Value]

0x0";
BA_ "GenSigSendType" SG_ 2563127809 AMP_PESSDesignSet_New 4;
BA_ "GenSigStartValue" SG_ 2563127809 AMP_PESSDesignSet_New 15;
BA_ "UserSigValidity" SG_ 2563127809 AMP_PESSDesignSet_New 1;
BA_ "NetworkRequest" SG_ 2563127809 AMP_PESSDesignSet_New 0;
BA_ "Version" SG_ 2563127809 AMP_PESSDesignSet_New "19.03.08";
BA_ "GenSigSendType" SG_ 2563127809 AMP_PESSCANSet 4;
BA_ "GenSigStartValue" SG_ 2563127809 AMP_PESSCANSet 7;
BA_ "UserSigValidity" SG_ 2563127809 AMP_PESSCANSet 1;
BA_ "NetworkRequest" SG_ 2563127809 AMP_PESSCANSet 0;
BA_ "Version" SG_ 2563127809 AMP_PESSCANSet "19.03.01";
BA_ "Description" SG_ 2563127809 AMP_WalkieTalkieMode "The signal is the Walkie Talkie On/Off from HU to AMP";
BA_ "GenSigSendType" SG_ 2563127809 AMP_WalkieTalkieMode 4;
BA_ "GenSigStartValue" SG_ 2563127809 AMP_WalkieTalkieMode 3;
BA_ "UserSigValidity" SG_ 2563127809 AMP_WalkieTalkieMode 1;
BA_REL_ "GenSigTimeoutTime" BU_SG_REL_ AMP SG_ 2563127809 AMP_WalkieTalkieMode 0;
BA_ "Version" SG_ 2563127809 AMP_WalkieTalkieMode "21.07.04";
BA_ "Description" SG_ 2563127809 AMP_WalkieTalkieVolumeStep "Command for WalkieTalkie Mode Volume Setting";
BA_ "GenSigSendType" SG_ 2563127809 AMP_WalkieTalkieVolumeStep 4;
BA_ "GenSigStartValue" SG_ 2563127809 AMP_WalkieTalkieVolumeStep 255;
BA_ "UserSigValidity" SG_ 2563127809 AMP_WalkieTalkieVolumeStep 1;
BA_REL_ "GenSigTimeoutTime" BU_SG_REL_ AMP SG_ 2563127809 AMP_WalkieTalkieVolumeStep 0;
BA_ "Version" SG_ 2563127809 AMP_WalkieTalkieVolumeStep "21.07.04";
BA_ "Description" SG_ 2563127809 AMP_WalkieTalkie_OutputCh_Sel "Command for Set WalkieTalkie Output Channel to identify which Speakers will output Sound

- per bit, 0 means 'Not Output Channel' and 1 means 'Output Channel'

bit0 : FL / bit1 : FR / bit2 : RL / bit3 : RR / bit4 : CTR / bit5 : Surround L /

bit6 : Surround R / bit7 : SWF / bit8 : Headrest L / bit9 : Headrest R / bit10 : Loof L /

bit11 : Loof CTR / bit12 : Loof R / bit13~bit15 : Reserved

- This Signal's Feedback is AMP_WalkieTalkie_OutputCh_State@AMP";
BA_ "GenSigSendType" SG_ 2563127809 AMP_WalkieTalkie_OutputCh_Sel 4;
BA_ "UserSigValidity" SG_ 2563127809 AMP_WalkieTalkie_OutputCh_Sel 1;
BA_REL_ "GenSigTimeoutTime" BU_SG_REL_ AMP SG_ 2563127809 AMP_WalkieTalkie_OutputCh_Sel 0;
BA_ "Version" SG_ 2563127809 AMP_WalkieTalkie_OutputCh_Sel "21.07.04";
BA_ "GenSigSendType" SG_ 2563127809 AMP_PESSMode 4;
BA_ "GenSigStartValue" SG_ 2563127809 AMP_PESSMode 3;
BA_ "UserSigValidity" SG_ 2563127809 AMP_PESSMode 1;
BA_ "NetworkRequest" SG_ 2563127809 AMP_PESSMode 0;
BA_ "Version" SG_ 2563127809 AMP_PESSMode "18.12.06";
BA_ "GenSigSendType" SG_ 2563127809 AMP_PESSVolumeSet 4;
BA_ "GenSigStartValue" SG_ 2563127809 AMP_PESSVolumeSet 255;
BA_ "UserSigValidity" SG_ 2563127809 AMP_PESSVolumeSet 1;
BA_ "NetworkRequest" SG_ 2563127809 AMP_PESSVolumeSet 0;
BA_ "Version" SG_ 2563127809 AMP_PESSVolumeSet "18.12.06";
BA_ "GenMsgSendType" BO_ 2298626305 0;
BA_ "VFrameFormat" BO_ 2298626305 1;
BA_ "GenSigSendType" SG_ 2298626305 C_AstBolsterInfSw_HU 4;
BA_ "UserSigValidity" SG_ 2298626305 C_AstBolsterInfSw_HU 0;
BA_REL_ "GenSigTimeoutTime" BU_SG_REL_ APSS SG_ 2298626305 C_AstBolsterInfSw_HU 1500;
BA_REL_ "GenSigTimeoutTime" BU_SG_REL_ ASAU SG_ 2298626305 C_AstBolsterInfSw_HU 1500;
BA_ "Version" SG_ 2298626305 C_AstBolsterInfSw_HU "19.11.09";
BA_ "GenSigSendType" SG_ 2298626305 C_RLHrestUpSw_HU 4;
BA_ "UserSigValidity" SG_ 2298626305 C_RLHrestUpSw_HU 0;
BA_REL_ "GenSigTimeoutTime" BU_SG_REL_ RLPSM SG_ 2298626305 C_RLHrestUpSw_HU 1500;
BA_ "Version" SG_ 2298626305 C_RLHrestUpSw_HU "19.11.09";
BA_ "GenSigSendType" SG_ 2298626305 C_RLHrestDnSw_HU 4;
BA_ "UserSigValidity" SG_ 2298626305 C_RLHrestDnSw_HU 0;
BA_REL_ "GenSigTimeoutTime" BU_SG_REL_ RLPSM SG_ 2298626305 C_RLHrestDnSw_HU 1500;
BA_ "Version" SG_ 2298626305 C_RLHrestDnSw_HU "19.11.09";
BA_ "GenSigSendType" SG_ 2298626305 C_RLHrestFwdSw_HU 4;
BA_ "UserSigValidity" SG_ 2298626305 C_RLHrestFwdSw_HU 0;
BA_REL_ "GenSigTimeoutTime" BU_SG_REL_ RLPSM SG_ 2298626305 C_RLHrestFwdSw_HU 1500;
BA_ "Version" SG_ 2298626305 C_RLHrestFwdSw_HU "19.11.09";
BA_ "GenSigSendType" SG_ 2298626305 C_AstBolsterDefSw_HU 4;
BA_ "UserSigValidity" SG_ 2298626305 C_AstBolsterDefSw_HU 0;
BA_REL_ "GenSigTimeoutTime" BU_SG_REL_ APSS SG_ 2298626305 C_AstBolsterDefSw_HU 1500;
BA_REL_ "GenSigTimeoutTime" BU_SG_REL_ ASAU SG_ 2298626305 C_AstBolsterDefSw_HU 1500;
BA_ "Version" SG_ 2298626305 C_AstBolsterDefSw_HU "19.11.09";
BA_ "GenSigSendType" SG_ 2298626305 C_RLHrestBwdSw_HU 4;
BA_ "UserSigValidity" SG_ 2298626305 C_RLHrestBwdSw_HU 0;
BA_REL_ "GenSigTimeoutTime" BU_SG_REL_ RLPSM SG_ 2298626305 C_RLHrestBwdSw_HU 1500;
BA_ "Version" SG_ 2298626305 C_RLHrestBwdSw_HU "19.11.09";
BA_ "GenSigSendType" SG_ 2298626305 C_RLLumbarUpSw_HU 4;
BA_ "UserSigValidity" SG_ 2298626305 C_RLLumbarUpSw_HU 0;
BA_REL_ "GenSigTimeoutTime" BU_SG_REL_ RLPSM SG_ 2298626305 C_RLLumbarUpSw_HU 1500;
BA_ "Version" SG_ 2298626305 C_RLLumbarUpSw_HU "19.11.09";
BA_ "GenSigSendType" SG_ 2298626305 C_RLLumbarMidSw_HU 4;
BA_ "UserSigValidity" SG_ 2298626305 C_RLLumbarMidSw_HU 0;
BA_REL_ "GenSigTimeoutTime" BU_SG_REL_ RLPSM SG_ 2298626305 C_RLLumbarMidSw_HU 1500;
BA_ "Version" SG_ 2298626305 C_RLLumbarMidSw_HU "19.11.09";
BA_ "GenSigSendType" SG_ 2298626305 C_RLLumbarLowSw_HU 4;
BA_ "UserSigValidity" SG_ 2298626305 C_RLLumbarLowSw_HU 0;
BA_REL_ "GenSigTimeoutTime" BU_SG_REL_ RLPSM SG_ 2298626305 C_RLLumbarLowSw_HU 1500;
BA_ "Version" SG_ 2298626305 C_RLLumbarLowSw_HU "19.11.09";
BA_ "GenSigSendType" SG_ 2298626305 C_RLLumbarDefSw_HU 4;
BA_ "UserSigValidity" SG_ 2298626305 C_RLLumbarDefSw_HU 0;
BA_REL_ "GenSigTimeoutTime" BU_SG_REL_ RLPSM SG_ 2298626305 C_RLLumbarDefSw_HU 1500;
BA_ "Version" SG_ 2298626305 C_RLLumbarDefSw_HU "19.11.09";
BA_ "GenSigSendType" SG_ 2298626305 C_RLBolsterInfSw_HU 4;
BA_ "UserSigValidity" SG_ 2298626305 C_RLBolsterInfSw_HU 0;
BA_REL_ "GenSigTimeoutTime" BU_SG_REL_ RLPSM SG_ 2298626305 C_RLBolsterInfSw_HU 1500;
BA_ "Version" SG_ 2298626305 C_RLBolsterInfSw_HU "19.11.09";
BA_ "GenSigSendType" SG_ 2298626305 C_RLBolsterDefSw_HU 4;
BA_ "UserSigValidity" SG_ 2298626305 C_RLBolsterDefSw_HU 0;
BA_REL_ "GenSigTimeoutTime" BU_SG_REL_ RLPSM SG_ 2298626305 C_RLBolsterDefSw_HU 1500;
BA_ "Version" SG_ 2298626305 C_RLBolsterDefSw_HU "19.11.09";
BA_ "GenSigSendType" SG_ 2298626305 C_AstHrestUpSw_HU 4;
BA_ "UserSigValidity" SG_ 2298626305 C_AstHrestUpSw_HU 0;
BA_REL_ "GenSigTimeoutTime" BU_SG_REL_ APSM SG_ 2298626305 C_AstHrestUpSw_HU 1500;
BA_REL_ "GenSigTimeoutTime" BU_SG_REL_ APSS SG_ 2298626305 C_AstHrestUpSw_HU 1500;
BA_ "Version" SG_ 2298626305 C_AstHrestUpSw_HU "19.11.09";
BA_ "GenSigSendType" SG_ 2298626305 C_AstHrestDnSw_HU 4;
BA_ "UserSigValidity" SG_ 2298626305 C_AstHrestDnSw_HU 0;
BA_REL_ "GenSigTimeoutTime" BU_SG_REL_ APSM SG_ 2298626305 C_AstHrestDnSw_HU 1500;
BA_REL_ "GenSigTimeoutTime" BU_SG_REL_ APSS SG_ 2298626305 C_AstHrestDnSw_HU 1500;
BA_ "Version" SG_ 2298626305 C_AstHrestDnSw_HU "19.11.09";
BA_ "GenSigSendType" SG_ 2298626305 C_AstFootrestFldSw_HU 4;
BA_ "UserSigValidity" SG_ 2298626305 C_AstFootrestFldSw_HU 0;
BA_REL_ "GenSigTimeoutTime" BU_SG_REL_ APSM SG_ 2298626305 C_AstFootrestFldSw_HU 1500;
BA_REL_ "GenSigTimeoutTime" BU_SG_REL_ APSS SG_ 2298626305 C_AstFootrestFldSw_HU 1500;
BA_ "Version" SG_ 2298626305 C_AstFootrestFldSw_HU "19.11.09";
BA_ "GenSigSendType" SG_ 2298626305 C_AstHrestFwdSw_HU 4;
BA_ "UserSigValidity" SG_ 2298626305 C_AstHrestFwdSw_HU 0;
BA_REL_ "GenSigTimeoutTime" BU_SG_REL_ APSM SG_ 2298626305 C_AstHrestFwdSw_HU 1500;
BA_REL_ "GenSigTimeoutTime" BU_SG_REL_ APSS SG_ 2298626305 C_AstHrestFwdSw_HU 1500;
BA_ "Version" SG_ 2298626305 C_AstHrestFwdSw_HU "19.11.09";
BA_ "GenSigSendType" SG_ 2298626305 C_AstHrestBwdSw_HU 4;
BA_ "UserSigValidity" SG_ 2298626305 C_AstHrestBwdSw_HU 0;
BA_REL_ "GenSigTimeoutTime" BU_SG_REL_ APSM SG_ 2298626305 C_AstHrestBwdSw_HU 1500;
BA_REL_ "GenSigTimeoutTime" BU_SG_REL_ APSS SG_ 2298626305 C_AstHrestBwdSw_HU 1500;
BA_ "Version" SG_ 2298626305 C_AstHrestBwdSw_HU "19.11.09";
BA_ "GenSigSendType" SG_ 2298626305 C_AstFootrestUnFldSw_HU 4;
BA_ "UserSigValidity" SG_ 2298626305 C_AstFootrestUnFldSw_HU 0;
BA_REL_ "GenSigTimeoutTime" BU_SG_REL_ APSM SG_ 2298626305 C_AstFootrestUnFldSw_HU 1500;
BA_REL_ "GenSigTimeoutTime" BU_SG_REL_ APSS SG_ 2298626305 C_AstFootrestUnFldSw_HU 1500;
BA_ "Version" SG_ 2298626305 C_AstFootrestUnFldSw_HU "19.11.09";
BA_ "GenMsgCycleTime" BO_ 2458165505 0;
BA_ "VFrameFormat" BO_ 2458165505 1;
BA_ "GenSigSendType" SG_ 2458165505 C_AstWindowCmdAVN 4;
BA_ "GenSigStartValue" SG_ 2458165505 C_AstWindowCmdAVN 15;
BA_ "UserSigValidity" SG_ 2458165505 C_AstWindowCmdAVN 0;
BA_ "Version" SG_ 2458165505 C_AstWindowCmdAVN "19.11.05";
BA_ "GenSigSendType" SG_ 2458165505 C_TrunkTlgtCmdAVN 4;
BA_ "GenSigStartValue" SG_ 2458165505 C_TrunkTlgtCmdAVN 3;
BA_ "UserSigValidity" SG_ 2458165505 C_TrunkTlgtCmdAVN 3;
BA_ "Version" SG_ 2458165505 C_TrunkTlgtCmdAVN "18.09.02";
BA_ "GenSigSendType" SG_ 2458165505 C_StrgWhlHeatedCmdAVN 4;
BA_ "GenSigStartValue" SG_ 2458165505 C_StrgWhlHeatedCmdAVN 3;
BA_ "UserSigValidity" SG_ 2458165505 C_StrgWhlHeatedCmdAVN 4;
BA_ "Version" SG_ 2458165505 C_StrgWhlHeatedCmdAVN "19.05.05";
BA_ "GenSigSendType" SG_ 2458165505 C_RrDefoggerCmdAVN 4;
BA_ "GenSigStartValue" SG_ 2458165505 C_RrDefoggerCmdAVN 3;
BA_ "UserSigValidity" SG_ 2458165505 C_RrDefoggerCmdAVN 3;
BA_ "Version" SG_ 2458165505 C_RrDefoggerCmdAVN "18.09.02";
BA_ "GenSigSendType" SG_ 2458165505 C_RRWindowCmdAVN 4;
BA_ "GenSigStartValue" SG_ 2458165505 C_RRWindowCmdAVN 15;
BA_ "UserSigValidity" SG_ 2458165505 C_RRWindowCmdAVN 0;
BA_REL_ "GenSigTimeoutTime" BU_SG_REL_ RDC SG_ 2458165505 C_RRWindowCmdAVN 0;
BA_ "Version" SG_ 2458165505 C_RRWindowCmdAVN "19.11.05";
BA_ "GenSigSendType" SG_ 2458165505 C_RLWindowCmdAVN 4;
BA_ "GenSigStartValue" SG_ 2458165505 C_RLWindowCmdAVN 15;
BA_ "UserSigValidity" SG_ 2458165505 C_RLWindowCmdAVN 0;
BA_REL_ "GenSigTimeoutTime" BU_SG_REL_ RDC SG_ 2458165505 C_RLWindowCmdAVN 0;
BA_ "Version" SG_ 2458165505 C_RLWindowCmdAVN "19.11.05";
BA_ "GenSigSendType" SG_ 2458165505 C_BlindCmdAVN 4;
BA_ "GenSigStartValue" SG_ 2458165505 C_BlindCmdAVN 7;
BA_ "UserSigValidity" SG_ 2458165505 C_BlindCmdAVN 1;
BA_ "Version" SG_ 2458165505 C_BlindCmdAVN "18.09.02";
BA_ "GenSigSendType" SG_ 2458165505 C_GlassCmdAVN 4;
BA_ "GenSigStartValue" SG_ 2458165505 C_GlassCmdAVN 7;
BA_ "UserSigValidity" SG_ 2458165505 C_GlassCmdAVN 1;
BA_ "Version" SG_ 2458165505 C_GlassCmdAVN "18.09.02";
BA_ "GenSigSendType" SG_ 2458165505 C_DrvWindowCmdAVN 4;
BA_ "GenSigStartValue" SG_ 2458165505 C_DrvWindowCmdAVN 15;
BA_ "UserSigValidity" SG_ 2458165505 C_DrvWindowCmdAVN 0;
BA_ "Version" SG_ 2458165505 C_DrvWindowCmdAVN "19.11.05";
BA_ "GenSigSendType" SG_ 2458165505 C_ThemeCmdAVN 4;
BA_ "GenSigStartValue" SG_ 2458165505 C_ThemeCmdAVN 7;
BA_ "UserSigValidity" SG_ 2458165505 C_ThemeCmdAVN 1;
BA_ "Version" SG_ 2458165505 C_ThemeCmdAVN "18.09.02";
BA_ "GenSigSendType" SG_ 2458165505 C_CluDispCmdAVN 4;
BA_ "GenSigStartValue" SG_ 2458165505 C_CluDispCmdAVN 7;
BA_ "UserSigValidity" SG_ 2458165505 C_CluDispCmdAVN 3;
BA_ "Version" SG_ 2458165505 C_CluDispCmdAVN "18.06.04";
BA_ "GenSigSendType" SG_ 2458165505 HU_FRSeatHeatVRcmd 4;
BA_ "UserSigValidity" SG_ 2458165505 HU_FRSeatHeatVRcmd 3;
BA_REL_ "GenSigTimeoutTime" BU_SG_REL_ SHVU_RR SG_ 2458165505 HU_FRSeatHeatVRcmd 0;
BA_REL_ "GenSigTimeoutTime" BU_SG_REL_ DPSS SG_ 2458165505 HU_FRSeatHeatVRcmd 0;
BA_REL_ "GenSigTimeoutTime" BU_SG_REL_ ATS SG_ 2458165505 HU_FRSeatHeatVRcmd 0;
BA_ "Version" SG_ 2458165505 HU_FRSeatHeatVRcmd "18.09.02";
BA_ "GenSigSendType" SG_ 2458165505 HU_FLSeatHeatVRcmd 4;
BA_ "UserSigValidity" SG_ 2458165505 HU_FLSeatHeatVRcmd 3;
BA_REL_ "GenSigTimeoutTime" BU_SG_REL_ DPSS SG_ 2458165505 HU_FLSeatHeatVRcmd 0;
BA_REL_ "GenSigTimeoutTime" BU_SG_REL_ ATS SG_ 2458165505 HU_FLSeatHeatVRcmd 0;
BA_ "Version" SG_ 2458165505 HU_FLSeatHeatVRcmd "18.09.02";
BA_ "GenSigSendType" SG_ 2458165505 C_PTGCNTLCmdAVN 4;
BA_ "GenSigStartValue" SG_ 2458165505 C_PTGCNTLCmdAVN 3;
BA_ "UserSigValidity" SG_ 2458165505 C_PTGCNTLCmdAVN 3;
BA_ "Version" SG_ 2458165505 C_PTGCNTLCmdAVN "18.09.02";
BA_ "GenMsgSendType" BO_ 2479158017 0;
BA_ "GenMsgCycleTime" BO_ 2479158017 1000;
BA_ "VFrameFormat" BO_ 2479158017 1;
BA_ "GenSigSendType" SG_ 2479158017 RSELockOnOff 4;
BA_ "GenSigStartValue" SG_ 2479158017 RSELockOnOff 3;
BA_ "UserSigValidity" SG_ 2479158017 RSELockOnOff 1;
BA_REL_ "GenSigTimeoutTime" BU_SG_REL_ ATS SG_ 2479158017 RSELockOnOff 5000;
BA_ "NetworkRequest" SG_ 2479158017 RSELockOnOff 0;
BA_ "NetworkRequestHoldingTime" SG_ 2479158017 RSELockOnOff 5000;
BA_ "Version" SG_ 2479158017 RSELockOnOff "19.11.11";
BA_ "Description" SG_ 2479158017 HU_DATC_DisplayThemes "HU Display Theme (Black/White)";
BA_ "GenSigSendType" SG_ 2479158017 HU_DATC_DisplayThemes 4;
BA_ "GenSigStartValue" SG_ 2479158017 HU_DATC_DisplayThemes 3;
BA_ "UserSigValidity" SG_ 2479158017 HU_DATC_DisplayThemes 1;
BA_ "Version" SG_ 2479158017 HU_DATC_DisplayThemes "20.01.02";
BA_ "GenSigSendType" SG_ 2479158017 HU_DATC_RearLockSet 4;
BA_ "GenSigStartValue" SG_ 2479158017 HU_DATC_RearLockSet 3;
BA_ "UserSigValidity" SG_ 2479158017 HU_DATC_RearLockSet 3;
BA_ "Version" SG_ 2479158017 HU_DATC_RearLockSet "18.09.04";
BA_ "GenSigSendType" SG_ 2479158017 HU_PhoneActivity 4;
BA_ "GenSigStartValue" SG_ 2479158017 HU_PhoneActivity 3;
BA_ "UserSigValidity" SG_ 2479158017 HU_PhoneActivity 1;
BA_ "NetworkRequest" SG_ 2479158017 HU_PhoneActivity 0;
BA_ "Version" SG_ 2479158017 HU_PhoneActivity "19.02.08";
BA_ "GenSigSendType" SG_ 2479158017 HU_VRActivity 4;
BA_ "GenSigStartValue" SG_ 2479158017 HU_VRActivity 3;
BA_ "UserSigValidity" SG_ 2479158017 HU_VRActivity 1;
BA_ "NetworkRequest" SG_ 2479158017 HU_VRActivity 0;
BA_ "Version" SG_ 2479158017 HU_VRActivity "19.02.08";
BA_ "GenMsgCycleTime" BO_ 2315420417 0;
BA_ "VFrameFormat" BO_ 2315420417 1;
BA_ "Description" SG_ 2315420417 AVN_Encrypted_Result3 "This signal is for a send encrypted result of AVN";
BA_ "GenSigSendType" SG_ 2315420417 AVN_Encrypted_Result3 4;
BA_ "UserSigValidity" SG_ 2315420417 AVN_Encrypted_Result3 0;
BA_REL_ "GenSigTimeoutTime" BU_SG_REL_ FPM SG_ 2315420417 AVN_Encrypted_Result3 0;
BA_ "Version" SG_ 2315420417 AVN_Encrypted_Result3 "21.07.05";
BA_ "GenMsgCycleTime" BO_ 2336415489 0;
BA_ "VFrameFormat" BO_ 2336415489 1;
BA_ "Description" SG_ 2336415489 CF_AVN_FpLpRedNValueSet "Request For FPM Lamp Color (RED)";
BA_ "GenSigSendType" SG_ 2336415489 CF_AVN_FpLpRedNValueSet 4;
BA_ "GenSigStartValue" SG_ 2336415489 CF_AVN_FpLpRedNValueSet 256;
BA_ "UserSigValidity" SG_ 2336415489 CF_AVN_FpLpRedNValueSet 0;
BA_REL_ "GenSigTimeoutTime" BU_SG_REL_ FPM SG_ 2336415489 CF_AVN_FpLpRedNValueSet 0;
BA_ "Version" SG_ 2336415489 CF_AVN_FpLpRedNValueSet "21.07.05";
BA_ "Description" SG_ 2336415489 CF_AVN_FpLpBlueNValueSet "Request For FPM Lamp Color (BLUE)";
BA_ "GenSigSendType" SG_ 2336415489 CF_AVN_FpLpBlueNValueSet 4;
BA_ "GenSigStartValue" SG_ 2336415489 CF_AVN_FpLpBlueNValueSet 256;
BA_ "UserSigValidity" SG_ 2336415489 CF_AVN_FpLpBlueNValueSet 0;
BA_REL_ "GenSigTimeoutTime" BU_SG_REL_ FPM SG_ 2336415489 CF_AVN_FpLpBlueNValueSet 0;
BA_ "Version" SG_ 2336415489 CF_AVN_FpLpBlueNValueSet "21.07.05";
BA_ "Description" SG_ 2336415489 CF_AVN_FpLpCtrlNvalueSet "Request FPM Lamp Pattern Control (On/Off/Dimming/Blink)";
BA_ "GenSigSendType" SG_ 2336415489 CF_AVN_FpLpCtrlNvalueSet 4;
BA_ "UserSigValidity" SG_ 2336415489 CF_AVN_FpLpCtrlNvalueSet 0;
BA_REL_ "GenSigTimeoutTime" BU_SG_REL_ FPM SG_ 2336415489 CF_AVN_FpLpCtrlNvalueSet 0;
BA_ "Version" SG_ 2336415489 CF_AVN_FpLpCtrlNvalueSet "21.07.05";
BA_ "Description" SG_ 2336415489 CF_AVN_FpLpGreenNValueSet "Request For FPM Lamp Color (GREEN)";
BA_ "GenSigSendType" SG_ 2336415489 CF_AVN_FpLpGreenNValueSet 4;
BA_ "GenSigStartValue" SG_ 2336415489 CF_AVN_FpLpGreenNValueSet 256;
BA_ "UserSigValidity" SG_ 2336415489 CF_AVN_FpLpGreenNValueSet 0;
BA_REL_ "GenSigTimeoutTime" BU_SG_REL_ FPM SG_ 2336415489 CF_AVN_FpLpGreenNValueSet 0;
BA_ "Version" SG_ 2336415489 CF_AVN_FpLpGreenNValueSet "21.07.05";
BA_ "GenMsgSendType" BO_ 939 0;
BA_ "GenMsgCycleTimeFast" BO_ 939 0;
BA_ "GenMsgNrOfRepetition" BO_ 939 0;
BA_ "Description" SG_ 939 PSB_Crc1Val "The data area for CRC calculation is based on the data length (DLC) of the message DB.

The CRC shall be calculated over the entire data block (excluding the CRC bytes) including the user data, alive counter and Data ID 

 

- CRC Polynomial (0x1D) , Initial Value : 0x00, XOR value : 0xFF, Data ID Mode : Both, Data ID : Message ID + 0xF800 

- The initial value is for CRC calculation and the message should be sent with the calculated result value. 

The mathematical expression to 8 bit CRC polynomial is given here. G(x) = x8 + x4 + x3 + x2 + 1";
BA_ "UserSigValidity" SG_ 939 PSB_Crc1Val 0;
BA_ "Version" SG_ 939 PSB_Crc1Val "18.11.08";
BA_ "Description" SG_ 939 PSB_AlvCnt1Val "For the first transmission request for a data element the counter shall be initialized with 0 and shall be incremented by 1

for every subsequent send request. When the counter reaches the maximum value(0xE), then it shall restart with 0 for the next send request";
BA_ "UserSigValidity" SG_ 939 PSB_AlvCnt1Val 0;
BA_ "Version" SG_ 939 PSB_AlvCnt1Val "18.11.08";
BA_ "Description" SG_ 939 PSB_LHFlrSta "Information about availability of PSB_LH (LH Pre-Safe S/Belt).";
BA_ "UserSigValidity" SG_ 939 PSB_LHFlrSta 0;
BA_ "Version" SG_ 939 PSB_LHFlrSta "18.02.03";
BA_ "Description" SG_ 939 PSB_LHActvSta "Seat belt active state. This signal is for the monitoring of Pre-Safe S/Belt.

If there is a request, but no realization by the Pre-Safe S/Belt -> failure entry in the SCC(Radar).";
BA_ "UserSigValidity" SG_ 939 PSB_LHActvSta 0;
BA_ "Version" SG_ 939 PSB_LHActvSta "18.02.03";
BA_ "Description" SG_ 939 PSB_RHFlrSta "Information about availability of PSB_RH (LH Pre-Safe S/Belt).";
BA_ "UserSigValidity" SG_ 939 PSB_RHFlrSta 0;
BA_ "Version" SG_ 939 PSB_RHFlrSta "18.02.03";
BA_ "Description" SG_ 939 PSB_RHActvSta "Seat belt active state. This signal is for the monitoring of Pre-Safe S/Belt.

If there is a request, but no realization by the Pre-Safe S/Belt -> failure entry in the SCC(Radar).";
BA_ "UserSigValidity" SG_ 939 PSB_RHActvSta 0;
BA_ "Version" SG_ 939 PSB_RHActvSta "18.02.03";
BA_ "Description" SG_ 939 PSB_ActForAcu "This signal indicates status of Pre-Safe S/Belt activation by ACU commends.";
BA_ "UserSigValidity" SG_ 939 PSB_ActForAcu 0;
BA_ "Version" SG_ 939 PSB_ActForAcu "18.02.03";
BA_ "Description" SG_ 939 PSB_HapticWarnSta "This signal indicates sattus of Pre-active S/Belt Haptic activation by HDP commends";
BA_ "UserSigValidity" SG_ 939 PSB_HapticWarnSta 0;
BA_ "Version" SG_ 939 PSB_HapticWarnSta "20.03.00";
BA_ "Description" SG_ 939 PSB_RHActForPss "Seat belt active state. 

This signal is for the monitoring of Pre-Safe S/Belt  in conjunction with PSS.

If there is a request, but no realization by the Pre-Safe S/Belt -> failure entry in the SCC(Radar).";
BA_ "UserSigValidity" SG_ 939 PSB_RHActForPss 0;
BA_REL_ "GenSigTimeoutTime" BU_SG_REL_ APSM SG_ 939 PSB_RHActForPss 1500;
BA_REL_ "GenSigTimeoutTime" BU_SG_REL_ RLPSM SG_ 939 PSB_RHActForPss 1500;
BA_REL_ "GenSigTimeoutTime" BU_SG_REL_ RRPSM SG_ 939 PSB_RHActForPss 1500;
BA_ "Version" SG_ 939 PSB_RHActForPss "21.04.00";
BA_ "Description" SG_ 939 PSB_LHActForPss "Seat belt active state. 

This signal is for the monitoring of Pre-Safe S/Belt in conjunction with PSS.

If there is a request, but no realization by the Pre-Safe S/Belt -> failure entry in the SCC(Radar).";
BA_ "UserSigValidity" SG_ 939 PSB_LHActForPss 0;
BA_REL_ "GenSigTimeoutTime" BU_SG_REL_ RLPSM SG_ 939 PSB_LHActForPss 1500;
BA_REL_ "GenSigTimeoutTime" BU_SG_REL_ RRPSM SG_ 939 PSB_LHActForPss 1500;
BA_ "Version" SG_ 939 PSB_LHActForPss "21.04.00";
BA_ "GenMsgCycleTime" BO_ 1486 0;
BA_ "GenMsgCycleTimeFast" BO_ 1486 0;
BA_ "GenMsgNrOfRepetition" BO_ 1486 0;
BA_ "DiagResponse" BO_ 1486 1;
BA_ "GenMsgILSupport" BO_ 1486 0;
BA_ "TpMessage" BO_ 1486 1;
BA_ "TpTxIndex" BO_ 1486 218;
BA_ "Description" SG_ 1486 RLPSS_GST_Byte0 "TP Index : 218";
BA_ "UsrSigPurpose" SG_ 1486 RLPSS_GST_Byte0 4;
BA_ "UserSigValidity" SG_ 1486 RLPSS_GST_Byte0 0;
BA_REL_ "GenSigTimeoutTime" BU_SG_REL_ CGW_CCU SG_ 1486 RLPSS_GST_Byte0 0;
BA_ "NetworkRequest" SG_ 1486 RLPSS_GST_Byte0 0;
BA_ "NetworkRequestHoldingTime" SG_ 1486 RLPSS_GST_Byte0 5000;
BA_ "Version" SG_ 1486 RLPSS_GST_Byte0 "21.02.04";
BA_ "Description" SG_ 1486 RLPSS_GST_Byte2 "TP Index : 218";
BA_ "UsrSigPurpose" SG_ 1486 RLPSS_GST_Byte2 4;
BA_ "UserSigValidity" SG_ 1486 RLPSS_GST_Byte2 0;
BA_REL_ "GenSigTimeoutTime" BU_SG_REL_ CGW_CCU SG_ 1486 RLPSS_GST_Byte2 0;
BA_ "NetworkRequest" SG_ 1486 RLPSS_GST_Byte2 0;
BA_ "NetworkRequestHoldingTime" SG_ 1486 RLPSS_GST_Byte2 5000;
BA_ "Version" SG_ 1486 RLPSS_GST_Byte2 "21.02.04";
BA_ "Description" SG_ 1486 RLPSS_GST_Byte3 "TP Index : 218";
BA_ "UsrSigPurpose" SG_ 1486 RLPSS_GST_Byte3 4;
BA_ "UserSigValidity" SG_ 1486 RLPSS_GST_Byte3 0;
BA_REL_ "GenSigTimeoutTime" BU_SG_REL_ CGW_CCU SG_ 1486 RLPSS_GST_Byte3 0;
BA_ "NetworkRequest" SG_ 1486 RLPSS_GST_Byte3 0;
BA_ "NetworkRequestHoldingTime" SG_ 1486 RLPSS_GST_Byte3 5000;
BA_ "Version" SG_ 1486 RLPSS_GST_Byte3 "21.02.04";
BA_ "Description" SG_ 1486 RLPSS_GST_Byte4 "TP Index : 218";
BA_ "UsrSigPurpose" SG_ 1486 RLPSS_GST_Byte4 4;
BA_ "UserSigValidity" SG_ 1486 RLPSS_GST_Byte4 0;
BA_REL_ "GenSigTimeoutTime" BU_SG_REL_ CGW_CCU SG_ 1486 RLPSS_GST_Byte4 0;
BA_ "NetworkRequest" SG_ 1486 RLPSS_GST_Byte4 0;
BA_ "NetworkRequestHoldingTime" SG_ 1486 RLPSS_GST_Byte4 5000;
BA_ "Version" SG_ 1486 RLPSS_GST_Byte4 "21.02.04";
BA_ "Description" SG_ 1486 RLPSS_GST_Byte5 "TP Index : 218";
BA_ "UsrSigPurpose" SG_ 1486 RLPSS_GST_Byte5 4;
BA_ "UserSigValidity" SG_ 1486 RLPSS_GST_Byte5 0;
BA_REL_ "GenSigTimeoutTime" BU_SG_REL_ CGW_CCU SG_ 1486 RLPSS_GST_Byte5 0;
BA_ "NetworkRequest" SG_ 1486 RLPSS_GST_Byte5 0;
BA_ "NetworkRequestHoldingTime" SG_ 1486 RLPSS_GST_Byte5 5000;
BA_ "Version" SG_ 1486 RLPSS_GST_Byte5 "21.02.04";
BA_ "Description" SG_ 1486 RLPSS_GST_Byte6 "TP Index : 218";
BA_ "UsrSigPurpose" SG_ 1486 RLPSS_GST_Byte6 4;
BA_ "UserSigValidity" SG_ 1486 RLPSS_GST_Byte6 0;
BA_REL_ "GenSigTimeoutTime" BU_SG_REL_ CGW_CCU SG_ 1486 RLPSS_GST_Byte6 0;
BA_ "NetworkRequest" SG_ 1486 RLPSS_GST_Byte6 0;
BA_ "NetworkRequestHoldingTime" SG_ 1486 RLPSS_GST_Byte6 5000;
BA_ "Version" SG_ 1486 RLPSS_GST_Byte6 "21.02.04";
BA_ "Description" SG_ 1486 RLPSS_GST_Byte7 "TP Index : 218";
BA_ "UsrSigPurpose" SG_ 1486 RLPSS_GST_Byte7 4;
BA_ "UserSigValidity" SG_ 1486 RLPSS_GST_Byte7 0;
BA_REL_ "GenSigTimeoutTime" BU_SG_REL_ CGW_CCU SG_ 1486 RLPSS_GST_Byte7 0;
BA_ "NetworkRequest" SG_ 1486 RLPSS_GST_Byte7 0;
BA_ "NetworkRequestHoldingTime" SG_ 1486 RLPSS_GST_Byte7 5000;
BA_ "Version" SG_ 1486 RLPSS_GST_Byte7 "21.02.04";
BA_ "Description" SG_ 1486 RLPSS_GST_Byte1 "TP Index : 218";
BA_ "UsrSigPurpose" SG_ 1486 RLPSS_GST_Byte1 4;
BA_ "UserSigValidity" SG_ 1486 RLPSS_GST_Byte1 0;
BA_REL_ "GenSigTimeoutTime" BU_SG_REL_ CGW_CCU SG_ 1486 RLPSS_GST_Byte1 0;
BA_ "NetworkRequest" SG_ 1486 RLPSS_GST_Byte1 0;
BA_ "NetworkRequestHoldingTime" SG_ 1486 RLPSS_GST_Byte1 5000;
BA_ "Version" SG_ 1486 RLPSS_GST_Byte1 "21.02.04";
BA_ "GenMsgCycleTime" BO_ 1807 0;
BA_ "GenMsgCycleTimeFast" BO_ 1807 0;
BA_ "GenMsgNrOfRepetition" BO_ 1807 0;
BA_ "DiagResponse" BO_ 1807 1;
BA_ "GenMsgILSupport" BO_ 1807 0;
BA_ "TpMessage" BO_ 1807 1;
BA_ "TpTxIndex" BO_ 1807 165;
BA_ "Description" SG_ 1807 RRHVU_GST_Byte0 "TP Index : 165";
BA_ "UsrSigPurpose" SG_ 1807 RRHVU_GST_Byte0 4;
BA_ "UserSigValidity" SG_ 1807 RRHVU_GST_Byte0 0;
BA_REL_ "GenSigTimeoutTime" BU_SG_REL_ CGW_CCU SG_ 1807 RRHVU_GST_Byte0 0;
BA_ "NetworkRequest" SG_ 1807 RRHVU_GST_Byte0 0;
BA_ "NetworkRequestHoldingTime" SG_ 1807 RRHVU_GST_Byte0 5000;
BA_ "Version" SG_ 1807 RRHVU_GST_Byte0 "21.02.04";
BA_ "Description" SG_ 1807 RRHVU_GST_Byte2 "TP Index : 165";
BA_ "UsrSigPurpose" SG_ 1807 RRHVU_GST_Byte2 4;
BA_ "UserSigValidity" SG_ 1807 RRHVU_GST_Byte2 0;
BA_REL_ "GenSigTimeoutTime" BU_SG_REL_ CGW_CCU SG_ 1807 RRHVU_GST_Byte2 0;
BA_ "NetworkRequest" SG_ 1807 RRHVU_GST_Byte2 0;
BA_ "NetworkRequestHoldingTime" SG_ 1807 RRHVU_GST_Byte2 5000;
BA_ "Version" SG_ 1807 RRHVU_GST_Byte2 "21.02.04";
BA_ "Description" SG_ 1807 RRHVU_GST_Byte3 "TP Index : 165";
BA_ "UsrSigPurpose" SG_ 1807 RRHVU_GST_Byte3 4;
BA_ "UserSigValidity" SG_ 1807 RRHVU_GST_Byte3 0;
BA_REL_ "GenSigTimeoutTime" BU_SG_REL_ CGW_CCU SG_ 1807 RRHVU_GST_Byte3 0;
BA_ "NetworkRequest" SG_ 1807 RRHVU_GST_Byte3 0;
BA_ "NetworkRequestHoldingTime" SG_ 1807 RRHVU_GST_Byte3 5000;
BA_ "Version" SG_ 1807 RRHVU_GST_Byte3 "21.02.04";
BA_ "Description" SG_ 1807 RRHVU_GST_Byte4 "TP Index : 165";
BA_ "UsrSigPurpose" SG_ 1807 RRHVU_GST_Byte4 4;
BA_ "UserSigValidity" SG_ 1807 RRHVU_GST_Byte4 0;
BA_REL_ "GenSigTimeoutTime" BU_SG_REL_ CGW_CCU SG_ 1807 RRHVU_GST_Byte4 0;
BA_ "NetworkRequest" SG_ 1807 RRHVU_GST_Byte4 0;
BA_ "NetworkRequestHoldingTime" SG_ 1807 RRHVU_GST_Byte4 5000;
BA_ "Version" SG_ 1807 RRHVU_GST_Byte4 "21.02.04";
BA_ "Description" SG_ 1807 RRHVU_GST_Byte5 "TP Index : 165";
BA_ "UsrSigPurpose" SG_ 1807 RRHVU_GST_Byte5 4;
BA_ "UserSigValidity" SG_ 1807 RRHVU_GST_Byte5 0;
BA_REL_ "GenSigTimeoutTime" BU_SG_REL_ CGW_CCU SG_ 1807 RRHVU_GST_Byte5 0;
BA_ "NetworkRequest" SG_ 1807 RRHVU_GST_Byte5 0;
BA_ "NetworkRequestHoldingTime" SG_ 1807 RRHVU_GST_Byte5 5000;
BA_ "Version" SG_ 1807 RRHVU_GST_Byte5 "21.02.04";
BA_ "Description" SG_ 1807 RRHVU_GST_Byte6 "TP Index : 165";
BA_ "UsrSigPurpose" SG_ 1807 RRHVU_GST_Byte6 4;
BA_ "UserSigValidity" SG_ 1807 RRHVU_GST_Byte6 0;
BA_REL_ "GenSigTimeoutTime" BU_SG_REL_ CGW_CCU SG_ 1807 RRHVU_GST_Byte6 0;
BA_ "NetworkRequest" SG_ 1807 RRHVU_GST_Byte6 0;
BA_ "NetworkRequestHoldingTime" SG_ 1807 RRHVU_GST_Byte6 5000;
BA_ "Version" SG_ 1807 RRHVU_GST_Byte6 "21.02.04";
BA_ "Description" SG_ 1807 RRHVU_GST_Byte7 "TP Index : 165";
BA_ "UsrSigPurpose" SG_ 1807 RRHVU_GST_Byte7 4;
BA_ "UserSigValidity" SG_ 1807 RRHVU_GST_Byte7 0;
BA_REL_ "GenSigTimeoutTime" BU_SG_REL_ CGW_CCU SG_ 1807 RRHVU_GST_Byte7 0;
BA_ "NetworkRequest" SG_ 1807 RRHVU_GST_Byte7 0;
BA_ "NetworkRequestHoldingTime" SG_ 1807 RRHVU_GST_Byte7 5000;
BA_ "Version" SG_ 1807 RRHVU_GST_Byte7 "21.02.04";
BA_ "Description" SG_ 1807 RRHVU_GST_Byte1 "TP Index : 165";
BA_ "UsrSigPurpose" SG_ 1807 RRHVU_GST_Byte1 4;
BA_ "UserSigValidity" SG_ 1807 RRHVU_GST_Byte1 0;
BA_REL_ "GenSigTimeoutTime" BU_SG_REL_ CGW_CCU SG_ 1807 RRHVU_GST_Byte1 0;
BA_ "NetworkRequest" SG_ 1807 RRHVU_GST_Byte1 0;
BA_ "NetworkRequestHoldingTime" SG_ 1807 RRHVU_GST_Byte1 5000;
BA_ "Version" SG_ 1807 RRHVU_GST_Byte1 "21.02.04";
BA_ "GenMsgCycleTime" BO_ 1487 0;
BA_ "GenMsgCycleTimeFast" BO_ 1487 0;
BA_ "GenMsgNrOfRepetition" BO_ 1487 0;
BA_ "DiagResponse" BO_ 1487 1;
BA_ "GenMsgILSupport" BO_ 1487 0;
BA_ "TpMessage" BO_ 1487 1;
BA_ "TpTxIndex" BO_ 1487 219;
BA_ "Description" SG_ 1487 RRPSS_GST_Byte0 "TP Index : 219";
BA_ "UsrSigPurpose" SG_ 1487 RRPSS_GST_Byte0 4;
BA_ "UserSigValidity" SG_ 1487 RRPSS_GST_Byte0 0;
BA_REL_ "GenSigTimeoutTime" BU_SG_REL_ CGW_CCU SG_ 1487 RRPSS_GST_Byte0 0;
BA_ "NetworkRequest" SG_ 1487 RRPSS_GST_Byte0 0;
BA_ "NetworkRequestHoldingTime" SG_ 1487 RRPSS_GST_Byte0 5000;
BA_ "Version" SG_ 1487 RRPSS_GST_Byte0 "21.02.04";
BA_ "Description" SG_ 1487 RRPSS_GST_Byte2 "TP Index : 219";
BA_ "UsrSigPurpose" SG_ 1487 RRPSS_GST_Byte2 4;
BA_ "UserSigValidity" SG_ 1487 RRPSS_GST_Byte2 0;
BA_REL_ "GenSigTimeoutTime" BU_SG_REL_ CGW_CCU SG_ 1487 RRPSS_GST_Byte2 0;
BA_ "NetworkRequest" SG_ 1487 RRPSS_GST_Byte2 0;
BA_ "NetworkRequestHoldingTime" SG_ 1487 RRPSS_GST_Byte2 5000;
BA_ "Version" SG_ 1487 RRPSS_GST_Byte2 "21.02.04";
BA_ "Description" SG_ 1487 RRPSS_GST_Byte3 "TP Index : 219";
BA_ "UsrSigPurpose" SG_ 1487 RRPSS_GST_Byte3 4;
BA_ "UserSigValidity" SG_ 1487 RRPSS_GST_Byte3 0;
BA_REL_ "GenSigTimeoutTime" BU_SG_REL_ CGW_CCU SG_ 1487 RRPSS_GST_Byte3 0;
BA_ "NetworkRequest" SG_ 1487 RRPSS_GST_Byte3 0;
BA_ "NetworkRequestHoldingTime" SG_ 1487 RRPSS_GST_Byte3 5000;
BA_ "Version" SG_ 1487 RRPSS_GST_Byte3 "21.02.04";
BA_ "Description" SG_ 1487 RRPSS_GST_Byte4 "TP Index : 219";
BA_ "UsrSigPurpose" SG_ 1487 RRPSS_GST_Byte4 4;
BA_ "UserSigValidity" SG_ 1487 RRPSS_GST_Byte4 0;
BA_REL_ "GenSigTimeoutTime" BU_SG_REL_ CGW_CCU SG_ 1487 RRPSS_GST_Byte4 0;
BA_ "NetworkRequest" SG_ 1487 RRPSS_GST_Byte4 0;
BA_ "NetworkRequestHoldingTime" SG_ 1487 RRPSS_GST_Byte4 5000;
BA_ "Version" SG_ 1487 RRPSS_GST_Byte4 "21.02.04";
BA_ "Description" SG_ 1487 RRPSS_GST_Byte5 "TP Index : 219";
BA_ "UsrSigPurpose" SG_ 1487 RRPSS_GST_Byte5 4;
BA_ "UserSigValidity" SG_ 1487 RRPSS_GST_Byte5 0;
BA_REL_ "GenSigTimeoutTime" BU_SG_REL_ CGW_CCU SG_ 1487 RRPSS_GST_Byte5 0;
BA_ "NetworkRequest" SG_ 1487 RRPSS_GST_Byte5 0;
BA_ "NetworkRequestHoldingTime" SG_ 1487 RRPSS_GST_Byte5 5000;
BA_ "Version" SG_ 1487 RRPSS_GST_Byte5 "21.02.04";
BA_ "Description" SG_ 1487 RRPSS_GST_Byte6 "TP Index : 219";
BA_ "UsrSigPurpose" SG_ 1487 RRPSS_GST_Byte6 4;
BA_ "UserSigValidity" SG_ 1487 RRPSS_GST_Byte6 0;
BA_REL_ "GenSigTimeoutTime" BU_SG_REL_ CGW_CCU SG_ 1487 RRPSS_GST_Byte6 0;
BA_ "NetworkRequest" SG_ 1487 RRPSS_GST_Byte6 0;
BA_ "NetworkRequestHoldingTime" SG_ 1487 RRPSS_GST_Byte6 5000;
BA_ "Version" SG_ 1487 RRPSS_GST_Byte6 "21.02.04";
BA_ "Description" SG_ 1487 RRPSS_GST_Byte7 "TP Index : 219";
BA_ "UsrSigPurpose" SG_ 1487 RRPSS_GST_Byte7 4;
BA_ "UserSigValidity" SG_ 1487 RRPSS_GST_Byte7 0;
BA_REL_ "GenSigTimeoutTime" BU_SG_REL_ CGW_CCU SG_ 1487 RRPSS_GST_Byte7 0;
BA_ "NetworkRequest" SG_ 1487 RRPSS_GST_Byte7 0;
BA_ "NetworkRequestHoldingTime" SG_ 1487 RRPSS_GST_Byte7 5000;
BA_ "Version" SG_ 1487 RRPSS_GST_Byte7 "21.02.04";
BA_ "Description" SG_ 1487 RRPSS_GST_Byte1 "TP Index : 219";
BA_ "UsrSigPurpose" SG_ 1487 RRPSS_GST_Byte1 4;
BA_ "UserSigValidity" SG_ 1487 RRPSS_GST_Byte1 0;
BA_REL_ "GenSigTimeoutTime" BU_SG_REL_ CGW_CCU SG_ 1487 RRPSS_GST_Byte1 0;
BA_ "NetworkRequest" SG_ 1487 RRPSS_GST_Byte1 0;
BA_ "NetworkRequestHoldingTime" SG_ 1487 RRPSS_GST_Byte1 5000;
BA_ "Version" SG_ 1487 RRPSS_GST_Byte1 "21.02.04";
BA_ "GenMsgSendType" BO_ 858 0;
BA_ "Description" SG_ 858 SBCM_AST_Crc2Val "The data area for CRC calculation is based on the data length (DLC) of the message DB.

The CRC shall be calculated over the entire data block (excluding the CRC bytes) including the user data, alive counter and Data ID 

 

- CRC Polynomial (0x1D) , Initial Value : 0x00, XOR value : 0xFF, Data ID Mode : Both, Data ID : Message ID + 0xF800 

- The initial value is for CRC calculation and the message should be sent with the calculated result value. 

The mathematical expression to 8 bit CRC polynomial is given here. G(x) = x8 + x4 + x3 + x2 + 1";
BA_ "GenSigSendType" SG_ 858 SBCM_AST_Crc2Val 4;
BA_ "GenSigStartValue" SG_ 858 SBCM_AST_Crc2Val 255;
BA_ "UserSigValidity" SG_ 858 SBCM_AST_Crc2Val 0;
BA_ "Version" SG_ 858 SBCM_AST_Crc2Val "19.07.06";
BA_ "Description" SG_ 858 AST_CrashUnlockCmd "Assist Crash Unlock Command";
BA_ "GenSigSendType" SG_ 858 AST_CrashUnlockCmd 4;
BA_ "UserSigValidity" SG_ 858 AST_CrashUnlockCmd 0;
BA_ "NetworkRequest" SG_ 858 AST_CrashUnlockCmd 0;
BA_ "Version" SG_ 858 AST_CrashUnlockCmd "20.09.00";
BA_ "Description" SG_ 858 SBCM_AST_AlvCnt2Val "For the first transmission request for a data element the counter shall be initialized with 0 and shall be incremented by 1

for every subsequent send request. When the counter reaches the maximum value(0xE), then it shall restart with 0 for the next send request";
BA_ "GenSigSendType" SG_ 858 SBCM_AST_AlvCnt2Val 4;
BA_ "UserSigValidity" SG_ 858 SBCM_AST_AlvCnt2Val 0;
BA_ "Version" SG_ 858 SBCM_AST_AlvCnt2Val "19.07.06";
BA_ "Description" SG_ 858 DoorLock_CtrlDrLkSwSta_SBCM "Central Door Lock Assist Switch Status";
BA_ "GenSigSendType" SG_ 858 DoorLock_CtrlDrLkSwSta_SBCM 4;
BA_ "UserSigValidity" SG_ 858 DoorLock_CtrlDrLkSwSta_SBCM 0;
BA_ "NetworkRequest" SG_ 858 DoorLock_CtrlDrLkSwSta_SBCM 0;
BA_ "Version" SG_ 858 DoorLock_CtrlDrLkSwSta_SBCM "19.07.06";
BA_ "Description" SG_ 858 DoorLock_CtrlDrUnLkSwSta_SBCM "Central Door Unlock Assist Switch Status";
BA_ "GenSigSendType" SG_ 858 DoorLock_CtrlDrUnLkSwSta_SBCM 4;
BA_ "UserSigValidity" SG_ 858 DoorLock_CtrlDrUnLkSwSta_SBCM 0;
BA_ "NetworkRequest" SG_ 858 DoorLock_CtrlDrUnLkSwSta_SBCM 0;
BA_ "Version" SG_ 858 DoorLock_CtrlDrUnLkSwSta_SBCM "19.07.06";
BA_ "Description" SG_ 858 Warn_AsstDrSwSta_SBCM "Warning Assist Door Switch Status";
BA_ "GenSigSendType" SG_ 858 Warn_AsstDrSwSta_SBCM 4;
BA_ "UserSigValidity" SG_ 858 Warn_AsstDrSwSta_SBCM 0;
BA_REL_ "GenSigTimeoutTime" BU_SG_REL_ RWPC SG_ 858 Warn_AsstDrSwSta_SBCM 1500;
BA_REL_ "GenSigTimeoutTime" BU_SG_REL_ APSM SG_ 858 Warn_AsstDrSwSta_SBCM 1500;
BA_REL_ "GenSigTimeoutTime" BU_SG_REL_ AMP SG_ 858 Warn_AsstDrSwSta_SBCM 1500;
BA_REL_ "GenSigTimeoutTime" BU_SG_REL_ ATS SG_ 858 Warn_AsstDrSwSta_SBCM 1500;
BA_ "NetworkRequest" SG_ 858 Warn_AsstDrSwSta_SBCM 0;
BA_ "Version" SG_ 858 Warn_AsstDrSwSta_SBCM "19.07.06";
BA_ "Description" SG_ 858 DoorLock_AsstDrUnLkSta_SBCM "Assist Door Unlock Status";
BA_ "GenSigSendType" SG_ 858 DoorLock_AsstDrUnLkSta_SBCM 4;
BA_ "UserSigValidity" SG_ 858 DoorLock_AsstDrUnLkSta_SBCM 0;
BA_REL_ "GenSigTimeoutTime" BU_SG_REL_ ATS SG_ 858 DoorLock_AsstDrUnLkSta_SBCM 1500;
BA_ "NetworkRequest" SG_ 858 DoorLock_AsstDrUnLkSta_SBCM 0;
BA_ "Version" SG_ 858 DoorLock_AsstDrUnLkSta_SBCM "19.07.06";
BA_ "Description" SG_ 858 AST_SEAWarn_RH "Assist (FRH) SEA Warning";
BA_ "GenSigSendType" SG_ 858 AST_SEAWarn_RH 4;
BA_ "UserSigValidity" SG_ 858 AST_SEAWarn_RH 0;
BA_REL_ "GenSigTimeoutTime" BU_SG_REL_ AMP SG_ 858 AST_SEAWarn_RH 1500;
BA_ "NetworkRequest" SG_ 858 AST_SEAWarn_RH 0;
BA_ "Version" SG_ 858 AST_SEAWarn_RH "19.12.00";
BA_ "Description" SG_ 858 AST_SEAWarn_LH "Assist (FLH) Door SEA Warning";
BA_ "GenSigSendType" SG_ 858 AST_SEAWarn_LH 4;
BA_ "UserSigValidity" SG_ 858 AST_SEAWarn_LH 0;
BA_REL_ "GenSigTimeoutTime" BU_SG_REL_ AMP SG_ 858 AST_SEAWarn_LH 1500;
BA_ "NetworkRequest" SG_ 858 AST_SEAWarn_LH 0;
BA_ "Version" SG_ 858 AST_SEAWarn_LH "19.12.00";
BA_ "GenSigSendType" SG_ 858 AST_SEWWarn_LH 4;
BA_ "UserSigValidity" SG_ 858 AST_SEWWarn_LH 0;
BA_REL_ "GenSigTimeoutTime" BU_SG_REL_ AMP SG_ 858 AST_SEWWarn_LH 1500;
BA_ "NetworkRequest" SG_ 858 AST_SEWWarn_LH 0;
BA_ "Version" SG_ 858 AST_SEWWarn_LH "20.09.00";
BA_ "GenSigSendType" SG_ 858 AST_SEWWarn_RH 4;
BA_ "UserSigValidity" SG_ 858 AST_SEWWarn_RH 0;
BA_REL_ "GenSigTimeoutTime" BU_SG_REL_ AMP SG_ 858 AST_SEWWarn_RH 1500;
BA_ "NetworkRequest" SG_ 858 AST_SEWWarn_RH 0;
BA_ "Version" SG_ 858 AST_SEWWarn_RH "20.09.00";
BA_ "GenSigSendType" SG_ 858 AST_MRActivationAlarm 4;
BA_ "UserSigValidity" SG_ 858 AST_MRActivationAlarm 0;
BA_ "NetworkRequest" SG_ 858 AST_MRActivationAlarm 0;
BA_ "NetworkRequestHoldingTime" SG_ 858 AST_MRActivationAlarm 5000;
BA_ "Version" SG_ 858 AST_MRActivationAlarm "19.11.05";
BA_ "GenSigSendType" SG_ 858 AST_ReleaseWarn 4;
BA_ "UserSigValidity" SG_ 858 AST_ReleaseWarn 0;
BA_ "NetworkRequest" SG_ 858 AST_ReleaseWarn 0;
BA_ "NetworkRequestHoldingTime" SG_ 858 AST_ReleaseWarn 5000;
BA_ "Version" SG_ 858 AST_ReleaseWarn "19.11.05";
BA_ "GenSigSendType" SG_ 858 USM_AstGhostDoorSta 4;
BA_ "UserSigValidity" SG_ 858 USM_AstGhostDoorSta 0;
BA_ "NetworkRequest" SG_ 858 USM_AstGhostDoorSta 0;
BA_ "NetworkRequestHoldingTime" SG_ 858 USM_AstGhostDoorSta 5000;
BA_ "Version" SG_ 858 USM_AstGhostDoorSta "21.03.11";
BA_ "GenSigSendType" SG_ 858 AST_SWFailAlarm 4;
BA_ "UserSigValidity" SG_ 858 AST_SWFailAlarm 0;
BA_ "NetworkRequest" SG_ 858 AST_SWFailAlarm 0;
BA_ "NetworkRequestHoldingTime" SG_ 858 AST_SWFailAlarm 5000;
BA_ "Version" SG_ 858 AST_SWFailAlarm "19.11.05";
BA_ "GenSigSendType" SG_ 858 DoorLock_PDSLkSwSta_AST 4;
BA_ "UserSigValidity" SG_ 858 DoorLock_PDSLkSwSta_AST 0;
BA_REL_ "GenSigTimeoutTime" BU_SG_REL_ AMP SG_ 858 DoorLock_PDSLkSwSta_AST 1500;
BA_ "NetworkRequest" SG_ 858 DoorLock_PDSLkSwSta_AST 0;
BA_ "Version" SG_ 858 DoorLock_PDSLkSwSta_AST "19.12.00";
BA_ "GenSigSendType" SG_ 858 PDS_TypeOption_AST 4;
BA_ "UserSigValidity" SG_ 858 PDS_TypeOption_AST 0;
BA_ "NetworkRequest" SG_ 858 PDS_TypeOption_AST 0;
BA_ "Version" SG_ 858 PDS_TypeOption_AST "19.12.00";
BA_ "GenSigSendType" SG_ 858 ASTDoorPushAlarm 4;
BA_ "UserSigValidity" SG_ 858 ASTDoorPushAlarm 0;
BA_ "NetworkRequest" SG_ 858 ASTDoorPushAlarm 0;
BA_ "NetworkRequestHoldingTime" SG_ 858 ASTDoorPushAlarm 5000;
BA_ "Version" SG_ 858 ASTDoorPushAlarm "20.09.00";
BA_ "GenMsgSendType" BO_ 862 0;
BA_ "Description" SG_ 862 SBCM_RL_Crc1Val "The data area for CRC calculation is based on the data length (DLC) of the message DB.

The CRC shall be calculated over the entire data block (excluding the CRC bytes) including the user data, alive counter and Data ID 

 

- CRC Polynomial (0x1D) , Initial Value : 0x00, XOR value : 0xFF, Data ID Mode : Both, Data ID : Message ID + 0xF800 

- The initial value is for CRC calculation and the message should be sent with the calculated result value. 

The mathematical expression to 8 bit CRC polynomial is given here. G(x) = x8 + x4 + x3 + x2 + 1";
BA_ "GenSigSendType" SG_ 862 SBCM_RL_Crc1Val 4;
BA_ "GenSigStartValue" SG_ 862 SBCM_RL_Crc1Val 255;
BA_ "UserSigValidity" SG_ 862 SBCM_RL_Crc1Val 0;
BA_ "Version" SG_ 862 SBCM_RL_Crc1Val "19.07.06";
BA_ "Description" SG_ 862 RL_CrashUnlockCmd "RearLefrCrashUnlockCommand";
BA_ "GenSigSendType" SG_ 862 RL_CrashUnlockCmd 4;
BA_ "UserSigValidity" SG_ 862 RL_CrashUnlockCmd 0;
BA_ "NetworkRequest" SG_ 862 RL_CrashUnlockCmd 0;
BA_ "Version" SG_ 862 RL_CrashUnlockCmd "20.09.00";
BA_ "Description" SG_ 862 SBCM_RL_AlvCnt1Val "For the first transmission request for a data element the counter shall be initialized with 0 and shall be incremented by 1

for every subsequent send request. When the counter reaches the maximum value(0xE), then it shall restart with 0 for the next send request";
BA_ "GenSigSendType" SG_ 862 SBCM_RL_AlvCnt1Val 4;
BA_ "UserSigValidity" SG_ 862 SBCM_RL_AlvCnt1Val 0;
BA_ "Version" SG_ 862 SBCM_RL_AlvCnt1Val "19.07.06";
BA_ "Description" SG_ 862 Warn_RrLftDrSwSta_SBCM "Warning Rear Left Door Switch Status";
BA_ "GenSigSendType" SG_ 862 Warn_RrLftDrSwSta_SBCM 4;
BA_ "UserSigValidity" SG_ 862 Warn_RrLftDrSwSta_SBCM 0;
BA_REL_ "GenSigTimeoutTime" BU_SG_REL_ RWPC SG_ 862 Warn_RrLftDrSwSta_SBCM 1500;
BA_REL_ "GenSigTimeoutTime" BU_SG_REL_ RLPSM SG_ 862 Warn_RrLftDrSwSta_SBCM 1500;
BA_REL_ "GenSigTimeoutTime" BU_SG_REL_ AMP SG_ 862 Warn_RrLftDrSwSta_SBCM 1500;
BA_REL_ "GenSigTimeoutTime" BU_SG_REL_ ATS SG_ 862 Warn_RrLftDrSwSta_SBCM 1500;
BA_ "NetworkRequest" SG_ 862 Warn_RrLftDrSwSta_SBCM 0;
BA_ "Version" SG_ 862 Warn_RrLftDrSwSta_SBCM "19.07.06";
BA_ "Description" SG_ 862 DoorLock_RrLftDrUnLkSta_SBCM "Rear Left Door Unlock Status";
BA_ "GenSigSendType" SG_ 862 DoorLock_RrLftDrUnLkSta_SBCM 4;
BA_ "UserSigValidity" SG_ 862 DoorLock_RrLftDrUnLkSta_SBCM 0;
BA_REL_ "GenSigTimeoutTime" BU_SG_REL_ ATS SG_ 862 DoorLock_RrLftDrUnLkSta_SBCM 1500;
BA_ "NetworkRequest" SG_ 862 DoorLock_RrLftDrUnLkSta_SBCM 0;
BA_ "Version" SG_ 862 DoorLock_RrLftDrUnLkSta_SBCM "19.07.06";
BA_ "Description" SG_ 862 RL_SEAActivated "Rear Left SEA Activated";
BA_ "GenSigSendType" SG_ 862 RL_SEAActivated 4;
BA_ "UserSigValidity" SG_ 862 RL_SEAActivated 0;
BA_ "NetworkRequest" SG_ 862 RL_SEAActivated 0;
BA_ "Version" SG_ 862 RL_SEAActivated "19.07.06";
BA_ "Description" SG_ 862 RL_SEAWarn "RearLeftSEAWarning";
BA_ "GenSigSendType" SG_ 862 RL_SEAWarn 4;
BA_ "UserSigValidity" SG_ 862 RL_SEAWarn 0;
BA_REL_ "GenSigTimeoutTime" BU_SG_REL_ AMP SG_ 862 RL_SEAWarn 1500;
BA_ "NetworkRequest" SG_ 862 RL_SEAWarn 0;
BA_ "Version" SG_ 862 RL_SEAWarn "19.07.06";
BA_ "GenSigSendType" SG_ 862 RL_SEWWarn 4;
BA_ "UserSigValidity" SG_ 862 RL_SEWWarn 0;
BA_REL_ "GenSigTimeoutTime" BU_SG_REL_ AMP SG_ 862 RL_SEWWarn 1500;
BA_ "NetworkRequest" SG_ 862 RL_SEWWarn 0;
BA_ "Version" SG_ 862 RL_SEWWarn "20.09.00";
BA_ "GenSigSendType" SG_ 862 RL_ReleaseWarn 4;
BA_ "UserSigValidity" SG_ 862 RL_ReleaseWarn 0;
BA_ "NetworkRequest" SG_ 862 RL_ReleaseWarn 0;
BA_ "NetworkRequestHoldingTime" SG_ 862 RL_ReleaseWarn 5000;
BA_ "Version" SG_ 862 RL_ReleaseWarn "20.09.00";
BA_ "GenSigSendType" SG_ 862 RL_SWFailAlarm 4;
BA_ "UserSigValidity" SG_ 862 RL_SWFailAlarm 0;
BA_ "NetworkRequest" SG_ 862 RL_SWFailAlarm 0;
BA_ "NetworkRequestHoldingTime" SG_ 862 RL_SWFailAlarm 5000;
BA_ "Version" SG_ 862 RL_SWFailAlarm "20.09.00";
BA_ "GenSigSendType" SG_ 862 RL_ChildLock_ActnFlSta 4;
BA_ "UserSigValidity" SG_ 862 RL_ChildLock_ActnFlSta 0;
BA_ "NetworkRequest" SG_ 862 RL_ChildLock_ActnFlSta 0;
BA_ "NetworkRequestHoldingTime" SG_ 862 RL_ChildLock_ActnFlSta 5000;
BA_ "Version" SG_ 862 RL_ChildLock_ActnFlSta "19.11.05";
BA_ "GenSigSendType" SG_ 862 RL_MRActivationAlarm 4;
BA_ "UserSigValidity" SG_ 862 RL_MRActivationAlarm 0;
BA_ "NetworkRequest" SG_ 862 RL_MRActivationAlarm 0;
BA_ "NetworkRequestHoldingTime" SG_ 862 RL_MRActivationAlarm 5000;
BA_ "Version" SG_ 862 RL_MRActivationAlarm "19.11.05";
BA_ "GenSigSendType" SG_ 862 RL_ChildLock_Status 4;
BA_ "UserSigValidity" SG_ 862 RL_ChildLock_Status 0;
BA_ "NetworkRequest" SG_ 862 RL_ChildLock_Status 0;
BA_ "NetworkRequestHoldingTime" SG_ 862 RL_ChildLock_Status 5000;
BA_ "Version" SG_ 862 RL_ChildLock_Status "21.03.01";
BA_ "GenSigSendType" SG_ 862 USM_RLGhostDoorSta 4;
BA_ "UserSigValidity" SG_ 862 USM_RLGhostDoorSta 0;
BA_ "NetworkRequest" SG_ 862 USM_RLGhostDoorSta 0;
BA_ "NetworkRequestHoldingTime" SG_ 862 USM_RLGhostDoorSta 5000;
BA_ "Version" SG_ 862 USM_RLGhostDoorSta "21.03.11";
BA_ "GenSigSendType" SG_ 862 DoorLock_PDSLkSwSta_RL 4;
BA_ "UserSigValidity" SG_ 862 DoorLock_PDSLkSwSta_RL 0;
BA_REL_ "GenSigTimeoutTime" BU_SG_REL_ AMP SG_ 862 DoorLock_PDSLkSwSta_RL 1500;
BA_ "NetworkRequest" SG_ 862 DoorLock_PDSLkSwSta_RL 0;
BA_ "Version" SG_ 862 DoorLock_PDSLkSwSta_RL "19.12.00";
BA_ "GenSigSendType" SG_ 862 PDS_TypeOption_RL 4;
BA_ "UserSigValidity" SG_ 862 PDS_TypeOption_RL 0;
BA_ "NetworkRequest" SG_ 862 PDS_TypeOption_RL 0;
BA_ "Version" SG_ 862 PDS_TypeOption_RL "19.12.00";
BA_ "GenSigSendType" SG_ 862 SBCM_RrLtClsSwSta 4;
BA_ "UserSigValidity" SG_ 862 SBCM_RrLtClsSwSta 0;
BA_ "NetworkRequest" SG_ 862 SBCM_RrLtClsSwSta 0;
BA_ "NetworkRequestHoldingTime" SG_ 862 SBCM_RrLtClsSwSta 5000;
BA_ "Version" SG_ 862 SBCM_RrLtClsSwSta "21.07.07";
BA_ "GenSigSendType" SG_ 862 RLDoorPushAlarm 4;
BA_ "UserSigValidity" SG_ 862 RLDoorPushAlarm 0;
BA_ "NetworkRequest" SG_ 862 RLDoorPushAlarm 0;
BA_ "NetworkRequestHoldingTime" SG_ 862 RLDoorPushAlarm 5000;
BA_ "Version" SG_ 862 RLDoorPushAlarm "20.09.00";
VAL_ 2281835009 ACU_SysWrngLmpDis 0 "Warning Lamp off" 1 "Warning Lamp on" 2 "Warning Lamp flash" 3 "Reserved" 4 "Reserved" 5 "Reserved" 6 "Not used" 7 "Error Indicator" ;
VAL_ 2281835009 ACU_TlltlLmpDis 0 "ON Lamp off OFF Lamp off" 1 "ON Lamp off  OFF Lamp on" 2 "ON Lamp on OFF Lamp off" 3 "ON Lamp on OFF Lamp on" 4 "Reserved" 5 "Reserved" 6 "Reserved" 7 "Error Indicator" ;
VAL_ 2281835009 ACU_OdsIDReq 0 "Request to send ODS Identifier" 1 "Acknowledgement for the Correct ODS Identifier Received" 2 "Not used" 3 "Error Indicator" ;
VAL_ 2281835009 SeatBelt_PassBcklFltSta 0 "No Fault" 1 "Fault condition exists" 2 "Not used" 3 "Error Indicator" ;
VAL_ 2281835009 SeatBelt_DrvrBcklFltSta 0 "No Fault" 1 "Fault condition exists" 2 "Not used" 3 "Error Indicator" ;
VAL_ 2281835009 SeatBelt_PassBcklSta 0 "Passenger Seat Belt Not Latched" 1 "Passenger Seat Belt Latched" 2 "Not used" 3 "Error Indicator" ;
VAL_ 2281835009 SeatBelt_DrvrBcklSta 0 "Driver Seat Belt Not Latched" 1 "Driver Seat Belt Latched" 2 "Not used" 3 "Error Indicator" ;
VAL_ 2281835010 ACU_ActvFltSta 0 "Fault status is active" 1 "Fault status is historic" 2 "Fault does not exist" 3 "Reserved" 4 "Reserved" 5 "Reserved" 6 "Not used" 7 "Error Indicator" ;
VAL_ 2281835010 ACU_SdArbgExtTyp 0 "Side(or Side/Curtain) Airbag doesn't exist." 1 "Side(or Side/Curtain) Airbag exists." 2 "ACU EOL Programming Mode" 3 "Reserved" 4 "Reserved" 5 "Reserved" 6 "Not used" 7 "Error Indicator" ;
VAL_ 2281835010 ACU_EmerModSta 0 "ACU is NOT Emergency mode" 1 "ACU is Emergency mode" ;
VAL_ 2281835010 ACU_EvtTrigSta 0 "EDR Not triggered." 1 "EDR triggered." ;
VAL_ 2239851009 RSPA_AvnDis 0 "init" 1 "No display" 2 "RSPA 화면 출력" 3 "invalid" ;
VAL_ 2239851009 RSPA_AvnModDis 0 "init" 1 "주차모드" 2 "출차모드" 3 "invalid" ;
VAL_ 2239851009 RSPA_AvnModNumDis 0 "init" 1 "2모드" 2 "4모드" 3 "6모드" 4 "8모드" 5 "reserved" 6 "reserved" 7 "invalid" ;
VAL_ 2239851009 RSPA_AvnSubViewDis 0 "init" 1 "No display" 2 "대체이미지 출력" 3 "invalid" ;
VAL_ 2239851009 RSPA_AvnModPLDis 0 "init" 1 "제어불가능" 2 "제어가능" 3 "invalid" ;
VAL_ 2239851009 RSPA_AvnModPDRLDis 0 "init" 1 "제어불가능" 2 "제어가능" 3 "invalid" ;
VAL_ 2239851009 RSPA_AvnModPDRRDis 0 "init" 1 "제어불가능" 2 "제어가능" 3 "invalid" ;
VAL_ 2239851009 RSPA_AvnModPRDis 0 "init" 1 "제어불가능" 2 "제어가능" 3 "invalid" ;
VAL_ 2239851009 RSPA_CamDis 0 "No Display (RSPA 연동 해제)" 1 "AVM (뷰 메뉴바 미표시) 와이드뷰 블랙+탑뷰 / RVM:View OFF" 2 "AVM (뷰 메뉴바 미표시) 와이드뷰 전방+탑뷰 / RVM:Parking Assist View (Guide L. X)" 3 "AVM (뷰 메뉴바 미표시) 와이드뷰 후방+탑뷰 / RVM:Parking Assist View (Guide L. O)" 4 "reserved" 5 "reserved" 6 "reserved" 7 "Invalid" ;
VAL_ 2239851009 RSPA_AvnHmiDis 0 "none" 1 "Select operating mode" 2 "SMART Parking" 3 "REMOTE Parking" 4 "Parking completed" 5 "SMART Pull-out" 6 "Pull-out completed" 7 "RSPA cancelled - Read Manual" 8 "RSPA cancelled - Operate vehicle manually" 9 "Not working condition - Exceed Limit Speed" 10 "Searching for Parking space - Reduce speed under 20km" 11 "Check RSPA - Visit Tech Center" 12 "Reserved" 13 "display Front camera - moving forward" 14 "display Rear camera - moving backward" 15 "Reserved" 16 "RSPA paused - Check tailgate closed" 17 "RSPA paused - Remote control range exceeded" 18 "RSPA pasued - Hold down dedicated button on key fob" 19 "Parking completed - manually" 20 "Pull-out completed - manually" 21 "Reserved" 22 "RSPA paused - Check all doors closed" 23 "RSPA paused - Check trunk closed" 24 "RSPA paused - RCCW" 25 "RSPA paused - Fasten seat belt on drivers side" 26 "Operation guide - Release brake" 27 "RSPA paused - Monitor surrounding area" 28 "RSPA cancelled - Trailer mode" 29 "RSPA cancelled - PDW Off" 30 "RSPA cancelled - over 20km" 31 "RSPA cancelled - not stop" 32 "RSPA cancelled - reverse movement" 33 "RSPA cancelled - narrow space" 34 "Not working condition - trailer mode" 35 "RSPA cancelled - Monitor surrounding area" 36 "RSPA cancelled - Check road condition" 37 "RSPA cancelled - Exceed operating distance" 38 "RSPA cancelled - Exceed operation time" 39 "RSPA cancelled - Detect cancel input" 40 "RSPA cancelled - Detect remote start button input" 41 "RSPA cancelled - Detect B" 42 "RSPA cancelled - Detect unfasten S" 43 "RSPA cancelled - Detect T" 44 "RSPA cancelled - Detect EPB operation" 45 "RSPA cancelled - Detect Pedal operation" 46 "RSPA cancelled - Hood open" 47 "RSPA cancelled - Detect S" 48 "RSPA cancelled - USS blockage" 49 "RSPA cancelled - Check SVM Camera" 50 "Reserved" 51 "Reserved" 52 "Reserved" 53 "Reserved" 54 "Reserved" 55 "Reserved" 56 "Reserved" 57 "Reserved" 58 "Reserved" 59 "Reserved" 60 "Reserved" 61 "Reserved" 62 "Reserved" 63 "Reserved" 64 "Reserved" 65 "Reserved" 66 "Reserved" 67 "Reserved" 68 "Reserved" 69 "Reserved" 70 "Reserved" 71 "Reserved" 72 "Reserved" 73 "Reserved" 74 "Reserved" 75 "Reserved" 76 "Reserved" 77 "Reserved" 78 "Reserved" 79 "Reserved" 80 "Reserved" 81 "Reserved" 82 "Reserved" 83 "Reserved" 84 "Reserved" 85 "Reserved" 86 "Reserved" 87 "Reserved" 88 "Reserved" 89 "Reserved" 90 "Reserved" 91 "Reserved" 92 "Reserved" 93 "Reserved" 94 "Reserved" 95 "Reserved" 96 "Reserved" 97 "Reserved" 98 "Reserved" 99 "Reserved" 100 "Reserved" 101 "Reserved" 102 "Reserved" 103 "Reserved" 104 "Reserved" 105 "Reserved" 106 "Reserved" 107 "Reserved" 108 "Reserved" 109 "Reserved" 110 "Reserved" 111 "Reserved" 112 "Reserved" 113 "Reserved" 114 "Reserved" 115 "Reserved" 116 "Reserved" 117 "Reserved" 118 "Reserved" 119 "Reserved" 120 "Reserved" 121 "Reserved" 122 "Reserved" 123 "Reserved" 124 "Reserved" 125 "Reserved" 126 "Reserved" 127 "Reserved" 128 "Searching for Parking space - Drive forwards" 129 "Searching Completed - Stop vehicle to park or Move forward" 130 "Select parking mode" 131 "Checking space - Stop the vehicle to check space" 132 "Checking completed - Select pull-out mode" 133 "Remote Moving F" 134 "under Remote Control" 135 "Remote Moving F" 136 "Operation guide - Reinput Parking Button" 137 "Operation guide - Reinput SMART Key Button" 138 "Not working condition - Read Manual" 139 "Not working condition - Steep road slope up" 140 "Not working condition - Steep road slope down" 141 "RSPA cancelled - Steep road slope up" 142 "RSPA cancelled - Steep road slope down" 143 "Not working condition - USS blockage" 144 "RSPA Guide Pop - up" 145 "RSPA cancelled ? DCT overtemp" 146 "Not working condition ? DCT overtemp" 147 "Checking Completed - Remote exit control" 148 "0x94~0xFE:Reserved" 254 "0x94~0xFE:Reserved" 255 "Invalid" ;
VAL_ 2239851010 RSPA_Var 0 "init" 1 "RSPA (ENTRY)" 2 "RSPA" 3 "RSPA II" 4 "Reserved" 5 "Reserved" 6 "Reserved" 7 "Reserved" 8 "Reserved" 9 "Reserved" 10 "Reserved" 11 "Reserved" 12 "Reserved" 13 "Reserved" 14 "Reserved" 15 "Invalid" ;
VAL_ 2239851010 RSPA_Sta 0 "RSPA not recognized" 1 "Init" 2 "New Start" 3 "Ready OK" 4 "Assist Req" 5 "Assist OK" 6 "Assist Fail" 7 "Abort" 8 "Ready Fail" ;
VAL_ 2239851010 RSPA_Actv 0 "RSPA Off" 1 "RSPA On" 2 "Reserved" 3 "Reserved" ;
VAL_ 2239851010 RSPA_EvasiveStrBtnDis 0 "Initial" 1 "Do not display evasive steering on/off button" 2 "Display evasive steering on/off button" 3 "Invalid" ;
VAL_ 2239851011 RSPA_TrgtGearSta 0 "Idle" 1 "P" 2 "R" 3 "N" 4 "D" ;
VAL_ 2239851011 RSPA_IdOutWarnReq 0 "No Request" 1 "Change Request" 2 "Not Used" 3 "Error Indicator" ;
VAL_ 2239851011 RSPA_IndBlnkReq 0 "No request" 1 "Type1" 2 "Type2" 3 "Type3" 4 "Type4" 5 "Type5" 6 "Reserved" 7 "Reserved" ;
VAL_ 2239851011 RSPA_SysOff 0 "default" 1 "system off" ;
VAL_ 2239851011 RSPA_DccCmd 0 "No request" 1 "Soft Brake" 2 "Hard 1 Brake" 3 "Hard 2 Brake" ;
VAL_ 2239851011 RSPA_StopReq 0 "No request" 1 "Stop control is required" 2 "Not Used" 3 "Error Indicator" ;
VAL_ 2239851011 RSPA_SelDevInfo 0 "default" 1 "SmartPhone" 2 "Fob" 3 "Reserved" ;
VAL_ 2239851011 RSPA_SelFuncInfo 0 "default" 1 "Parking" 2 "Remote Forward/Backward" 3 "Reserved" ;
VAL_ 2239851011 RSPA_EpbReq 0 "No request" 1 "release request" 2 "normal apply" ;
VAL_ 2239851011 RSPA_AddtnlAccelActv 0 "Inactive" 1 "Active" 2 "Not Used" 3 "Error Indicator" ;
VAL_ 2239851011 RSPA_Opt 0 "RSPA not applied" 1 "RSPA applied" 2 "Not Used" 3 "Error Indicator" ;
VAL_ 2239851011 RSPA_RmtPrlExitDis 0 "Initial" 1 "Do not display remote parallel exit" 2 "Display remote parallel exit" 3 "Invalid" ;
VAL_ 2239851011 RSPA_ExtLampReq 0 "Inactive (No Request)" 1 "Hazard Lamp Active On" 2 "Hazard Lamp Active Off" 3 "Left Turn Signal On" 4 "Right Turn Signal On" 5 "reserved" 6 "reserved" 7 "reserved" ;
VAL_ 2239851011 RSPA_UppLtTypDis 0 "init" 1 "Not found" 2 "Reverse perpendicular" 3 "Reverse parallel" 4 "Reverse diagonal" 5 "Forward diagonal" 6 "Reserved" 7 "Invalid" ;
VAL_ 2239851011 RSPA_LwrLtTypDis 0 "init" 1 "Not found" 2 "Reverse perpendicular" 3 "Reverse parallel" 4 "Reverse diagonal" 5 "Forward diagonal" 6 "Reserved" 7 "Invalid" ;
VAL_ 2239851011 RSPA_UppRtTypDis 0 "init" 1 "Not found" 2 "Reverse perpendicular" 3 "Reverse parallel" 4 "Reverse diagonal" 5 "Forward diagonal" 6 "Reserved" 7 "Invalid" ;
VAL_ 2239851011 RSPA_LwrRtTypDis 0 "init" 1 "Not found" 2 "Reverse perpendicular" 3 "Reverse parallel" 4 "Reverse diagonal" 5 "Forward diagonal" 6 "Reserved" 7 "Invalid" ;
VAL_ 2239851011 RSPA_CrankingReq 0 "Init" 1 "to RSPA Remote Cranking" 2 "to Normal Cranking" 3 "to IG OFF" ;
VAL_ 2239851012 RSPA_HdLmpReq 0 "Initial (Inactive)" 1 "HeadLamp On" 2 "Not Used" 3 "Error Indicator" ;
VAL_ 2239851012 RSPA_OSMirFoldReq 0 "Off" 1 "OS Mirror Fold" 2 "OS Mirror Unfold" 3 "Invalid" ;
VAL_ 2382594305 DATC_RrDrvTempCDis 0 "Blank Display" 1 "'LO' Display" 254 "'HI' Display" 255 "Error Indicator" ;
VAL_ 2382594305 DATC_RrDrvTempFDis 0 "Blank Display" 1 "'LO' Display" 254 "'HI' Display" 255 "Error Indicator" ;
VAL_ 2424580609 DATC_MltAutoBlrTxt 0 "Default" 1 "Blank" 2 "LOW" 3 "MEDIUM" 4 "HIGH" 5 "Reserved" 6 "Reserved" 7 "ErrorIndicaor" ;
VAL_ 2424580609 DATC_MltAutoBlrTxt_Ps 0 "Default" 1 "Blank" 2 "LOW" 3 "MEDIUM" 4 "HIGH" 5 "Reserved" 6 "Reserved" 7 "ErrorIndicaor" ;
VAL_ 2424580609 DATC_MltAutoBlrTxt_Rr 0 "Default" 1 "Blank" 2 "LOW" 3 "MEDIUM" 4 "HIGH" 5 "Reserved" 6 "Reserved" 7 "ErrorIndicaor" ;
VAL_ 2424580609 DATC_RLStTmblrSwReq 0 "Default" 1 "Up" 2 "Down" 3 "Error Indicator" ;
VAL_ 2424580609 DATC_RRStTmblrSwReq 0 "Default" 1 "Up" 2 "Down" 3 "Error Indicator" ;
VAL_ 2424580609 DATC_Opt5Typ 0 "applied options (See Description)" 1 "applied options (See Description)" 2 "applied options (See Description)" 3 "applied options (See Description)" 4 "applied options (See Description)" 5 "applied options (See Description)" 6 "applied options (See Description)" 7 "applied options (See Description)" 8 "applied options (See Description)" 9 "applied options (See Description)" 10 "applied options (See Description)" 11 "applied options (See Description)" 12 "applied options (See Description)" 13 "applied options (See Description)" 14 "applied options (See Description)" 15 "applied options (See Description)" ;
VAL_ 367 FPM2IAU_ISKLearnFdbck 0 "Default" 1 "Positive" 2 "Mismatch ISK(HPV)" 3 "Mismatch RN(PSK)" 4 "Save Failed ISK" 5 "Time Out" 6 "Not Learnt" 7 "Reserved" 8 "Reserved" 9 "Reserved" 10 "Reserved" 11 "Reserved" 12 "Reserved" 13 "Reserved" 14 "Reserved" 15 "Invalid" ;
VAL_ 399 FPM_FPStartAuthResult 0 "Default" 1 "FPFail_Driver1PIN" 2 "FPFail_Driver2PIN" 3 "FPFail_Driver1n2PIN" 4 "reserved" 5 "reserved" 6 "reserved" 7 "Invalid" ;
VAL_ 399 FPM_ISKLearnFB 0 "Default(Normal)" 1 "Positive" 2 "Mismatch HPV" 3 "Mismatch PSK" 4 "Save Failed ISK" 5 "Time out" 6 "Not Learnt" 7 "Negative" 8 "reserved" 9 "reserved" 10 "reserved" 11 "reserved" 12 "reserved" 13 "reserved" 14 "reserved" 15 "Invalid" ;
VAL_ 399 FPM_USMDispPopup 0 "None" 1 "No 1 fob key inside" 2 "No 2 fob keys inside" 3 "reserved" 4 "reserved" 5 "reserved" 6 "reserved" 7 "reserved" 8 "reserved" 9 "reserved" 10 "reserved" 11 "reserved" 12 "reserved" 13 "reserved" 14 "reserved" 15 "Invalid" ;
VAL_ 415 FPM_FPFuntionEnableRValue 0 "Default" 1 "Disable" 2 "Enable" 3 "Invalid" ;
VAL_ 415 FPM_User2_SecondFPRValue 0 "Default" 1 "Disable" 2 "Enable" 3 "Invalid" ;
VAL_ 415 FPM_User2_ThirdFPRValue 0 "Default" 1 "Disable" 2 "Enable" 3 "Invalid" ;
VAL_ 415 FPM_FPEnrollState 0 "None" 1 "Touch" 2 "Lift" 3 "Adjust Position" 4 "Try Touch Again" 5 "Processing" 6 "Completed" 7 "Failed" 8 "Fail_Recog_SamePosition" 9 "Fail_Recog_WrongPosition" 10 "Fail_Recog_TooFast" 11 "Fail_Recog_TooSmallArea" 12 "Fail_Recog_Something" 13 "reserved" 14 "reserved" 15 "Invalid" ;
VAL_ 415 FPM_User1_FirstFPRValue 0 "Default" 1 "Disable" 2 "Enable" 3 "Invalid" ;
VAL_ 415 FPM_FPDeleteState 0 "None" 1 "Deleting" 2 "Completed" 3 "Failed" ;
VAL_ 415 FPM_EnrollProgress 255 "Enroll Progress ASCII Value (HEX)" ;
VAL_ 415 FPM_ISKLearnState 0 "Default" 1 "Virgin" 2 "Learning" 3 "Learnt" 4 "Neutralizing" 5 "Neutralized" 6 "reserved" 7 "Invalid" ;
VAL_ 415 FPM_ReadyToSendData 0 "None" 1 "Ready to Send data" 2 "Reserved" 3 "Invalid" ;
VAL_ 415 FPM_Option 0 "NotApplied" 1 "Applied" 2 "Reserved" 3 "Invalid" ;
VAL_ 415 FPM_User1_SecondFPRValue 0 "Default" 1 "Disable" 2 "Enable" 3 "Invalid" ;
VAL_ 415 FPMwIAULearnState 0 "Default (virgin)" 1 "Virgin" 2 "Learning" 3 "Learnt" 4 "Neutralizing" 5 "Neutralized" 6 "reserved" 7 "Invalid" ;
VAL_ 415 FPM_DISPWrng 0 "Default(None)" 1 "FP limited for 1min" 2 "FP limited for 2min" 3 "FP limited for 3min" 4 "FP limited for 4min" 5 "FP limited for 5min" 6 "FP limited for 6min" 7 "FP limited for 7min" 8 "FP limited for 8min" 9 "FP limited for 9min" 10 "FP limited for 10min" 11 "FPStartRecog_Success" 12 "FPStartRecog_Fail" 13 "reserved" 14 "reserved" 15 "reserved" 16 "reserved" 17 "reserved" 18 "reserved" 19 "reserved" 20 "reserved" 21 "reserved" 22 "reserved" 23 "reserved" 24 "reserved" 25 "reserved" 26 "reserved" 27 "reserved" 28 "reserved" 29 "reserved" 30 "reserved" 31 "Invalid" ;
VAL_ 415 FPM2IAU_RdyToSendAuthData 0 "None" 1 "Ready to Send data" 2 "Reserved" 3 "Invalid" ;
VAL_ 415 FPM_FPStartUseRvalue 0 "Default" 1 "Disable" 2 "Enable" 3 "Invalid" ;
VAL_ 415 FPM_FPStartUseState 0 "Default" 1 "FPstart_disable" 2 "FPstart_enable" 3 "Invalid" ;
VAL_ 415 FPM_User1_ThirdFPRValue 0 "Default" 1 "Disable" 2 "Enable" 3 "Invalid" ;
VAL_ 415 FPM_User2_FirstFPRValue 0 "Default" 1 "Disable" 2 "Enable" 3 "Invalid" ;
VAL_ 2319620609 HUD_PbackSta 0 "Stop" 1 "Play 1" 2 "Play 2" 3 "Health Care IMS" 4 "Profile1" 5 "Profile2" 6 "Guest" 7 "Invalid" ;
VAL_ 2563126273 AMP_NaviVolumeStep 0 "0x0x0~0xFD:Navi Volume" 253 "0x0x0~0xFD:Navi Volume" 254 "Req. amp supported Navi Set" 255 "Invalid" ;
VAL_ 2563126273 ATS_BeepVolumeStep 0 "0x0x0~0xFE:ATS Beep Volume" 254 "0x0x0~0xFE:ATS Beep Volume" 255 "Invalid" ;
VAL_ 2563126273 ATS_BeepFrequency 20 "0x0x14~0x4E20:Valid for Hz step" 20000 "0x0x14~0x4E20:Valid for Hz step" 65535 "Invalid" ;
VAL_ 2563126273 AMP_ESEVMasterGain 0 "Reserved" 1 "Reserved" 2 "Reserved" 3 "MasterGain" 4 "MasterGain" 5 "MasterGain" 6 "MasterGain" 7 "MasterGain" 8 "MasterGain" 9 "MasterGain" 10 "MasterGain" 11 "MasterGain" 12 "MasterGain" 13 "MasterGain" 14 "MasterGain" 15 "MasterGain" 16 "MasterGain" 17 "MasterGain" 18 "MasterGain" 19 "MasterGain" 20 "MasterGain" 21 "MasterGain" 22 "MasterGain" 23 "MasterGain" 24 "MasterGain" 25 "MasterGain" 26 "MasterGain" 27 "MasterGain" 28 "Reserved" 29 "Reserved" 30 "Reserved" 31 "Invalid" ;
VAL_ 2563126273 AMP_NaviVoice_Priority 0 "Navi Voice Priority Off" 1 "Navi Voice Priority ON" 2 "Unused" 3 "Invalid" ;
VAL_ 2563126273 AMP_ESEVMode 0 "Not use" 1 "ASD OFF" 2 "Reserved" 3 "ASD ON" 4 "Reserved" 5 "Reserved" 6 "Reserved" 7 "Invalid" ;
VAL_ 2563126273 ATS_Beep_OutputCh_Select 65535 "Invaild" ;
VAL_ 2563127809 AMP_PESSAPSSet 0 "Type 0" 1 "Type 1 (Default)" 2 "Type 2" 3 "Reserved" 4 "Reserved" 5 "Reserved" 6 "Reserved" 7 "Invalid" ;
VAL_ 2563127809 AMP_PESSDesignSet_New 0 "Type 0 (Default)" 1 "Type 1" 2 "Type 2" 3 "Type 3" 4 "Type 4" 5 "Type 5" 6 "Type 6" 7 "Type 7" 8 "Type 8" 9 "Invalid" ;
VAL_ 2563127809 AMP_PESSCANSet 0 "Type 0" 1 "Type 1" 2 "Type 2" 3 "Reserved" 4 "Reserved" 5 "Reserved" 6 "Reserved" 7 "Invaild" ;
VAL_ 2563127809 AMP_WalkieTalkieMode 0 "Walkie Talkie Off" 1 "Walkie Talkie On" 2 "Reserved" 3 "Invalid" ;
VAL_ 2563127809 AMP_WalkieTalkieVolumeStep 0 "0x0x0~0xFE:WalkieTalkie Volume" 254 "0x0x0~0xFE:WalkieTalkie Volume" 255 "Invalid" ;
VAL_ 2563127809 AMP_WalkieTalkie_OutputCh_Sel 0 "0x0x0~0xFFFE:OutputChSel (Refer the signal description)" 65534 "0x0x0~0xFFFE:OutputChSel (Refer the signal description)" 65535 "Invalid" ;
VAL_ 2563127809 AMP_PESSMode 0 "PESS OFF" 1 "PESS ON (Default)" 2 "PESS Check" 3 "Invalid" ;
VAL_ 2563127809 AMP_PESSVolumeSet 0 "Min Value" 1 "Values" 2 "Values" 3 "Values" 4 "Values" 5 "Values" 6 "Values" 7 "Values" 8 "Values" 9 "Values" 10 "Values" 11 "Values" 12 "Values" 13 "Values" 14 "Values" 15 "Values" 16 "Values" 17 "Values" 18 "Values" 19 "Values" 20 "Max Value" 21 "0x15~0xFE:reserved" 254 "0x15~0xFE:reserved" 255 "Invalid" ;
VAL_ 2298626305 C_AstBolsterInfSw_HU 0 "Default" 1 "Off" 2 "On" 3 "Invalid" ;
VAL_ 2298626305 C_RLHrestUpSw_HU 0 "Default" 1 "Off" 2 "On" 3 "Invalid" ;
VAL_ 2298626305 C_RLHrestDnSw_HU 0 "Default" 1 "Off" 2 "On" 3 "Invalid" ;
VAL_ 2298626305 C_RLHrestFwdSw_HU 0 "Default" 1 "Off" 2 "On" 3 "Invalid" ;
VAL_ 2298626305 C_AstBolsterDefSw_HU 0 "Default" 1 "Off" 2 "On" 3 "Invalid" ;
VAL_ 2298626305 C_RLHrestBwdSw_HU 0 "Default" 1 "Off" 2 "On" 3 "Invalid" ;
VAL_ 2298626305 C_RLLumbarUpSw_HU 0 "Default" 1 "Off" 2 "On" 3 "Invalid" ;
VAL_ 2298626305 C_RLLumbarMidSw_HU 0 "Default" 1 "Off" 2 "On" 3 "Invalid" ;
VAL_ 2298626305 C_RLLumbarLowSw_HU 0 "Default" 1 "Off" 2 "On" 3 "Invalid" ;
VAL_ 2298626305 C_RLLumbarDefSw_HU 0 "Default" 1 "Off" 2 "On" 3 "Invalid" ;
VAL_ 2298626305 C_RLBolsterInfSw_HU 0 "Default" 1 "Off" 2 "On" 3 "Invalid" ;
VAL_ 2298626305 C_RLBolsterDefSw_HU 0 "Default" 1 "Off" 2 "On" 3 "Invalid" ;
VAL_ 2298626305 C_AstHrestUpSw_HU 0 "Default" 1 "Off" 2 "On" 3 "Invalid" ;
VAL_ 2298626305 C_AstHrestDnSw_HU 0 "Default" 1 "Off" 2 "On" 3 "Invalid" ;
VAL_ 2298626305 C_AstFootrestFldSw_HU 0 "Default" 1 "Off" 2 "On" 3 "Invalid" ;
VAL_ 2298626305 C_AstHrestFwdSw_HU 0 "Default" 1 "Off" 2 "On" 3 "Invalid" ;
VAL_ 2298626305 C_AstHrestBwdSw_HU 0 "Default" 1 "Off" 2 "On" 3 "Invalid" ;
VAL_ 2298626305 C_AstFootrestUnFldSw_HU 0 "Default" 1 "Off" 2 "On" 3 "Invalid" ;
VAL_ 2458165505 C_AstWindowCmdAVN 0 "No action" 1 "Manual Down" 2 "Manual Up" 3 "25% Open" 4 "50%Open" 5 "Auto Down" 6 "Auto Up" 7 "15% Open" 8 "Unused" 9 "Unused" 10 "Unused" 11 "Unused" 12 "Unused" 13 "Unused" 14 "Unused" 15 "Invalid" ;
VAL_ 2458165505 C_TrunkTlgtCmdAVN 0 "Off" 1 "Open(Release)" 2 "Reserved" 3 "Invalid" ;
VAL_ 2458165505 C_StrgWhlHeatedCmdAVN 0 "Off" 1 "Heat 1st ON" 2 "Reserved" 3 "Invalid" ;
VAL_ 2458165505 C_RrDefoggerCmdAVN 0 "Off" 1 "On" 2 "Reserved" 3 "Invalid" ;
VAL_ 2458165505 C_RRWindowCmdAVN 0 "No action" 1 "Manual Down" 2 "Manual Up" 3 "25% Open" 4 "50% Open" 5 "Auto Down" 6 "Auto Up" 7 "15% Open" 8 "Unused" 9 "Unused" 10 "Unused" 11 "Unused" 12 "Unused" 13 "Unused" 14 "Unused" 15 "Invalid" ;
VAL_ 2458165505 C_RLWindowCmdAVN 0 "No action" 1 "Manual Down" 2 "Manual Up" 3 "25% Open" 4 "50% Open" 5 "Auto Down" 6 "Auto UP" 7 "15% Open" 8 "Unused" 9 "Unused" 10 "Unused" 11 "Unused" 12 "Unused" 13 "Unused" 14 "Unused" 15 "Invalid" ;
VAL_ 2458165505 C_BlindCmdAVN 0 "No Action" 1 "R_Blind Auto Open" 2 "R_Blind Auto Close" 3 "Stop" 4 "reserved" 5 "reserved" 6 "reserved" 7 "Invalid" ;
VAL_ 2458165505 C_GlassCmdAVN 0 "No Action" 1 "Glass Auto Open" 2 "Glass Auto Close" 3 "Glass Auto Tilt Up" 4 "Stop" 5 "reserved" 6 "reserved" 7 "Invalid" ;
VAL_ 2458165505 C_DrvWindowCmdAVN 0 "No action" 1 "Manual Down" 2 "Manual Up" 3 "25% Open" 4 "50% Open" 5 "Auto Down" 6 "Auto Up" 7 "15% Open" 8 "Unused" 9 "Unused" 10 "Unused" 11 "Unused" 12 "Unused" 13 "Unused" 14 "Unused" 15 "Invalid" ;
VAL_ 2458165505 C_ThemeCmdAVN 0 "Default" 1 "Theme1" 2 "Theme2" 3 "Theme3" 4 "Reserved" 5 "Reserved" 6 "Reserved" 7 "Invalid" ;
VAL_ 2458165505 C_CluDispCmdAVN 0 "No Action" 1 "Oil consumption" 2 "Speed" 3 "TBT" 4 "Reserved" 5 "Reserved" 6 "Reserved" 7 "Invalid" ;
VAL_ 2458165505 HU_FRSeatHeatVRcmd 0 "Init" 1 "Unused" 2 "Seat Heat&Vent OFF" 3 "Seat_Vent_Low" 4 "Seat_Vent_Mid" 5 "Seat_Vent_High" 6 "Seat_Heat_Low" 7 "Seat_Heat_Mid" 8 "Seat_Heat_High" 9 "Unused" 10 "Unused" 11 "Unused" 12 "Unused" 13 "Unused" 14 "Unused" 15 "Invalid" ;
VAL_ 2458165505 HU_FLSeatHeatVRcmd 0 "Init" 1 "Unused" 2 "Seat Heat&Vent OFF" 3 "Seat_Vent_Low" 4 "Seat_Vent_Mid" 5 "Seat_Vent_High" 6 "Seat_Heat_Low" 7 "Seat_Heat_Mid" 8 "Seat_Heat_High" 9 "Unused" 10 "Unused" 11 "Unused" 12 "Unused" 13 "Unused" 14 "Unused" 15 "Invalid" ;
VAL_ 2458165505 C_PTGCNTLCmdAVN 0 "Close" 1 "Open" 2 "Reserved" 3 "Invalid" ;
VAL_ 2479158017 RSELockOnOff 0 "Unlock" 1 "LockOn" 2 "Reserved" 3 "Invalid" ;
VAL_ 2479158017 HU_DATC_DisplayThemes 0 "Default" 1 "White Theme" 2 "Black Theme" 3 "Invalid" ;
VAL_ 2479158017 HU_DATC_RearLockSet 0 "Not Used" 1 "Rear Lock Off" 2 "Rear Lock On" 3 "Invalid" ;
VAL_ 2479158017 HU_PhoneActivity 0 "Deactivated" 1 "Activated" 2 "reserved" 3 "Invalid" ;
VAL_ 2479158017 HU_VRActivity 0 "Deactivated" 1 "Activated" 2 "reserved" 3 "Invalid" ;
VAL_ 2336415489 CF_AVN_FpLpRedNValueSet 0 "0x0x000~0x0FF:0-255" 255 "0x0x000~0x0FF:0-255" 256 "Default" 257 "0x101~0x1FE:RESERVED" 510 "0x101~0x1FE:RESERVED" 511 "Invalid" ;
VAL_ 2336415489 CF_AVN_FpLpBlueNValueSet 0 "0x0x000~0x0FF:0-255" 255 "0x0x000~0x0FF:0-255" 256 "Default" 257 "0x101~0x1FE:RESERVED" 510 "0x101~0x1FE:RESERVED" 511 "Invalid" ;
VAL_ 2336415489 CF_AVN_FpLpCtrlNvalueSet 0 "Default" 1 "Off" 2 "On" 3 "Dimming1" 4 "Dimming2" 5 "Dimming3" 6 "Blink1" 7 "Blink2" 8 "Blink3" 9 "RESERVED" 10 "RESERVED" 11 "RESERVED" 12 "RESERVED" 13 "RESERVED" 14 "RESERVED" 15 "Invalid" ;
VAL_ 2336415489 CF_AVN_FpLpGreenNValueSet 0 "0x0x000~0x0FF:0-255" 255 "0x0x000~0x0FF:0-255" 256 "Default" 257 "0x101~0x1FE:RESERVED" 510 "0x101~0x1FE:RESERVED" 511 "Invalid" ;
VAL_ 939 PSB_LHFlrSta 0 "No failure" 1 "Failure, Service Required" 2 "Defect, PSB warning light off" 3 "Signal not valid" ;
VAL_ 939 PSB_LHActvSta 0 "No PSB motor activation" 1 "PSB retract cycle active" 2 "Reserved" 3 "Reserved" ;
VAL_ 939 PSB_RHFlrSta 0 "No failure" 1 "Failure, Service Required" 2 "Defect, PSB warning light off" 3 "Signal not valid" ;
VAL_ 939 PSB_RHActvSta 0 "No PSB motor activation" 1 "PSB retract cycle active" 2 "Reserved" 3 "Reserved" ;
VAL_ 939 PSB_ActForAcu 0 "Inactive" 1 "Active" 2 "Reserved" 3 "Failure" ;
VAL_ 939 PSB_HapticWarnSta 0 "No PSB activation" 1 "PSB Haptic active-1st step" 2 "PSB Haptic active-2nd step" 3 "Reserved" ;
VAL_ 939 PSB_RHActForPss 0 "No PSB motor activation" 1 "PSB retract cycle active" 2 "Reserved" 3 "Reserved" ;
VAL_ 939 PSB_LHActForPss 0 "No PSB motor activation" 1 "PSB retract cycle active" 2 "Reserved" 3 "Reserved" ;
VAL_ 858 AST_CrashUnlockCmd 0 "Off" 1 "Unlock (Crash)" ;
VAL_ 858 DoorLock_CtrlDrLkSwSta_SBCM 0 "Off" 1 "On (Lock On)" 2 "Not Used" 3 "Error Indicator" ;
VAL_ 858 DoorLock_CtrlDrUnLkSwSta_SBCM 0 "Off" 1 "On (Unlock On)" 2 "Not Used" 3 "Error Indicator" ;
VAL_ 858 Warn_AsstDrSwSta_SBCM 0 "Close" 1 "Open" 2 "Not Used" 3 "Error Indicator" ;
VAL_ 858 DoorLock_AsstDrUnLkSta_SBCM 0 "Lock" 1 "Unlock" 2 "Not Used" 3 "Error Indicator" ;
VAL_ 858 AST_SEAWarn_RH 0 "SEA Right Warning OFF" 1 "SEA Right Warning ON" 2 "Reserved" 3 "Invalid" ;
VAL_ 858 AST_SEAWarn_LH 0 "SEA Left Warning OFF" 1 "SEA Left Warning ON" 2 "Reserved" 3 "Invalid" ;
VAL_ 858 AST_SEWWarn_LH 0 "SEW Left Warning OFF" 1 "SEW Left Warning ON" 2 "Reserved" 3 "Invalid" ;
VAL_ 858 AST_SEWWarn_RH 0 "SEW Right Warning OFF" 1 "SEW Right Warning ON" 2 "Reserved" 3 "Invalid" ;
VAL_ 858 AST_MRActivationAlarm 0 "Off" 1 "On" 2 "Not Used" 3 "Error Indicator" ;
VAL_ 858 AST_ReleaseWarn 0 "Release Warning OFF" 1 "Release Warning ON" 2 "Reserved" 3 "Invalid" ;
VAL_ 858 USM_AstGhostDoorSta 0 "Default" 1 "Off" 2 "On" 3 "Invalid" ;
VAL_ 858 AST_SWFailAlarm 0 "Off" 1 "On" 2 "Not Used" 3 "Error Indicator" ;
VAL_ 858 DoorLock_PDSLkSwSta_AST 0 "Lock" 1 "Unlock" 2 "Not Used" 3 "Error Indicator" ;
VAL_ 858 PDS_TypeOption_AST 0 "Off" 1 "On" 2 "Not Used" 3 "Error Indicator" ;
VAL_ 858 ASTDoorPushAlarm 0 "Off" 1 "On" 2 "Not Used" 3 "Error Indicator" ;
VAL_ 862 RL_CrashUnlockCmd 0 "Off" 1 "Unlock(Crash)" ;
VAL_ 862 Warn_RrLftDrSwSta_SBCM 0 "Close" 1 "Open" 2 "Not Used" 3 "Error Indicator" ;
VAL_ 862 DoorLock_RrLftDrUnLkSta_SBCM 0 "Lock" 1 "Unlock" 2 "Not Used" 3 "Error Indicator" ;
VAL_ 862 RL_SEAActivated 0 "InActivated" 1 "Activated" 2 "Not Used" 3 "Error Indicator" ;
VAL_ 862 RL_SEAWarn 0 "SEA Left Warning OFF" 1 "SEA Left Warning ON" 2 "Reserved" 3 "Invalid" ;
VAL_ 862 RL_SEWWarn 0 "SEW Left Warning OFF" 1 "SEW Left Warning ON" 2 "Reserved" 3 "InvalidInvalid" ;
VAL_ 862 RL_ReleaseWarn 0 "Release Warning OFF" 1 "Release Warning ON" 2 "Reserved" 3 "Invalid" ;
VAL_ 862 RL_SWFailAlarm 0 "Off" 1 "On" 2 "Not Used" 3 "Error Indicator" ;
VAL_ 862 RL_ChildLock_ActnFlSta 0 "OK" 1 "Failed" 2 "Not Used" 3 "Error Indicator" ;
VAL_ 862 RL_MRActivationAlarm 0 "Off" 1 "On" 2 "Not Used" 3 "Error Indicator" ;
VAL_ 862 RL_ChildLock_Status 0 "ChildLock On" 1 "ChildLock Off" 2 "Reserved" 3 "Not Used" ;
VAL_ 862 USM_RLGhostDoorSta 0 "Default" 1 "Off" 2 "On" 3 "Invalid" ;
VAL_ 862 DoorLock_PDSLkSwSta_RL 0 "Lock" 1 "Unlock" 2 "Not Used" 3 "Error Indicator" ;
VAL_ 862 PDS_TypeOption_RL 0 "Off" 1 "On" 2 "Not Used" 3 "Error Indicator" ;
VAL_ 862 SBCM_RrLtClsSwSta 0 "Default" 1 "On" 2 "Off" 3 "RESERVED" ;
VAL_ 862 RLDoorPushAlarm 0 "Off" 1 "On" 2 "Not Used" 3 "Error Indicator" ;
